VERSION ""

NS_ :

BS_:

BU_: IDC Delete_FDCA Delete_APA Delete_CMRR_FL Delete_CMRR_FR CMRR_RL CMRR_RR MRR CGW

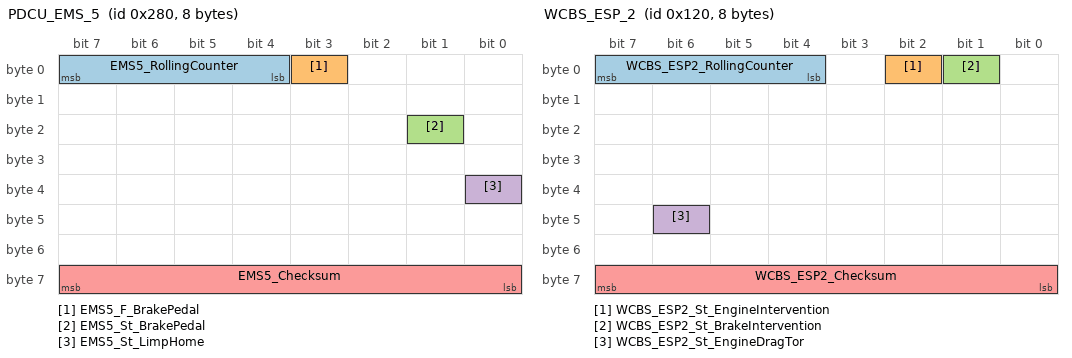
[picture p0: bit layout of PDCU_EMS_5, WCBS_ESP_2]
BO_ 640 PDCU_EMS_5: 8 CGW
 SG_ EMS5_RollingCounter : 7|4@0+ (1,0) [0|15] "" IDC,Delete_APA,Delete_CMRR_FL,Delete_CMRR_FR,CMRR_RL,CMRR_RR,MRR
 SG_ EMS5_F_BrakePedal : 3|1@0+ (1,0) [0|1] "" IDC,Delete_FDCA,Delete_APA,Delete_CMRR_FL,Delete_CMRR_FR,CMRR_RL,CMRR_RR,MRR
 SG_ EMS5_St_BrakePedal : 17|1@0+ (1,0) [0|1] "" IDC,Delete_FDCA,Delete_APA,Delete_CMRR_FL,Delete_CMRR_FR,CMRR_RL,CMRR_RR,MRR
 SG_ EMS5_St_LimpHome : 32|1@0+ (1,0) [0|1] "" IDC,Delete_FDCA
 SG_ EMS5_Checksum : 63|8@0+ (1,0) [0|255] "" IDC,Delete_APA,Delete_CMRR_FL,Delete_CMRR_FR,CMRR_RL,CMRR_RR,MRR

BO_ 792 WCBS_ESP_1: 8 CGW
 SG_ WCBS_ESP1_St_AutoHoldAvailable : 7|1@0+ (1,0) [0|1] "" IDC,Delete_FDCA,Delete_APA
 SG_ WCBS_ESP1_St_AutoHold : 6|1@0+ (1,0) [0|1] "" IDC,Delete_FDCA,Delete_APA
 SG_ WCBS_ESP1_St_AutoHoldTelltale : 5|1@0+ (1,0) [0|1] "" IDC,Delete_FDCA
 SG_ WCBS_ESP1_Cmd_EPBPark : 4|2@0+ (1,0) [0|3] "" IDC,Delete_APA
 SG_ WCBS_ESP1_St_TCSActive : 2|1@0+ (1,0) [0|1] "" IDC,Delete_FDCA,Delete_APA,Delete_CMRR_FL,Delete_CMRR_FR,CMRR_RL,CMRR_RR,MRR
 SG_ WCBS_ESP1_St_BrakeLightControl : 1|1@0+ (1,0) [0|1] "" IDC,Delete_APA
 SG_ WCBS_ESP1_St_ABSActive : 0|1@0+ (1,0) [0|1] "" IDC,Delete_FDCA,Delete_APA,Delete_CMRR_FL,Delete_CMRR_FR,CMRR_RL,CMRR_RR,MRR
 SG_ WCBS_ESP1_St_EBDActive : 15|1@0+ (1,0) [0|1] "" IDC,Delete_APA
 SG_ WCBS_ESP1_St_ESPFailureTelltale : 14|1@0+ (1,0) [0|1] "" IDC,Delete_APA,Delete_CMRR_FL,Delete_CMRR_FR,CMRR_RL,CMRR_RR,MRR
 SG_ WCBS_ESP1_St_ESPTCSOffTelltale : 13|2@0+ (1,0) [0|3] "" IDC,Delete_FDCA,Delete_APA,Delete_CMRR_FL,Delete_CMRR_FR,CMRR_RL,CMRR_RR,MRR
 SG_ WCBS_ESP1_St_DecelerationActive : 11|1@0+ (1,0) [0|1] "" IDC,Delete_FDCA
 SG_ WCBS_ESP1_St_ABSTelltale : 23|1@0+ (1,0) [0|1] "" IDC,Delete_FDCA
 SG_ WCBS_ESP1_St_EBDTelltale : 22|1@0+ (1,0) [0|1] "" IDC,Delete_FDCA
 SG_ WCBS_ESP1_St_ESPActive : 21|1@0+ (1,0) [0|1] "" IDC,Delete_FDCA,Delete_APA,Delete_CMRR_FL,Delete_CMRR_FR,CMRR_RL,CMRR_RR,MRR
 SG_ WCBS_ESP1_St_ESPTCSActiveTelltale : 20|1@0+ (1,0) [0|1] "" IDC,Delete_APA
 SG_ WCBS_ESP1_St_HDCTelltale : 17|2@0+ (1,0) [0|3] "" IDC,Delete_FDCA,Delete_APA,Delete_CMRR_FL,Delete_CMRR_FR,CMRR_RL,CMRR_RR,MRR
 SG_ WCBS_ESP1_N_OdometerRoll : 31|16@0+ (1,0) [0|65535] "pulses" IDC,Delete_APA
 SG_ WCBS_ESP1_St_WCBSFault : 47|2@0+ (1,0) [0|3] "" IDC,Delete_APA,Delete_CMRR_FL,Delete_CMRR_FR,CMRR_RL,CMRR_RR,MRR
 SG_ WCBS_ESP1_St_BrakeFluidW : 45|1@0+ (1,0) [0|1] "" IDC,Delete_APA
 SG_ WCBS_ESP1_RollingCounter : 55|4@0+ (1,0) [0|15] "" IDC,Delete_FDCA,Delete_APA,Delete_CMRR_FL,Delete_CMRR_FR,CMRR_RL,CMRR_RR,MRR
 SG_ WCBS_ESP1_Checksum : 63|8@0+ (1,0) [0|255] "" IDC,Delete_FDCA,Delete_APA,Delete_CMRR_FL,Delete_CMRR_FR,CMRR_RL,CMRR_RR,MRR

BO_ 288 WCBS_ESP_2: 8 CGW
 SG_ WCBS_ESP2_RollingCounter : 7|4@0+ (1,0) [0|15] "" IDC,Delete_FDCA
 SG_ WCBS_ESP2_St_EngineIntervention : 2|1@0+ (1,0) [0|1] "" IDC,Delete_FDCA
 SG_ WCBS_ESP2_St_BrakeIntervention : 1|1@0+ (1,0) [0|1] "" IDC,Delete_FDCA
 SG_ WCBS_ESP2_St_EngineDragTor : 46|1@0+ (1,0) [0|1] "" IDC,Delete_FDCA
 SG_ WCBS_ESP2_Checksum : 63|8@0+ (1,0) [0|255] "" IDC,Delete_FDCA

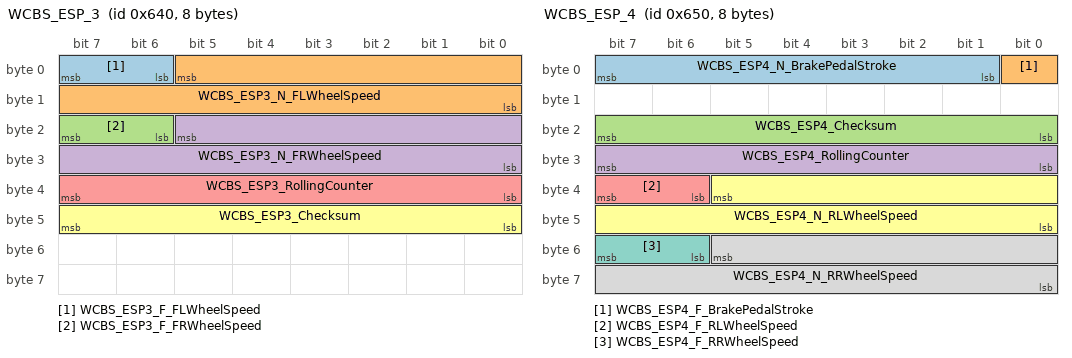
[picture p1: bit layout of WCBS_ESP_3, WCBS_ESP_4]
BO_ 1600 WCBS_ESP_3: 8 CGW
 SG_ WCBS_ESP3_F_FLWheelSpeed : 7|2@0+ (1,0) [0|3] "" IDC,Delete_FDCA,Delete_APA,Delete_CMRR_FL,Delete_CMRR_FR,CMRR_RL,CMRR_RR,MRR,Vector__XXX
 SG_ WCBS_ESP3_N_FLWheelSpeed : 5|14@0+ (0.0625,0) [0|300] "km/h" IDC,Delete_FDCA,Delete_APA,Delete_CMRR_FL,Delete_CMRR_FR,CMRR_RL,CMRR_RR,MRR,Vector__XXX
 SG_ WCBS_ESP3_F_FRWheelSpeed : 23|2@0+ (1,0) [0|3] "" IDC,Delete_FDCA,Delete_APA,Delete_CMRR_FL,Delete_CMRR_FR,CMRR_RL,CMRR_RR,MRR,Vector__XXX
 SG_ WCBS_ESP3_N_FRWheelSpeed : 21|14@0+ (0.0625,0) [0|300] "km/h" IDC,Delete_FDCA,Delete_APA,Delete_CMRR_FL,Delete_CMRR_FR,CMRR_RL,CMRR_RR,MRR,Vector__XXX
 SG_ WCBS_ESP3_RollingCounter : 39|8@0+ (1,0) [0|255] "" IDC,Delete_FDCA,Delete_APA,Delete_CMRR_FL,Delete_CMRR_FR,CMRR_RL,CMRR_RR,MRR,Vector__XXX
 SG_ WCBS_ESP3_Checksum : 47|8@0+ (1,0) [0|255] "" IDC,Delete_FDCA,Delete_APA,Delete_CMRR_FL,Delete_CMRR_FR,CMRR_RL,CMRR_RR,MRR,Vector__XXX

BO_ 1616 WCBS_ESP_4: 8 CGW
 SG_ WCBS_ESP4_N_BrakePedalStroke : 7|7@0+ (1,-5) [-5|108] "mm" IDC,Delete_FDCA,Delete_CMRR_FL,Delete_CMRR_FR,CMRR_RL,CMRR_RR,MRR
 SG_ WCBS_ESP4_F_BrakePedalStroke : 0|1@0+ (1,0) [0|1] "" IDC,Delete_FDCA,Delete_CMRR_FL,Delete_CMRR_FR,CMRR_RL,CMRR_RR,MRR
 SG_ WCBS_ESP4_Checksum : 23|8@0+ (1,0) [0|255] "" IDC,Delete_FDCA,Delete_APA,Delete_CMRR_FL,Delete_CMRR_FR,CMRR_RL,CMRR_RR,MRR,Vector__XXX
 SG_ WCBS_ESP4_RollingCounter : 31|8@0+ (1,0) [0|255] "" IDC,Delete_FDCA,Delete_APA,Delete_CMRR_FL,Delete_CMRR_FR,CMRR_RL,CMRR_RR,MRR,Vector__XXX
 SG_ WCBS_ESP4_F_RLWheelSpeed : 39|2@0+ (1,0) [0|3] "" IDC,Delete_FDCA,Delete_APA,Delete_CMRR_FL,Delete_CMRR_FR,CMRR_RL,CMRR_RR,MRR,Vector__XXX
 SG_ WCBS_ESP4_N_RLWheelSpeed : 37|14@0+ (0.0625,0) [0|300] "km/h" IDC,Delete_FDCA,Delete_APA,Delete_CMRR_FL,Delete_CMRR_FR,CMRR_RL,CMRR_RR,MRR,Vector__XXX
 SG_ WCBS_ESP4_F_RRWheelSpeed : 55|2@0+ (1,0) [0|3] "" IDC,Delete_FDCA,Delete_APA,Delete_CMRR_FL,Delete_CMRR_FR,CMRR_RL,CMRR_RR,MRR,Vector__XXX
 SG_ WCBS_ESP4_N_RRWheelSpeed : 53|14@0+ (0.0625,0) [0|300] "km/h" IDC,Delete_FDCA,Delete_APA,Delete_CMRR_FL,Delete_CMRR_FR,CMRR_RL,CMRR_RR,MRR,Vector__XXX

BO_ 785 WCBS_ESP_5: 8 CGW
 SG_ WCBS_ESP5_St_VehicleStandstill : 7|2@0+ (1,0) [0|3] "" IDC,Delete_FDCA,Delete_APA,Delete_CMRR_FL,Delete_CMRR_FR,CMRR_RL,CMRR_RR,MRR
 SG_ WCBS_ESP5_St_APAVLC : 5|4@0+ (1,0) [0|15] "" IDC,Delete_APA
 SG_ WCBS_ESP5_St_APACDDActive : 1|1@0+ (1,0) [0|1] "" IDC
 SG_ WCBS_ESP5_St_GearInhit : 0|1@0+ (1,0) [0|1] "" IDC,Delete_FDCA,Delete_APA
 SG_ WCBS_ESP5_RollingCounter : 12|4@0+ (1,0) [0|15] "" IDC,Delete_FDCA,Delete_APA,Delete_CMRR_FL,Delete_CMRR_FR,CMRR_RL,CMRR_RR,MRR
 SG_ WCBS_ESP5_F_VehicleSpeed : 8|1@0+ (1,0) [0|1] "" IDC,Delete_FDCA,Delete_APA,Delete_CMRR_FL,Delete_CMRR_FR,CMRR_RL,CMRR_RR,MRR
 SG_ WCBS_ESP5_St_APACDDAv : 23|1@0+ (1,0) [0|1] "" IDC,Delete_APA
 SG_ WCBS_ESP5_St_NoBrakeForce : 22|1@0+ (1,0) [0|1] "" IDC,Delete_FDCA
 SG_ WCBS_ESP5_St_ACCCDDActive : 21|1@0+ (1,0) [0|1] "" IDC,Delete_FDCA
 SG_ WCBS_ESP5_St_ACCCDDAv : 20|1@0+ (1,0) [0|1] "" IDC,Delete_FDCA
 SG_ WCBS_ESP5_St_ABAactive : 19|1@0+ (1,0) [0|1] "" IDC,Delete_FDCA
 SG_ WCBS_ESP5_St_ABAavailable : 18|1@0+ (1,0) [0|1] "" IDC,Delete_FDCA
 SG_ WCBS_ESP5_St_PrefillActive : 17|1@0+ (1,0) [0|1] "" IDC,Delete_FDCA,Delete_CMRR_FL,Delete_CMRR_FR,CMRR_RL,CMRR_RR,MRR
 SG_ WCBS_ESP5_St_PrefillAvailable : 16|1@0+ (1,0) [0|1] "" IDC,Delete_FDCA,Delete_CMRR_FL,Delete_CMRR_FR,CMRR_RL,CMRR_RR,MRR
 SG_ WCBS_ESP5_St_AEBdecActive : 31|1@0+ (1,0) [0|1] "" IDC,Delete_FDCA,Delete_CMRR_FL,Delete_CMRR_FR,CMRR_RL,CMRR_RR,MRR
 SG_ WCBS_ESP5_St_AEBdecAv : 30|1@0+ (1,0) [0|1] "" IDC,Delete_FDCA,Delete_CMRR_FL,Delete_CMRR_FR,CMRR_RL,CMRR_RR,MRR
 SG_ WCBS_ESP5_St_DecSupportAc : 29|1@0+ (1,0) [0|1] "" IDC,Delete_FDCA
 SG_ WCBS_ESP5_St_DecSupportAv : 28|1@0+ (1,0) [0|1] "" IDC,Delete_FDCA
 SG_ WCBS_ESP5_AWBactive : 27|1@0+ (1,0) [0|1] "" IDC,Delete_FDCA,Delete_CMRR_FL,Delete_CMRR_FR,CMRR_RL,CMRR_RR,MRR
 SG_ WCBS_ESP5_AWBavailable : 26|1@0+ (1,0) [0|1] "" IDC,Delete_FDCA,Delete_CMRR_FL,Delete_CMRR_FR,CMRR_RL,CMRR_RR,MRR
 SG_ WCBS_ESP5_QDCFail : 25|1@0+ (1,0) [0|1] "" IDC,Delete_FDCA
 SG_ WCBS_ESP5_BrakeOverheat : 24|1@0+ (1,0) [0|1] "" IDC,Delete_FDCA
 SG_ WCBS_ESP5_N_VehicleSpeed : 39|13@0+ (0.05625,0) [0|259.9875] "km/h" IDC,Delete_FDCA,Delete_APA,Delete_CMRR_FL,Delete_CMRR_FR,CMRR_RL,CMRR_RR,MRR
 SG_ WCBS_ESP5_St_APALCFailure : 42|3@0+ (1,0) [0|7] "bit" IDC,Delete_APA
 SG_ WCBS_ESP5_St_APAVLCAv : 55|1@0+ (1,0) [0|1] "" IDC,Delete_APA
 SG_ WCBS_ESP5_St_TCSOffTelltale : 48|1@0+ (1,0) [0|1] "" IDC,Delete_FDCA
 SG_ WCBS_ESP5_Checksum : 63|8@0+ (1,0) [0|255] "" IDC,Delete_FDCA,Delete_APA,Delete_CMRR_FL,Delete_CMRR_FR,CMRR_RL,CMRR_RR,MRR

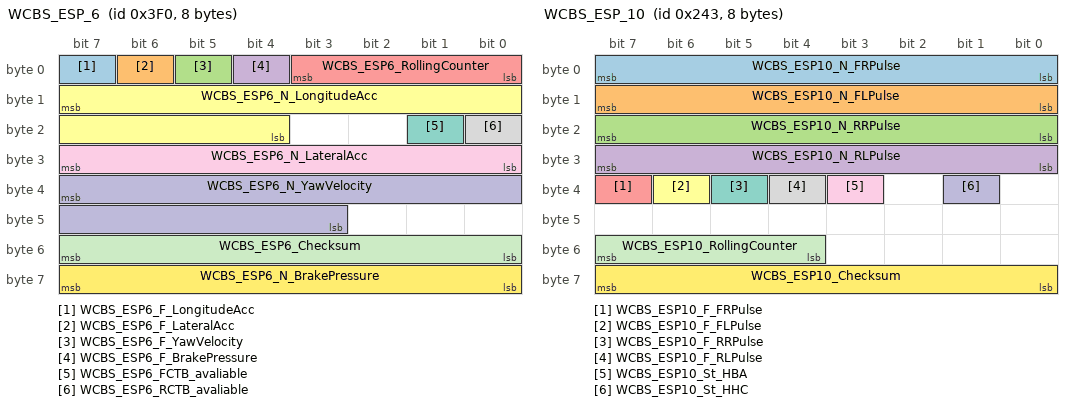
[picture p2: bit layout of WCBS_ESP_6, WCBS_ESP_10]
BO_ 1008 WCBS_ESP_6: 8 CGW
 SG_ WCBS_ESP6_F_LongitudeAcc : 7|1@0+ (1,0) [0|1] "" IDC,Delete_FDCA,Delete_APA,Delete_CMRR_FL,Delete_CMRR_FR,CMRR_RL,CMRR_RR,MRR
 SG_ WCBS_ESP6_F_LateralAcc : 6|1@0+ (1,0) [0|1] "" IDC,Delete_FDCA,Delete_APA,Delete_CMRR_FL,Delete_CMRR_FR,CMRR_RL,CMRR_RR,MRR
 SG_ WCBS_ESP6_F_YawVelocity : 5|1@0+ (1,0) [0|1] "" IDC,Delete_FDCA,Delete_APA,Delete_CMRR_FL,Delete_CMRR_FR,CMRR_RL,CMRR_RR,MRR
 SG_ WCBS_ESP6_F_BrakePressure : 4|1@0+ (1,0) [0|1] "" IDC,Delete_FDCA
 SG_ WCBS_ESP6_RollingCounter : 3|4@0+ (1,0) [0|15] "" IDC,Delete_FDCA,Delete_APA,Delete_CMRR_FL,Delete_CMRR_FR,CMRR_RL,CMRR_RR,MRR
 SG_ WCBS_ESP6_N_LongitudeAcc : 15|12@0+ (0.02,-25) [-25|25] "m/s2" IDC,Delete_FDCA,Delete_APA,Delete_CMRR_FL,Delete_CMRR_FR,CMRR_RL,CMRR_RR,MRR
 SG_ WCBS_ESP6_FCTB_avaliable : 17|1@0+ (1,0) [0|1] "" IDC,Delete_FDCA,Delete_CMRR_FL,Delete_CMRR_FR,CMRR_RL,CMRR_RR,MRR
 SG_ WCBS_ESP6_RCTB_avaliable : 16|1@0+ (1,0) [0|1] "" IDC,Delete_FDCA,Delete_CMRR_FL,Delete_CMRR_FR,CMRR_RL,CMRR_RR,MRR
 SG_ WCBS_ESP6_N_LateralAcc : 31|8@0+ (0.2,-25) [-25|25] "m/s2" IDC,Delete_FDCA,Delete_APA,Delete_CMRR_FL,Delete_CMRR_FR,CMRR_RL,CMRR_RR,MRR
 SG_ WCBS_ESP6_N_YawVelocity : 39|13@0+ (0.001,-2.5) [-2.5|2.5] "rad/s" IDC,Delete_FDCA,Delete_APA,Delete_CMRR_FL,Delete_CMRR_FR,CMRR_RL,CMRR_RR,MRR
 SG_ WCBS_ESP6_Checksum : 55|8@0+ (1,0) [0|255] "" IDC,Delete_FDCA,Delete_APA,Delete_CMRR_FL,Delete_CMRR_FR,CMRR_RL,CMRR_RR,MRR
 SG_ WCBS_ESP6_N_BrakePressure : 63|8@0+ (1,0) [0|255] "bar" IDC,Delete_FDCA,Delete_CMRR_FL,Delete_CMRR_FR,CMRR_RL,CMRR_RR,MRR

BO_ 579 WCBS_ESP_10: 8 CGW
 SG_ WCBS_ESP10_N_FRPulse : 7|8@0+ (1,0) [0|255] "" IDC,Delete_FDCA,Delete_APA,Delete_CMRR_FL,Delete_CMRR_FR,CMRR_RL,CMRR_RR,MRR
 SG_ WCBS_ESP10_N_FLPulse : 15|8@0+ (1,0) [0|255] "" IDC,Delete_FDCA,Delete_APA,Delete_CMRR_FL,Delete_CMRR_FR,CMRR_RL,CMRR_RR,MRR
 SG_ WCBS_ESP10_N_RRPulse : 23|8@0+ (1,0) [0|255] "" IDC,Delete_FDCA,Delete_APA,Delete_CMRR_FL,Delete_CMRR_FR,CMRR_RL,CMRR_RR,MRR
 SG_ WCBS_ESP10_N_RLPulse : 31|8@0+ (1,0) [0|255] "" IDC,Delete_FDCA,Delete_APA,Delete_CMRR_FL,Delete_CMRR_FR,CMRR_RL,CMRR_RR,MRR
 SG_ WCBS_ESP10_F_FRPulse : 39|1@0+ (1,0) [0|1] "" IDC,Delete_FDCA,Delete_APA,Delete_CMRR_FL,Delete_CMRR_FR,CMRR_RL,CMRR_RR,MRR
 SG_ WCBS_ESP10_F_FLPulse : 38|1@0+ (1,0) [0|1] "" IDC,Delete_FDCA,Delete_APA,Delete_CMRR_FL,Delete_CMRR_FR,CMRR_RL,CMRR_RR,MRR
 SG_ WCBS_ESP10_F_RRPulse : 37|1@0+ (1,0) [0|1] "" IDC,Delete_FDCA,Delete_APA,Delete_CMRR_FL,Delete_CMRR_FR,CMRR_RL,CMRR_RR,MRR
 SG_ WCBS_ESP10_F_RLPulse : 36|1@0+ (1,0) [0|1] "" IDC,Delete_FDCA,Delete_APA,Delete_CMRR_FL,Delete_CMRR_FR,CMRR_RL,CMRR_RR,MRR
 SG_ WCBS_ESP10_St_HBA : 35|1@0+ (1,0) [0|1] "" IDC
 SG_ WCBS_ESP10_St_HHC : 33|1@0+ (1,0) [0|1] "" IDC
 SG_ WCBS_ESP10_RollingCounter : 55|4@0+ (1,0) [0|15] "" IDC,Delete_FDCA,Delete_APA,Delete_CMRR_FL,Delete_CMRR_FR,CMRR_RL,CMRR_RR,MRR
 SG_ WCBS_ESP10_Checksum : 63|8@0+ (1,0) [0|255] "" IDC,Delete_FDCA,Delete_APA,Delete_CMRR_FL,Delete_CMRR_FR,CMRR_RL,CMRR_RR,MRR

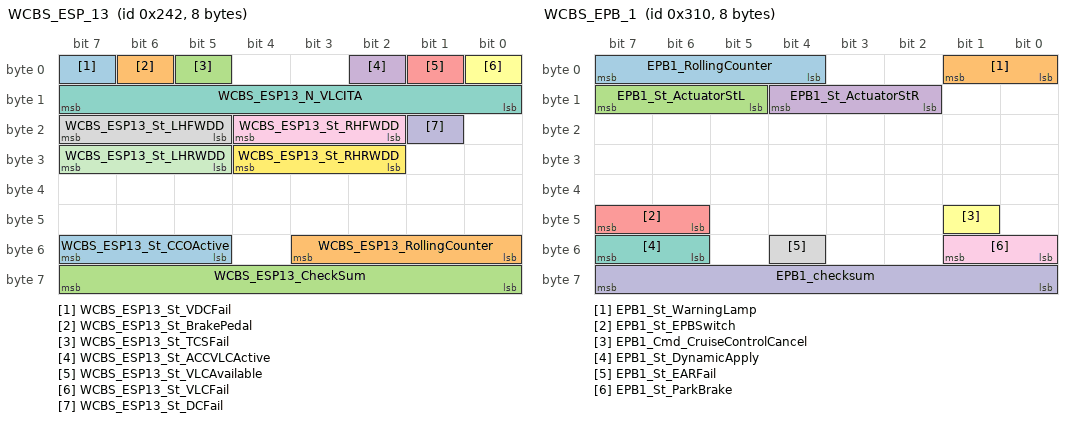
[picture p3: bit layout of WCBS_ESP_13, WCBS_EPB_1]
BO_ 578 WCBS_ESP_13: 8 CGW
 SG_ WCBS_ESP13_St_VDCFail : 7|1@0+ (1,0) [0|1] "" IDC,Delete_FDCA,Delete_CMRR_FL,Delete_CMRR_FR,CMRR_RL,CMRR_RR,MRR
 SG_ WCBS_ESP13_St_BrakePedal : 6|1@0+ (1,0) [0|1] "" IDC,Delete_FDCA,Delete_APA,Delete_CMRR_FL,Delete_CMRR_FR,CMRR_RL,CMRR_RR,MRR
 SG_ WCBS_ESP13_St_TCSFail : 5|1@0+ (1,0) [0|1] "" IDC,Delete_FDCA,Delete_CMRR_FL,Delete_CMRR_FR,CMRR_RL,CMRR_RR,MRR
 SG_ WCBS_ESP13_St_ACCVLCActive : 2|1@0+ (1,0) [0|1] "" IDC,Delete_FDCA
 SG_ WCBS_ESP13_St_VLCAvailable : 1|1@0+ (1,0) [0|1] "" IDC,Delete_FDCA
 SG_ WCBS_ESP13_St_VLCFail : 0|1@0+ (1,0) [0|1] "" IDC,Delete_FDCA
 SG_ WCBS_ESP13_N_VLCITA : 15|8@0+ (0.05,-7) [-7|5.75] "m/s^2" IDC,Delete_FDCA
 SG_ WCBS_ESP13_St_LHFWDD : 23|3@0+ (1,0) [0|7] "" IDC,Delete_FDCA,Delete_APA,Delete_CMRR_FL,Delete_CMRR_FR,CMRR_RL,CMRR_RR,MRR
 SG_ WCBS_ESP13_St_RHFWDD : 20|3@0+ (1,0) [0|7] "" IDC,Delete_FDCA,Delete_APA,Delete_CMRR_FL,Delete_CMRR_FR,CMRR_RL,CMRR_RR,MRR
 SG_ WCBS_ESP13_St_DCFail : 17|1@0+ (1,0) [0|1] "" IDC,Delete_FDCA
 SG_ WCBS_ESP13_St_LHRWDD : 31|3@0+ (1,0) [0|7] "" IDC,Delete_FDCA,Delete_APA,Delete_CMRR_FL,Delete_CMRR_FR,CMRR_RL,CMRR_RR,MRR
 SG_ WCBS_ESP13_St_RHRWDD : 28|3@0+ (1,0) [0|7] "" IDC,Delete_FDCA,Delete_APA,Delete_CMRR_FL,Delete_CMRR_FR,CMRR_RL,CMRR_RR,MRR
 SG_ WCBS_ESP13_St_CCOActive : 55|3@0+ (1,0) [0|7] "" IDC,Delete_FDCA,Delete_APA
 SG_ WCBS_ESP13_RollingCounter : 51|4@0+ (1,0) [0|15] "" IDC,Delete_FDCA,Delete_APA,Delete_CMRR_FL,Delete_CMRR_FR,CMRR_RL,CMRR_RR,MRR
 SG_ WCBS_ESP13_CheckSum : 63|8@0+ (1,0) [0|255] "" IDC,Delete_FDCA,Delete_APA,Delete_CMRR_FL,Delete_CMRR_FR,CMRR_RL,CMRR_RR,MRR

BO_ 784 WCBS_EPB_1: 8 CGW
 SG_ EPB1_RollingCounter : 7|4@0+ (1,0) [0|15] "" IDC,Delete_APA
 SG_ EPB1_St_WarningLamp : 1|2@0+ (1,0) [0|3] "" IDC,Delete_FDCA
 SG_ EPB1_St_ActuatorStL : 15|3@0+ (1,0) [0|7] "" IDC,Delete_FDCA
 SG_ EPB1_St_ActuatorStR : 12|3@0+ (1,0) [0|7] "" IDC,Delete_FDCA
 SG_ EPB1_St_EPBSwitch : 47|2@0+ (1,0) [0|3] "" IDC,Delete_APA
 SG_ EPB1_Cmd_CruiseControlCancel : 41|1@0+ (1,0) [0|1] "" IDC,Delete_FDCA
 SG_ EPB1_St_DynamicApply : 55|2@0+ (1,0) [0|3] "" IDC
 SG_ EPB1_St_EARFail : 52|1@0+ (1,0) [0|1] "" IDC,Delete_APA
 SG_ EPB1_St_ParkBrake : 49|2@0+ (1,0) [0|3] "" IDC,Delete_FDCA,Delete_APA
 SG_ EPB1_checksum : 63|8@0+ (1,0) [0|255] "" IDC,Delete_APA

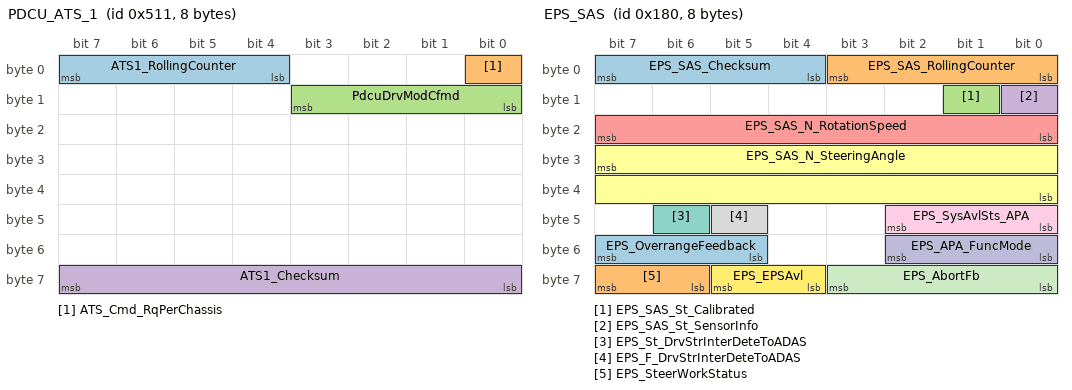
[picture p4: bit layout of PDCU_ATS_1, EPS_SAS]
BO_ 1297 PDCU_ATS_1: 8 CGW
 SG_ ATS1_RollingCounter : 7|4@0+ (1,0) [0|15] "" IDC,Delete_FDCA,Delete_APA
 SG_ ATS_Cmd_RqPerChassis : 0|1@0+ (1,0) [0|1] "" IDC,Delete_APA
 SG_ PdcuDrvModCfmd : 11|4@0+ (1,0) [0|15] "" IDC,Delete_FDCA,Delete_APA
 SG_ ATS1_Checksum : 63|8@0+ (1,0) [0|255] "" IDC,Delete_FDCA,Delete_APA

BO_ 384 EPS_SAS: 8 CGW
 SG_ EPS_SAS_Checksum : 7|4@0+ (1,0) [0|15] "" IDC,Delete_FDCA,Delete_APA,Delete_CMRR_FL,Delete_CMRR_FR,CMRR_RL,CMRR_RR,MRR
 SG_ EPS_SAS_RollingCounter : 3|4@0+ (1,0) [0|15] "" IDC,Delete_FDCA,Delete_APA,Delete_CMRR_FL,Delete_CMRR_FR,CMRR_RL,CMRR_RR,MRR
 SG_ EPS_SAS_St_Calibrated : 9|1@0+ (1,0) [0|1] "" IDC,Delete_FDCA,Delete_APA,Delete_CMRR_FL,Delete_CMRR_FR,CMRR_RL,CMRR_RR,MRR
 SG_ EPS_SAS_St_SensorInfo : 8|1@0+ (1,0) [0|1] "" IDC,Delete_FDCA,Delete_APA,Delete_CMRR_FL,Delete_CMRR_FR,CMRR_RL,CMRR_RR,MRR
 SG_ EPS_SAS_N_RotationSpeed : 23|8@0+ (4,0) [0|1016] "degree/ sec" IDC,Delete_FDCA,Delete_APA,Delete_CMRR_FL,Delete_CMRR_FR,CMRR_RL,CMRR_RR,MRR
 SG_ EPS_SAS_N_SteeringAngle : 31|16@0+ (0.1,-780) [-780|780] "degree" IDC,Delete_FDCA,Delete_APA,Delete_CMRR_FL,Delete_CMRR_FR,CMRR_RL,CMRR_RR,MRR
 SG_ EPS_St_DrvStrInterDeteToADAS : 46|1@0+ (1,0) [0|1] "" IDC,Delete_FDCA
 SG_ EPS_F_DrvStrInterDeteToADAS : 45|1@0+ (1,0) [0|1] "" IDC,Delete_FDCA
 SG_ EPS_SysAvlSts_APA : 42|3@0+ (1,0) [0|7] "" IDC
 SG_ EPS_APA_FuncMode : 50|3@0+ (1,0) [0|7] "" IDC
 SG_ EPS_AbortFb : 59|4@0+ (1,0) [0|15] "" IDC
 SG_ EPS_EPSAvl : 61|2@0+ (1,0) [0|3] "" IDC
 SG_ EPS_OverrangeFeedback : 55|3@0+ (1,0) [0|7] "" IDC
 SG_ EPS_SteerWorkStatus : 63|2@0+ (1,0) [0|3] "" IDC

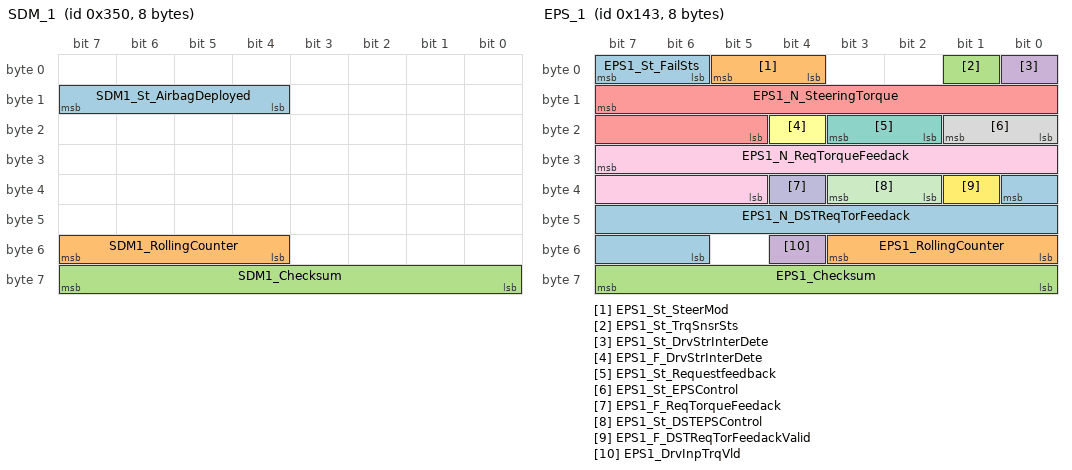
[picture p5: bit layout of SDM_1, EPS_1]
BO_ 848 SDM_1: 8 CGW
 SG_ SDM1_St_AirbagDeployed : 15|4@0+ (1,0) [0|15] "" IDC,Delete_FDCA
 SG_ SDM1_RollingCounter : 55|4@0+ (1,0) [0|15] "" IDC,Delete_FDCA
 SG_ SDM1_Checksum : 63|8@0+ (1,0) [0|255] "" IDC,Delete_FDCA

BO_ 323 EPS_1: 8 CGW
 SG_ EPS1_St_FailSts : 7|2@0+ (1,0) [0|3] "" IDC
 SG_ EPS1_St_SteerMod : 5|2@0+ (1,0) [0|3] "" IDC,Delete_FDCA
 SG_ EPS1_St_TrqSnsrSts : 1|1@0+ (1,0) [0|1] "" IDC,Delete_FDCA
 SG_ EPS1_St_DrvStrInterDete : 0|1@0+ (1,0) [0|1] "bit" IDC,Delete_APA
 SG_ EPS1_N_SteeringTorque : 15|11@0+ (0.01,-7.11) [-7.11|7.11] "Nm" IDC,Delete_FDCA,Delete_APA
 SG_ EPS1_F_DrvStrInterDete : 20|1@0+ (1,0) [0|1] "bit" IDC,Delete_APA
 SG_ EPS1_St_Requestfeedback : 19|2@0+ (1,0) [0|3] "bit" IDC,Delete_APA
 SG_ EPS1_St_EPSControl : 17|2@0+ (1,0) [0|3] "" IDC,Delete_FDCA
 SG_ EPS1_N_ReqTorqueFeedack : 31|11@0+ (0.01,-10.24) [-10.24|10.23] "" IDC,Delete_FDCA
 SG_ EPS1_F_ReqTorqueFeedack : 36|1@0+ (1,0) [0|1] "" IDC,Delete_FDCA
 SG_ EPS1_St_DSTEPSControl : 35|2@0+ (1,0) [0|3] "" IDC,Delete_FDCA
 SG_ EPS1_F_DSTReqTorFeedackValid : 33|1@0+ (1,0) [0|1] "" IDC,Delete_FDCA
 SG_ EPS1_N_DSTReqTorFeedack : 32|11@0+ (0.01,-10.24) [-10.24|10.23] "" IDC,Delete_FDCA
 SG_ EPS1_RollingCounter : 51|4@0+ (1,0) [0|15] "" IDC,Delete_FDCA,Delete_APA
 SG_ EPS1_Checksum : 63|8@0+ (1,0) [0|255] "" IDC,Delete_FDCA,Delete_APA
 SG_ EPS1_DrvInpTrqVld : 52|1@0+ (1,0) [0|1] "" IDC,Delete_FDCA,Delete_APA

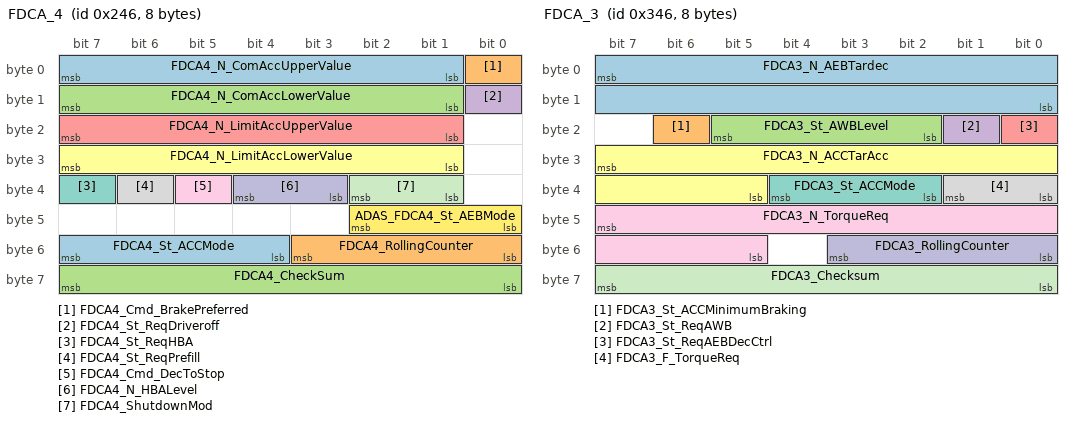
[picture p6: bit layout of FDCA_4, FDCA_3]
BO_ 582 FDCA_4: 8 IDC
 SG_ FDCA4_N_ComAccUpperValue : 7|7@0+ (0.025,0) [0|3.125] "m/s^2" CGW
 SG_ FDCA4_Cmd_BrakePreferred : 0|1@0+ (1,0) [0|1] "" CGW
 SG_ FDCA4_N_ComAccLowerValue : 15|7@0+ (0.025,0) [0|3.125] "m/s^2" CGW
 SG_ FDCA4_St_ReqDriveroff : 8|1@0+ (1,0) [0|1] "" CGW
 SG_ FDCA4_N_LimitAccUpperValue : 23|7@0+ (0.1,0) [0|12.7] "m/s^3" CGW
 SG_ FDCA4_N_LimitAccLowerValue : 31|7@0+ (0.1,-12.7) [-12.7|0] "m/s^3" CGW
 SG_ FDCA4_St_ReqHBA : 39|1@0+ (1,0) [0|1] "" CGW
 SG_ FDCA4_St_ReqPrefill : 38|1@0+ (1,0) [0|1] "" CGW
 SG_ FDCA4_Cmd_DecToStop : 37|1@0+ (1,0) [0|1] "" CGW
 SG_ FDCA4_N_HBALevel : 36|2@0+ (1,0) [0|3] "" CGW
 SG_ FDCA4_ShutdownMod : 34|2@0+ (1,0) [0|3] "" CGW
 SG_ ADAS_FDCA4_St_AEBMode : 42|3@0+ (1,0) [0|7] "" Delete_APA,CGW
 SG_ FDCA4_St_ACCMode : 55|4@0+ (1,0) [0|15] "" CGW
 SG_ FDCA4_RollingCounter : 51|4@0+ (1,0) [0|15] "" Delete_APA,CGW
 SG_ FDCA4_CheckSum : 63|8@0+ (1,0) [0|255] "" Delete_APA,CGW

BO_ 838 FDCA_3: 8 IDC
 SG_ FDCA3_N_AEBTardec : 7|16@0+ (0.0004882,-16) [-16|15.994187] "m/s^2" CGW
 SG_ FDCA3_St_ACCMinimumBraking : 22|1@0+ (1,0) [0|1] "" CGW
 SG_ FDCA3_St_AWBLevel : 21|4@0+ (1,0) [0|15] "" CGW
 SG_ FDCA3_St_ReqAWB : 17|1@0+ (1,0) [0|1] "" CGW
 SG_ FDCA3_St_ReqAEBDecCtrl : 16|1@0+ (1,0) [0|1] "" CGW
 SG_ FDCA3_N_ACCTarAcc : 31|11@0+ (0.005,-5) [-5|5.235] "m/s^2" CGW
 SG_ FDCA3_St_ACCMode : 36|3@0+ (1,0) [0|7] "" CGW
 SG_ FDCA3_F_TorqueReq : 33|2@0+ (1,0) [0|3] "" CGW
 SG_ FDCA3_N_TorqueReq : 47|11@0+ (0.01,-10.24) [-10.24|10.23] "Nm" CGW
 SG_ FDCA3_RollingCounter : 51|4@0+ (1,0) [0|15] "" CGW
 SG_ FDCA3_Checksum : 63|8@0+ (1,0) [0|255] "" CGW

BO_ 816 CSS_1: 8 CGW
 SG_ CSS1_F_AVMSw : 25|1@0+ (1,0) [0|1] "" IDC,Delete_APA
 SG_ CSS1_Sw_AVM : 24|1@0+ (1,0) [0|1] "" IDC,Delete_APA

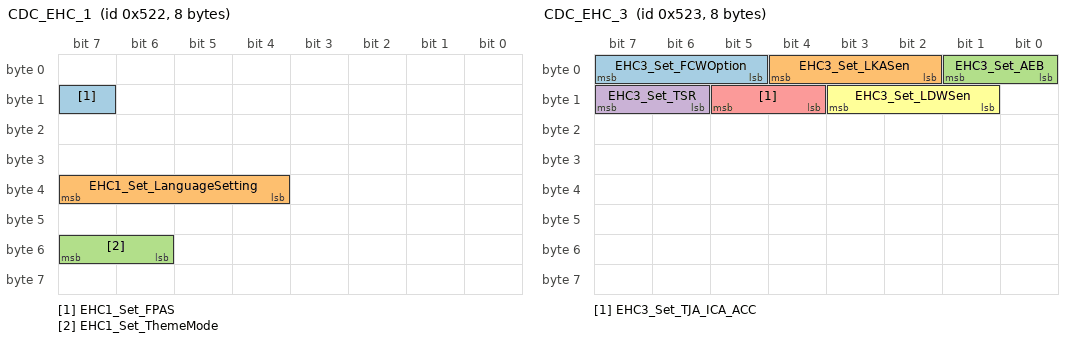
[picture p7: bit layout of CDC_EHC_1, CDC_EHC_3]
BO_ 1314 CDC_EHC_1: 8 CGW
 SG_ EHC1_Set_FPAS : 15|1@0+ (1,0) [0|1] "" IDC,Delete_APA
 SG_ EHC1_Set_LanguageSetting : 39|4@0+ (1,0) [0|15] "" IDC,Delete_APA
 SG_ EHC1_Set_ThemeMode : 55|2@0+ (1,0) [0|3] "" IDC,Delete_APA

BO_ 1315 CDC_EHC_3: 8 CGW
 SG_ EHC3_Set_FCWOption : 7|3@0+ (1,0) [0|7] "" IDC,Delete_FDCA
 SG_ EHC3_Set_LKASen : 4|3@0+ (1,0) [0|7] "" IDC,Delete_FDCA
 SG_ EHC3_Set_AEB : 1|2@0+ (1,0) [0|3] "" IDC,Delete_FDCA
 SG_ EHC3_Set_TSR : 15|2@0+ (1,0) [0|3] "" IDC,Delete_FDCA
 SG_ EHC3_Set_TJA_ICA_ACC : 13|2@0+ (1,0) [0|3] "" IDC,Delete_FDCA
 SG_ EHC3_Set_LDWSen : 11|3@0+ (1,0) [0|7] "" IDC,Delete_FDCA

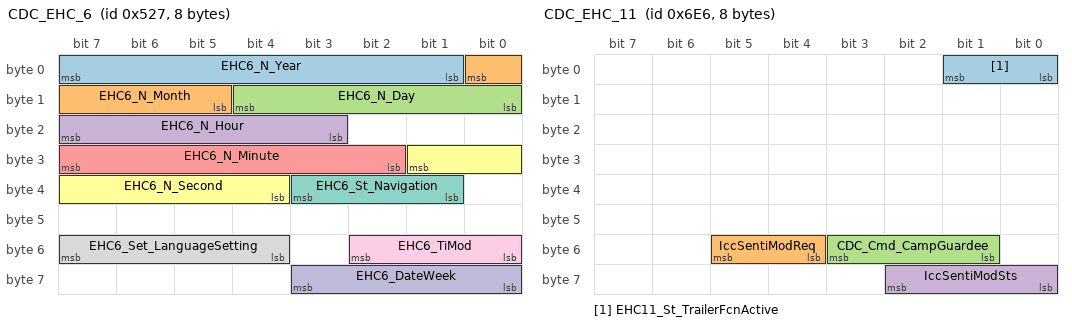
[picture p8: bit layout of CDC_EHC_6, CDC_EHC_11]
BO_ 1319 CDC_EHC_6: 8 CGW
 SG_ EHC6_N_Year : 7|7@0+ (1,2000) [2000|2127] "" IDC,Delete_FDCA,Delete_APA,Delete_CMRR_FL,Delete_CMRR_FR,CMRR_RL,CMRR_RR,MRR
 SG_ EHC6_N_Month : 0|4@0+ (1,0) [0|12] "" IDC,Delete_FDCA,Delete_APA,Delete_CMRR_FL,Delete_CMRR_FR,CMRR_RL,CMRR_RR,MRR
 SG_ EHC6_N_Day : 12|5@0+ (1,0) [0|31] "" IDC,Delete_FDCA,Delete_APA,Delete_CMRR_FL,Delete_CMRR_FR,CMRR_RL,CMRR_RR,MRR
 SG_ EHC6_N_Hour : 23|5@0+ (1,0) [0|24] "h" IDC,Delete_FDCA,Delete_APA,Delete_CMRR_FL,Delete_CMRR_FR,CMRR_RL,CMRR_RR,MRR
 SG_ EHC6_N_Minute : 31|6@0+ (1,0) [0|60] "M" IDC,Delete_FDCA,Delete_APA,Delete_CMRR_FL,Delete_CMRR_FR,CMRR_RL,CMRR_RR,MRR
 SG_ EHC6_N_Second : 25|6@0+ (1,0) [0|60] "S" IDC,Delete_FDCA,Delete_APA,Delete_CMRR_FL,Delete_CMRR_FR,CMRR_RL,CMRR_RR,MRR
 SG_ EHC6_St_Navigation : 35|3@0+ (1,0) [0|7] "" IDC,Delete_FDCA,Delete_APA
 SG_ EHC6_Set_LanguageSetting : 55|4@0+ (1,0) [0|15] "" IDC,Delete_APA
 SG_ EHC6_TiMod : 50|3@0+ (1,0) [0|7] "" IDC,Delete_FDCA
 SG_ EHC6_DateWeek : 59|4@0+ (1,0) [0|15] "" IDC,Delete_FDCA

BO_ 1766 CDC_EHC_11: 8 CGW
 SG_ EHC11_St_TrailerFcnActive : 1|2@0+ (1,0) [0|3] "" IDC,Delete_FDCA,Delete_APA,Delete_CMRR_FL,Delete_CMRR_FR,CMRR_RL,CMRR_RR,MRR
 SG_ IccSentiModReq : 53|2@0+ (1,0) [0|3] "" IDC,Delete_APA
 SG_ CDC_Cmd_CampGuardee : 51|3@0+ (1,0) [0|7] "" IDC,Delete_APA
 SG_ IccSentiModSts : 58|3@0+ (1,0) [0|7] "" IDC,Delete_APA

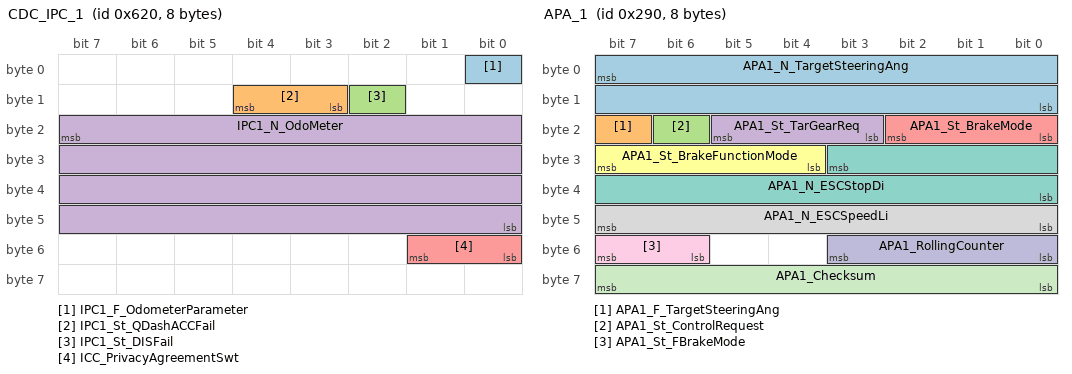
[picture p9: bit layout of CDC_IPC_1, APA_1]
BO_ 1568 CDC_IPC_1: 8 CGW
 SG_ IPC1_F_OdometerParameter : 0|1@0+ (1,0) [0|1] "" IDC,Delete_FDCA,Delete_APA
 SG_ IPC1_St_QDashACCFail : 12|2@0+ (1,0) [0|3] "" IDC,Delete_FDCA
 SG_ IPC1_St_DISFail : 10|1@0+ (1,0) [0|1] "" IDC,Delete_FDCA
 SG_ IPC1_N_OdoMeter : 23|32@0+ (0.01,0) [0|2000000] "km" IDC,Delete_FDCA,Delete_APA,Delete_CMRR_FL,Delete_CMRR_FR,CMRR_RL,CMRR_RR,MRR
 SG_ ICC_PrivacyAgreementSwt : 49|2@0+ (1,0) [0|1] "" IDC

BO_ 656 APA_1: 8 IDC
 SG_ APA1_N_TargetSteeringAng : 7|16@0+ (0.1,-780) [-780|780] "degree" CGW
 SG_ APA1_F_TargetSteeringAng : 23|1@0+ (1,0) [0|1] "bit" CGW
 SG_ APA1_St_ControlRequest : 22|1@0+ (1,0) [0|1] "bit" CGW
 SG_ APA1_St_TarGearReq : 21|3@0+ (1,0) [0|7] "bit" CGW
 SG_ APA1_St_BrakeMode : 18|3@0+ (1,0) [0|7] "bit" CGW
 SG_ APA1_St_BrakeFunctionMode : 31|4@0+ (1,0) [0|15] "bit" CGW
 SG_ APA1_N_ESCStopDi : 27|12@0+ (1,0) [0|4095] "cm/bit" CGW
 SG_ APA1_N_ESCSpeedLi : 47|8@0+ (0.1,0) [0|25.5] "km/h/bit" CGW
 SG_ APA1_St_FBrakeMode : 55|2@0+ (1,0) [0|3] "bit" CGW
 SG_ APA1_RollingCounter : 51|4@0+ (1,0) [0|15] "bit" CGW
 SG_ APA1_Checksum : 63|8@0+ (1,0) [0|255] "bit" CGW

BO_ 657 APA_2: 8 IDC
 SG_ APA2_St_AutoParkingIn : 7|1@0+ (1,0) [0|1] "bit" CGW
 SG_ APA2_St_AutoParkingOut : 6|1@0+ (1,0) [0|1] "bit" CGW
 SG_ APA2_St_UserSlot : 5|1@0+ (1,0) [0|1] "bit" CGW
 SG_ APA2_St_Set : 4|1@0+ (1,0) [0|1] "bit" CGW
 SG_ APA2_St_ParkOutDirSet : 3|4@0+ (1,0) [0|15] "bit" CGW
 SG_ APA2_RPA_RpaSts : 15|4@0+ (1,0) [0|15] "" CGW
 SG_ APA2_St_Preference : 23|2@0+ (1,0) [0|3] "bit" CGW
 SG_ APA2_St_ParkingInMode : 21|2@0+ (1,0) [0|3] "bit" CGW
 SG_ APA2_St_ParkingInPreCon : 19|1@0+ (1,0) [0|1] "bit" CGW
 SG_ APA2_St_APAStatus : 18|3@0+ (1,0) [0|7] "bit" Delete_FDCA,CGW
 SG_ APA2_St_ParkingOutDirection : 28|2@0+ (1,0) [0|3] "bit" CGW
 SG_ APA2_St_SelectedParkOutDire : 26|2@0+ (1,0) [0|3] "bit" CGW
 SG_ APA2_St_DirHalfLeAvl : 39|1@0+ (1,0) [0|1] "bit" CGW
 SG_ APA2_St_DirHalfRiAvl : 38|1@0+ (1,0) [0|1] "bit" CGW
 SG_ APA2_St_DirHozlFwAvl : 37|1@0+ (1,0) [0|1] "bit" CGW
 SG_ APA2_St_DirHozlBwAvl : 36|1@0+ (1,0) [0|1] "bit" CGW
 SG_ APA2_St_DirVertHdLeAvl : 35|1@0+ (1,0) [0|1] "bit" CGW
 SG_ APA2_St_DirVertHdRiAvl : 34|1@0+ (1,0) [0|1] "bit" CGW
 SG_ APA2_St_DirVertTrLeAvl : 33|1@0+ (1,0) [0|1] "bit" CGW
 SG_ APA2_St_DirVertTrRiAvl : 32|1@0+ (1,0) [0|1] "bit" CGW
 SG_ APA2_St_Request : 47|5@0+ (1,0) [0|31] "bit" CGW
 SG_ APA2_RollingCounter : 51|4@0+ (1,0) [0|15] "bit" CGW
 SG_ APA2_Checksum : 63|8@0+ (1,0) [0|255] "bit" CGW

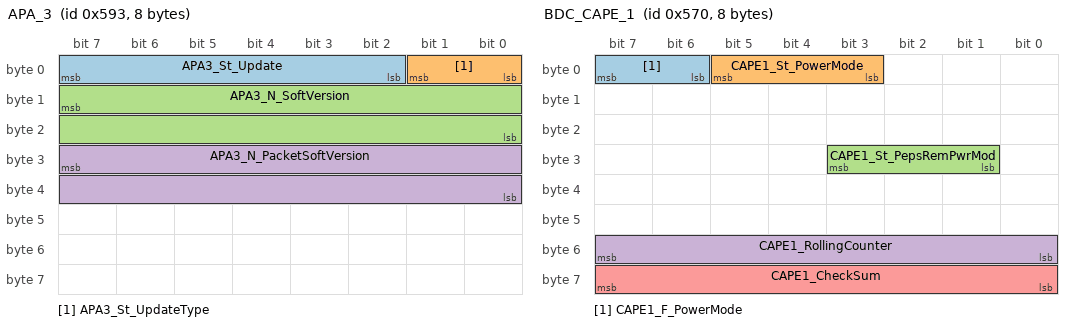
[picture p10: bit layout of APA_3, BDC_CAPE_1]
BO_ 1427 APA_3: 8 IDC
 SG_ APA3_St_Update : 7|6@0+ (1,0) [0|63] "bit" CGW
 SG_ APA3_St_UpdateType : 1|2@0+ (1,0) [0|3] "" CGW
 SG_ APA3_N_SoftVersion : 15|16@0+ (1,0) [0|65535] "bit" CGW
 SG_ APA3_N_PacketSoftVersion : 31|16@0+ (1,0) [0|65535] "bit" CGW

BO_ 917 APA_AVM_2: 8 IDC
 SG_ AVM2_St_WormModeView : 7|1@0+ (1,0) [0|1] "" CGW
 SG_ AVM2_St_RockModeView : 6|1@0+ (1,0) [0|1] "" CGW
 SG_ AVM2_St_CurrViewType : 5|4@0+ (1,0) [0|15] "" CGW
 SG_ AVM2_St_Mode : 1|1@0+ (1,0) [0|1] "" CGW
 SG_ AVM2_St_PerspectiveChassis : 0|1@0+ (1,0) [0|1] "" CGW
 SG_ AVM2_St_QuitAvmEnable : 15|1@0+ (1,0) [0|1] "" CGW
 SG_ AVM2_St_ModeSwitchEnable : 14|1@0+ (1,0) [0|1] "" CGW
 SG_ AVM2_St_PerspectiveEnable : 13|1@0+ (1,0) [0|1] "" CGW
 SG_ AVM2_St_MoreViewEnable : 12|1@0+ (1,0) [0|1] "" CGW
 SG_ AVM2_St_SettingEnable : 11|1@0+ (1,0) [0|1] "" CGW
 SG_ AVM2_St_WormEnable : 10|1@0+ (1,0) [0|1] "" CGW
 SG_ AVM2_St_RockEnable : 9|1@0+ (1,0) [0|1] "" CGW
 SG_ AVM2_St_Reseved : 8|1@0+ (1,0) [0|1] "" CGW
 SG_ AVM2_Set_TireTrajectory : 23|1@0+ (1,0) [0|1] "" CGW
 SG_ AVM2_Set_CarTrajectory : 22|1@0+ (1,0) [0|1] "" CGW
 SG_ AVM2_Set_2DRadar : 21|1@0+ (1,0) [0|1] "" CGW
 SG_ AVM2_Set_3DRadar : 20|1@0+ (1,0) [0|1] "" CGW
 SG_ AVM2_Set_TurnTriggerView : 19|1@0+ (1,0) [0|1] "" CGW
 SG_ AVM2_Set_RadarTriggerView : 18|1@0+ (1,0) [0|1] "" CGW
 SG_ AVM2_Error_Controller : 17|1@0+ (1,0) [0|1] "" CGW
 SG_ AVM2_Error_ViewOutput : 16|1@0+ (1,0) [0|1] "" CGW
 SG_ AvmVehLctSts : 42|3@0+ (1,0) [0|7] "" CGW
 SG_ AVM2_Set_CarColor : 34|3@0+ (1,0) [0|7] "" CGW
 SG_ AVM2_St_MoreViews : 47|3@0+ (1,0) [0|7] "" CGW
 SG_ AVM2_St_CSSLight : 44|1@0+ (1,0) [0|1] "" CGW
 SG_ AVM2_St_RestoreSetting : 43|1@0+ (1,0) [0|1] "" CGW
 SG_ AVM2_St_PromptMessage : 55|9@0+ (1,0) [0|511] "" CGW
 SG_ AVM2_St_PromptTimeOut : 62|7@0+ (1,0) [0|127] "" CGW
 SG_ FrntcamFaild : 24|1@0+ (1,0) [0|1] "" CGW
 SG_ RecamFaild : 25|1@0+ (1,0) [0|1] "" CGW
 SG_ LecamFaild : 26|1@0+ (1,0) [0|1] "" CGW
 SG_ RicamFaild : 27|1@0+ (1,0) [0|1] "" CGW
 SG_ AvmCtrlrFaild : 30|3@0+ (1,0) [0|7] "" CGW
 SG_ AvmSts : 39|3@0+ (1,0) [0|7] "" CGW

BO_ 1392 BDC_CAPE_1: 8 CGW
 SG_ CAPE1_F_PowerMode : 7|2@0+ (1,0) [0|2] "" IDC,Delete_FDCA,Delete_APA,Delete_CMRR_FL,Delete_CMRR_FR,CMRR_RL,CMRR_RR,MRR
 SG_ CAPE1_St_PowerMode : 5|3@0+ (1,0) [0|7] "" IDC,Delete_FDCA,Delete_APA,Delete_CMRR_FL,Delete_CMRR_FR,CMRR_RL,CMRR_RR,MRR
 SG_ CAPE1_St_PepsRemPwrMod : 27|3@0+ (1,0) [0|7] "" IDC,Delete_APA
 SG_ CAPE1_RollingCounter : 55|8@0+ (1,0) [0|255] "" IDC,Delete_APA,Delete_CMRR_FL,Delete_CMRR_FR,CMRR_RL,CMRR_RR,MRR
 SG_ CAPE1_CheckSum : 63|8@0+ (1,0) [0|255] "" IDC,Delete_APA,Delete_CMRR_FL,Delete_CMRR_FR,CMRR_RL,CMRR_RR,MRR

BO_ 1184 BDC_BCM_1: 8 CGW
 SG_ BCM1_Cmd_PositionLamp : 15|1@0+ (1,0) [0|1] "" IDC,Delete_APA
 SG_ BCM1_Sw_TurnLeftLamp : 11|1@0+ (1,0) [0|1] "" IDC,Delete_FDCA,Delete_CMRR_FL,Delete_CMRR_FR,CMRR_RL,CMRR_RR,MRR
 SG_ BCM1_Sw_TurnRightLamp : 10|1@0+ (1,0) [0|1] "" IDC,Delete_FDCA,Delete_CMRR_FL,Delete_CMRR_FR,CMRR_RL,CMRR_RR,MRR
 SG_ BCM1_St_HazzardFlash : 9|1@0+ (1,0) [0|1] "" IDC,Delete_FDCA
 SG_ BCM1_St_HighBeam : 8|1@0+ (1,0) [0|1] "" IDC,Delete_FDCA,Delete_APA
 SG_ BCM1_Cmd_LeftTurnLamp : 23|1@0+ (1,0) [0|1] "" IDC,Delete_FDCA,Delete_APA
 SG_ BCM1_St_LeftTurnLamp : 22|1@0+ (1,0) [0|1] "" IDC,Delete_FDCA,Delete_APA,Delete_CMRR_FL,Delete_CMRR_FR,CMRR_RL,CMRR_RR,MRR
 SG_ BCM1_Cmd_RightTurnLamp : 21|1@0+ (1,0) [0|1] "" IDC,Delete_FDCA,Delete_APA
 SG_ BCM1_St_RightTurnLamp : 20|1@0+ (1,0) [0|1] "" IDC,Delete_FDCA,Delete_APA,Delete_CMRR_FL,Delete_CMRR_FR,CMRR_RL,CMRR_RR,MRR
 SG_ BCM1_St_PositionLamp : 19|1@0+ (1,0) [0|1] "" IDC,Delete_APA
 SG_ BCM1_St_AntiThelfIndication : 18|3@0+ (1,0) [0|7] "" IDC,Delete_FDCA,Delete_CMRR_FL,Delete_CMRR_FR,CMRR_RL,CMRR_RR,MRR
 SG_ BCM1_St_LFDoorLock : 31|1@0+ (1,0) [0|1] "" IDC,Delete_APA,Delete_CMRR_FL,Delete_CMRR_FR,CMRR_RL,CMRR_RR,MRR
 SG_ BCM1_St_PasDoorLock : 30|1@0+ (1,0) [0|1] "" IDC,Delete_APA,Delete_CMRR_FL,Delete_CMRR_FR,CMRR_RL,CMRR_RR,MRR
 SG_ BCM1_St_DriverDoor : 29|1@0+ (1,0) [0|1] "" IDC,Delete_FDCA,Delete_APA,Delete_CMRR_FL,Delete_CMRR_FR,CMRR_RL,CMRR_RR,MRR
 SG_ BCM1_St_PassengerDoor : 28|1@0+ (1,0) [0|1] "" IDC,Delete_FDCA,Delete_APA,Delete_CMRR_FL,Delete_CMRR_FR,CMRR_RL,CMRR_RR,MRR
 SG_ BCM1_St_LRDoor : 27|1@0+ (1,0) [0|1] "" IDC,Delete_FDCA,Delete_APA,Delete_CMRR_FL,Delete_CMRR_FR,CMRR_RL,CMRR_RR,MRR
 SG_ BCM1_St_RRDoor : 26|1@0+ (1,0) [0|1] "" IDC,Delete_FDCA,Delete_APA,Delete_CMRR_FL,Delete_CMRR_FR,CMRR_RL,CMRR_RR,MRR
 SG_ BCM1_St_TrunkDoor : 25|1@0+ (1,0) [0|1] "" IDC,Delete_FDCA,Delete_APA,Delete_CMRR_FL,Delete_CMRR_FR,CMRR_RL,CMRR_RR,MRR
 SG_ BCM1_St_Hood : 24|1@0+ (1,0) [0|1] "" IDC,Delete_FDCA,Delete_APA,Delete_CMRR_FL,Delete_CMRR_FR,CMRR_RL,CMRR_RR,MRR
 SG_ BCM1_Sw_Brake : 35|1@0+ (1,0) [0|1] "" IDC,Delete_APA
 SG_ BCM1_Sw_ReverseGear : 34|1@0+ (1,0) [0|1] "" IDC,Delete_APA
 SG_ BCM1_St_LowBeam : 46|1@0+ (1,0) [0|1] "" IDC,Delete_FDCA,Delete_APA
 SG_ BCM1_Cmd_BrakeLamp : 43|1@0+ (1,0) [0|1] "" IDC,Delete_APA
 SG_ BCM1_Cmd_HazardInd : 42|1@0+ (1,0) [0|1] "" IDC,Delete_FDCA,Delete_APA
 SG_ BCM1_Cmd_HighBeam : 41|1@0+ (1,0) [0|1] "" IDC,Delete_FDCA,Delete_APA
 SG_ BCM1_Cmd_LowBeam : 40|1@0+ (1,0) [0|1] "" IDC,Delete_FDCA,Delete_APA
 SG_ BCM1_St_BrakeFluidLowWarning : 52|1@0+ (1,0) [0|1] "" IDC,Delete_APA
 SG_ BCM1_St_DRL : 51|2@0+ (1,0) [0|3] "" IDC,Delete_APA
 SG_ BCM1_Cmd_FrontFoglamp : 63|1@0+ (1,0) [0|1] "" IDC,Delete_FDCA,Delete_APA
 SG_ BCM1_St_FrontFoglamp : 62|1@0+ (1,0) [0|1] "" IDC,Delete_FDCA,Delete_APA
 SG_ BCM1_Cmd_RearFoglamp : 61|1@0+ (1,0) [0|1] "" IDC,Delete_FDCA,Delete_APA
 SG_ BCM1_St_RearFoglamp : 60|1@0+ (1,0) [0|1] "" IDC,Delete_FDCA,Delete_APA

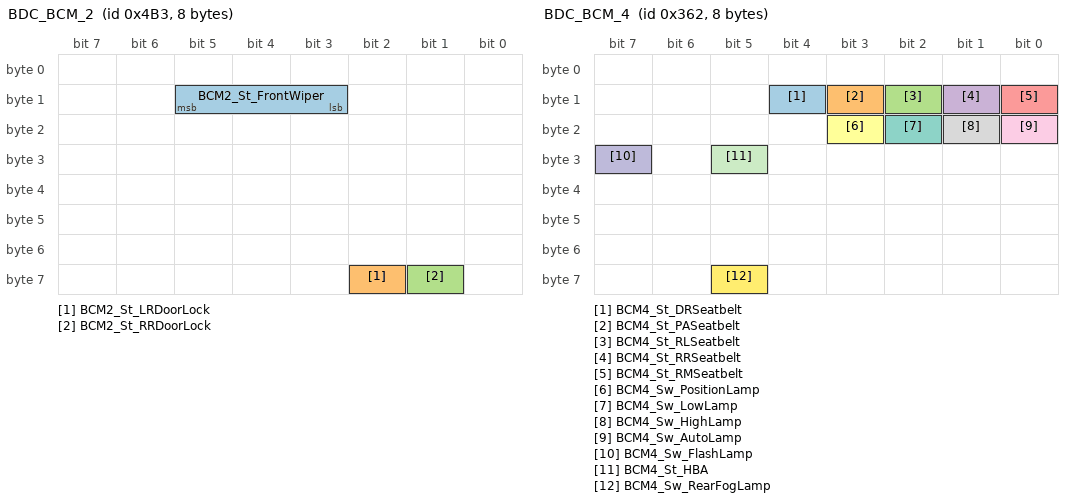
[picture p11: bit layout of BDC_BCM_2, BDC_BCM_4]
BO_ 1203 BDC_BCM_2: 8 CGW
 SG_ BCM2_St_FrontWiper : 13|3@0+ (1,0) [0|7] "" IDC,Delete_FDCA
 SG_ BCM2_St_LRDoorLock : 58|1@0+ (1,0) [0|1] "" IDC,Delete_APA,Delete_CMRR_FL,Delete_CMRR_FR,CMRR_RL,CMRR_RR,MRR
 SG_ BCM2_St_RRDoorLock : 57|1@0+ (1,0) [0|1] "" IDC,Delete_APA,Delete_CMRR_FL,Delete_CMRR_FR,CMRR_RL,CMRR_RR,MRR

BO_ 866 BDC_BCM_4: 8 CGW
 SG_ BCM4_St_DRSeatbelt : 12|1@0+ (1,0) [0|1] "" IDC,Delete_FDCA,Delete_APA
 SG_ BCM4_St_PASeatbelt : 11|1@0+ (1,0) [0|1] "" IDC,Delete_APA
 SG_ BCM4_St_RLSeatbelt : 10|1@0+ (1,0) [0|1] "" IDC,Delete_APA
 SG_ BCM4_St_RRSeatbelt : 9|1@0+ (1,0) [0|1] "" IDC,Delete_APA
 SG_ BCM4_St_RMSeatbelt : 8|1@0+ (1,0) [0|1] "" IDC,Delete_APA
 SG_ BCM4_Sw_PositionLamp : 19|1@0+ (1,0) [0|1] "" IDC,Delete_FDCA
 SG_ BCM4_Sw_LowLamp : 18|1@0+ (1,0) [0|1] "" IDC,Delete_FDCA
 SG_ BCM4_Sw_HighLamp : 17|1@0+ (1,0) [0|1] "" IDC,Delete_FDCA
 SG_ BCM4_Sw_AutoLamp : 16|1@0+ (1,0) [0|1] "" IDC,Delete_FDCA
 SG_ BCM4_Sw_FlashLamp : 31|1@0+ (1,0) [0|1] "" IDC,Delete_FDCA
 SG_ BCM4_St_HBA : 29|1@0+ (1,0) [0|1] "" IDC,Delete_FDCA
 SG_ BCM4_Sw_RearFogLamp : 61|1@0+ (1,0) [0|1] "" IDC,Delete_FDCA

BO_ 1383 BDC_BCM_9: 8 CGW
 SG_ BCM9_St_LightSoundInhibition : 43|2@0+ (1,0) [0|3] "" IDC,Delete_APA,Delete_CMRR_FL,Delete_CMRR_FR,CMRR_RL,CMRR_RR,MRR

BO_ 1380 DCU_LF_1: 8 CGW
 SG_ DLF1_St_LmirrorFold : 25|2@0+ (1,0) [0|3] "" IDC,Delete_APA

BO_ 1382 DCU_RF_1: 8 CGW
 SG_ DRF1_St_RmirrorFold : 13|2@0+ (1,0) [0|3] "" IDC,Delete_APA

BO_ 1328 AC_1: 8 CGW
 SG_ AC1_F_OutsideTemp : 1|2@0+ (1,0) [0|3] "" IDC,Delete_FDCA,Delete_APA
 SG_ AC1_N_OutsideTemp : 23|8@0+ (1,-40) [-40|100] "deg. C" IDC,Delete_FDCA,Delete_APA

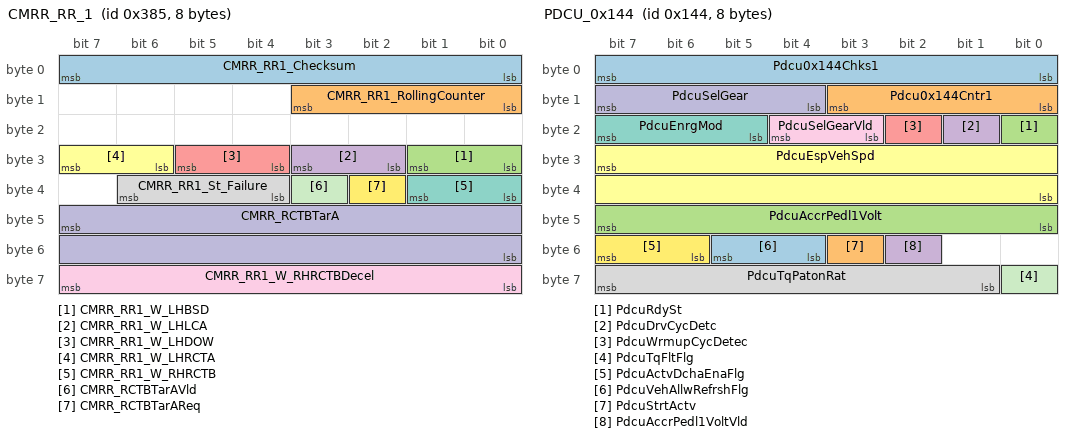
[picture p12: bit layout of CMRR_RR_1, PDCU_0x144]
BO_ 901 CMRR_RR_1: 8 IDC
 SG_ CMRR_RR1_Checksum : 7|8@0+ (1,0) [0|255] "" CGW
 SG_ CMRR_RR1_RollingCounter : 11|4@0+ (1,0) [0|15] "" CGW
 SG_ CMRR_RR1_W_LHBSD : 25|2@0+ (1,0) [0|3] "" Delete_FDCA,CGW
 SG_ CMRR_RR1_W_LHLCA : 27|2@0+ (1,0) [0|3] "" Delete_FDCA,CGW
 SG_ CMRR_RR1_W_LHDOW : 29|2@0+ (1,0) [0|3] "" CGW
 SG_ CMRR_RR1_W_LHRCTA : 31|2@0+ (1,0) [0|3] "" CGW
 SG_ CMRR_RR1_W_RHRCTB : 33|2@0+ (1,0) [0|3] "" CGW
 SG_ CMRR_RR1_St_Failure : 38|3@0+ (1,0) [0|7] "" Delete_FDCA,CGW
 SG_ CMRR_RR1_W_RHRCTBDecel : 63|8@0+ (0.05,-10) [-10|2.75] "" CGW
 SG_ CMRR_RCTBTarA : 47|16@0+ (0.0004882,-16) [-16|15.994187] "m/s2" CGW
 SG_ CMRR_RCTBTarAVld : 35|1@0+ (1,0) [0|1] "" CGW
 SG_ CMRR_RCTBTarAReq : 34|1@0+ (1,0) [0|1] "" CGW

BO_ 902 CMRR_RR_2: 8 IDC
 SG_ CMRR_RR2_Checksum : 7|8@0+ (1,0) [0|255] "" CGW
 SG_ CMRR_RR2_RollingCounter : 11|4@0+ (1,0) [0|15] "" CGW
 SG_ CMRR_RR2_St_RCTA : 14|3@0+ (1,0) [0|7] "" CGW
 SG_ CMRR_RR2_St_RCTB : 18|3@0+ (1,0) [0|7] "" CGW
 SG_ CMRR_RR2_St_RCW : 22|3@0+ (1,0) [0|7] "" CGW
 SG_ CMRR_RR2_SwFb_RCW : 23|1@0+ (1,0) [0|1] "" CGW
 SG_ CMRR_RR2_W_RHBSD : 25|2@0+ (1,0) [0|3] "" Delete_FDCA,CGW
 SG_ CMRR_RR2_W_RHLCA : 27|2@0+ (1,0) [0|3] "" Delete_FDCA,CGW
 SG_ CMRR_RR2_W_RHDOW : 29|2@0+ (1,0) [0|3] "" CGW
 SG_ CMRR_RR2_W_RHRCTA : 31|2@0+ (1,0) [0|3] "" CGW
 SG_ CMRR_RR2_W_RCW : 35|2@0+ (1,0) [0|3] "" CGW
 SG_ CMRR_RR2_St_DOW : 42|3@0+ (1,0) [0|7] "" CGW
 SG_ CMRR_RR2_St_BSD_LCA : 50|3@0+ (1,0) [0|7] "" Delete_FDCA,CGW
 SG_ CMRR_RR2_St_Blindness : 52|2@0+ (1,0) [0|3] "" Delete_FDCA,CGW
 SG_ CMRR_RR2_St_Calibration : 55|3@0+ (1,0) [0|7] "" Delete_FDCA,CGW
 SG_ CMRR_RR2_SwFb_RCTA : 57|2@0+ (1,0) [0|3] "" CGW
 SG_ CMRR_RR2_SwFb_RCTB : 59|2@0+ (1,0) [0|1] "" CGW
 SG_ CMRR_RR2_SwFb_BSD_LCA : 61|2@0+ (1,0) [0|1] "" CGW
 SG_ CMRR_RR2_SwFb_DOW : 63|2@0+ (1,0) [0|1] "" CGW

BO_ 324 PDCU_0x144: 8 CGW
 SG_ Pdcu0x144Chks1 : 7|8@0+ (1,0) [0|255] "" IDC,Delete_FDCA
 SG_ Pdcu0x144Cntr1 : 11|4@0+ (1,0) [0|14] "" IDC,Delete_FDCA
 SG_ PdcuRdySt : 16|1@0+ (1,0) [0|1] "" IDC,Delete_FDCA,Delete_APA,Delete_CMRR_FL,Delete_CMRR_FR,CMRR_RL,CMRR_RR,MRR,Vector__XXX
 SG_ PdcuDrvCycDetc : 17|1@0+ (1,0) [0|1] "" IDC,Delete_FDCA
 SG_ PdcuWrmupCycDetec : 18|1@0+ (1,0) [0|1] "" IDC,Delete_FDCA
 SG_ PdcuEspVehSpd : 31|16@0+ (0.1,0) [0|300] "km/h" IDC,Delete_FDCA
 SG_ PdcuEnrgMod : 23|3@0+ (1,0) [0|7] "" IDC,Delete_FDCA
 SG_ PdcuTqPatonRat : 63|7@0+ (1,0) [0|100] "" IDC,Delete_FDCA
 SG_ PdcuSelGearVld : 20|2@0+ (1,0) [0|3] "" IDC,Delete_FDCA,Delete_APA,Delete_CMRR_FL,Delete_CMRR_FR,CMRR_RL,CMRR_RR,MRR
 SG_ PdcuSelGear : 15|4@0+ (1,0) [0|15] "" IDC,Delete_FDCA,Delete_APA,Delete_CMRR_FL,Delete_CMRR_FR,CMRR_RL,CMRR_RR,MRR
 SG_ PdcuTqFltFlg : 56|1@0+ (1,0) [0|1] "" IDC,Delete_FDCA
 SG_ PdcuActvDchaEnaFlg : 55|2@0+ (1,0) [0|3] "" IDC,Delete_FDCA
 SG_ PdcuVehAllwRefrshFlg : 53|2@0+ (1,0) [0|3] "" IDC,Delete_FDCA
 SG_ PdcuStrtActv : 51|1@0+ (1,0) [0|1] "" IDC,Delete_FDCA,Delete_APA,Delete_CMRR_FL,Delete_CMRR_FR,CMRR_RL,CMRR_RR,MRR,Vector__XXX
 SG_ PdcuAccrPedl1Volt : 47|8@0+ (19.6078,0) [0|5000] "mV" IDC,Delete_FDCA
 SG_ PdcuAccrPedl1VoltVld : 50|1@0+ (1,0) [0|1] "" IDC,Delete_FDCA

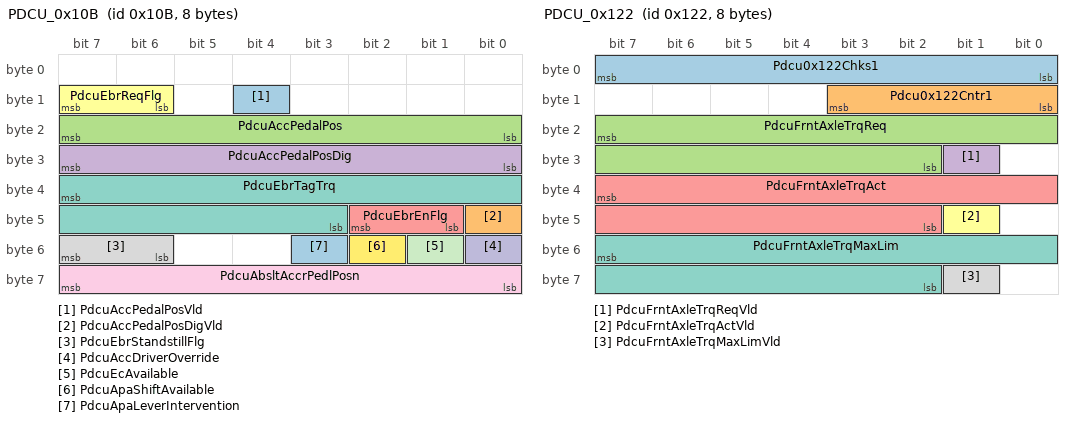
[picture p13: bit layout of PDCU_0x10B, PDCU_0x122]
BO_ 267 PDCU_0x10B: 8 CGW
 SG_ PdcuAccPedalPosVld : 12|1@0+ (1,0) [0|1] "" IDC,Delete_FDCA,Delete_APA,Delete_CMRR_FL,Delete_CMRR_FR,CMRR_RL,CMRR_RR,MRR
 SG_ PdcuAccPedalPosDigVld : 40|1@0+ (1,0) [0|1] "" IDC,Delete_FDCA,Delete_APA,Delete_CMRR_FL,Delete_CMRR_FR,CMRR_RL,CMRR_RR,MRR
 SG_ PdcuAccPedalPos : 23|8@0+ (0.3937,0) [0|100.395] "%" IDC,Delete_FDCA,Delete_APA,Delete_CMRR_FL,Delete_CMRR_FR,CMRR_RL,CMRR_RR,MRR
 SG_ PdcuAccPedalPosDig : 31|8@0+ (0.3937,0) [0|100.395] "%" IDC,Delete_FDCA,Delete_APA,Delete_CMRR_FL,Delete_CMRR_FR,CMRR_RL,CMRR_RR,MRR
 SG_ PdcuEbrEnFlg : 42|2@0+ (1,0) [0|2] "" IDC,Delete_FDCA
 SG_ PdcuEbrReqFlg : 15|2@0+ (1,0) [0|2] "" IDC,Delete_FDCA
 SG_ PdcuEbrTagTrq : 39|13@0+ (1,0) [0|6000] "Nm" IDC,Delete_FDCA
 SG_ PdcuEbrStandstillFlg : 55|2@0+ (1,0) [0|2] "" IDC,Delete_FDCA
 SG_ PdcuAbsltAccrPedlPosn : 63|8@0+ (0.39215686,0) [0|99.9999993] "%" IDC,Delete_FDCA
 SG_ PdcuAccDriverOverride : 48|1@0+ (1,0) [0|1] "" IDC,Delete_FDCA
 SG_ PdcuEcAvailable : 49|1@0+ (1,0) [0|1] "" IDC,Delete_FDCA
 SG_ PdcuApaShiftAvailable : 50|1@0+ (1,0) [0|1] "" IDC,Delete_FDCA
 SG_ PdcuApaLeverIntervention : 51|1@0+ (1,0) [0|1] "" IDC,Delete_FDCA

BO_ 290 PDCU_0x122: 8 CGW
 SG_ Pdcu0x122Chks1 : 7|8@0+ (1,0) [0|255] "" IDC,Delete_FDCA
 SG_ Pdcu0x122Cntr1 : 11|4@0+ (1,0) [0|14] "" IDC,Delete_FDCA
 SG_ PdcuFrntAxleTrqReq : 23|14@0+ (1,-6000) [-6000|10000] "Nm" IDC,Delete_FDCA
 SG_ PdcuFrntAxleTrqReqVld : 25|1@0+ (1,0) [0|1] "" IDC,Delete_FDCA
 SG_ PdcuFrntAxleTrqAct : 39|14@0+ (1,-6000) [-6000|10000] "Nm" IDC,Delete_FDCA
 SG_ PdcuFrntAxleTrqActVld : 41|1@0+ (1,0) [0|1] "" IDC,Delete_FDCA
 SG_ PdcuFrntAxleTrqMaxLim : 55|14@0+ (1,-6000) [-6000|10000] "Nm" IDC,Delete_FDCA
 SG_ PdcuFrntAxleTrqMaxLimVld : 57|1@0+ (1,0) [0|1] "" IDC,Delete_FDCA

BO_TX_BU_ 582 : IDC,Delete_FDCA;

BO_TX_BU_ 838 : IDC,Delete_FDCA;

BO_TX_BU_ 656 : IDC,Delete_APA;

BO_TX_BU_ 657 : IDC,Delete_APA;

BO_TX_BU_ 1427 : IDC,Delete_APA;

BO_TX_BU_ 917 : IDC,Delete_APA;

CM_ "Version:V1.0,Date:2026.6.22,Author:王让,Review:,Approval:,Description:(IDC)在BJEV_B60VS_ACANFD_Matrix_CANFD_V2.5_20240202的基础上，建立B81VS项目ADASBUS的初版通信协议;
Version:V1.0,Date:2026.6.30,Author:王让,Review:,Approval:,Description:(IDC)*IDC增加接收新方向盘开关SWS的报文0x288，不再接收旧的方向盘开关SWFB报文0x578（idc）;
Version:V1.1,Date:2026.7.13,Author:王让,Review:,Approval:,Description:(IDC)根据张洁浩工的输入，针对B81VS的J6B功能：
*IDC新增发送报文0x135，0x136，0x39B，0x39C（idc，eps，pbm，bdcu，pdcu）；
*IDC增加接收PDCU的报文0x137（idc，pdcu）；
*0x311:IDC增加接收WCBS_ESP5_St_APACDDActive（idc）；
*IDC增加接收EPS的报文0x180（eps，idc）
*IDC增加接收PBM的报文0x132（pbm，idc）
根据王昕充工20260707的OA输入，针对B81VS的J6B功能：
*0x393: IDC增加发送信号ADC_ADASYSSTS（idc，icc）,更新ADAS2_ICATJATakeoverReq的信号值描述（idc，icc）；
*BDCU增加接收IDC的0x39C报文（idc，bdcu）
*IDC增加接收EPS的0x142，0x143报文（idc）
*IDC增加接收信号IPC8_F_VehicleSpeedIndi,不再接收报文0x220:CDC_IPC_6（idc）
*0x132：更新WCBS_ADLCFailureSts的信号值描述（pbm，idc）
*0x341：IDC增加接收WCBS_N_EBRTrqACT，网关需要增加路由（idc，cgw）
*0x243：IDC增加接收WCBS_ESP10_St_HBA, WCBS_ESP10_St_HHC（idc）
*IDC增加接收0x218，0x62F报文（idc）
*0x310：IDC增加接收EPB1_St_DynamicApply（idc）
*原本CMRR_RR的报文0x385,0x386转而由IDC发出（cmrr，idc）
*0x385：IDC增加发送CMRR_RCTBTarAVld，CMRR_RCTBTarA，CMRR_RCTBTarAReq（idc，pbm）
*0x136：IDC增加发送ADS_DrvTarTq_J6（idc，pdcu）
*0x133：PBM增加发送IBS_DrvrTqDes_J6(pbm,idc)
*0x39E: PBM增加发送PBM_FltIndcn_EPB,网关需要增加路由(pbm,idc,cgw)
*EPS新增发送报文0x13B,网关需要增加路由(eps,pdcu,idc,cgw)；
*0x1BB：ICC增加发送ICC_ApaExamStatus，ICC_AdasExamStatus（icc，idc）;
Version:V1.2,Date:2026.8.7,Author:,Review:,Approval:,Description:(IDC)根据蔡鑫雨工20260730的OA输入，针对B81VS的J6B功能：
*0x1BC：ICC增加发送ICC_AvapViewSource，ICC_AvapSysSts，ICCAvmCalibrationParameter，ICCApaCalibrationReq（icc，idc）
*0x38C：IDC增加发送报文0x38C，网关需要增加路由（idc，icc，cgw）
*0x137：修改PDCU_AVAPFltFb的信号值描述（pdcu，idc）
*0x135: EPS增加接收APA_SysFailSts（eps），同时更新APA_SysFailSts的信号值描述（idc，eps，pbm）
*0x135: 更新APA_StrWhlAgReq的初始值（idc，eps）
*0x132：PBM增加发送WCBS_OMPavailable（pbm，idc）
根据王昕充工20260805的OA输入，针对B81VS的J6B功能：
*IDC增加接收报文YRS_0x19A,网关需要增加路由（idc，cgw）
*0x136: IDC增加发送ADS_SteerAgCtrlEnaReq_J6（idc，eps）
*0x13B: EPS增加发送EPS_SteerDrvrOvrd_J6 (eps，idc)
*0x1BC：ICC增加发送ICCAdasApaSocOffSwt（icc，idc）
*0x393: IDC增加发送MPC_SOCOffSwtFb（idc，icc）
*0x39E: PBM不再发送信号PBM_FltIndcn_EPB，删除(pbm,idc);
Version:V1.3,Date:2026.8.22,Author:,Review:,Approval:,Description:(IDC)根据杨茜工20260818的OA输入,针对整车隐私协议功能
*0x620:ICC增加发送ICC_PrivacyAgreementSwt（icc，idc，tbox）
*0x5E4:IDC增加发送ADC_PrivacyAgreementSts (idc,icc)
*0x529:TBOX增加发送TBOX_PrivacyAgreementSts (tbox,icc);
Version:V1.4,Date:2026.9.13,Author:,Review:,Approval:,Description:(IDC)根据丁万兴工20260902的OA输入，针对B81VS项目6座车增加了三排座椅，以及BDCU集成了TIM：
*0x362：优化BCM4_St_RLSeatbelt，BCM4_St_RRSeatbelt，BCM4_St_RMSeatbelt的中文信号描述，在后缀增加（二排）字样（bdcu，sdm，icc，idc，tbox）
*0x339：BDCU增加发送信号ThirdDrvSeatWarnLamp，ThirdPassSeatWarnLamp（bdcu，icc，sdm）
*0x211：针对B81VS项目，BDCU增加发送信号TIM1_St_SoftSwMemoryNew，信号长度为2bit（bdcu，icc，idc, cmrr_rl, cmrr_rr, mrr）；为了信号平台化管理，信号长度1bit的TIM1_St_SoftSwMemory暂时保留；
*0x6E6: 针对B81VS项目, EHC11_St_TrailerFcnActive采用新的信号值描述，见后面括号内的内容；为了信号平台化管理，旧的信号值描述暂时保留，见括号外前面的内容（icc，bdcu，idc,cmrr_rl, cmrr_rr, mrr）。;
Version:V1.4,Date:2026.9.15,Author:,Review:,Approval:,Description:(IDC)根据蔡鑫雨工20260914的OA输入，
*0x38C：修改信号名称ApaCalibrationSts（泊车标定结果反馈）为ApaFactoryCalibrationSts（工厂泊车标定结果反馈）（idc，icc）
*0x38C：修改信号名称ApaCalibrationFailureReasons（泊车标定失败原因反馈）为ApaFactoryCalibFailureRsn（工厂泊车标定失败原因反馈）,并更新信号长度及coding值（idc，icc）
*0x38C：增加信号ApaAfterSalesCalibrationSts（IDC发，ICC收）
*0x38C：增加信号ApaAfterSalesCalibStsProgress（IDC发，ICC收）
*0x38C：增加信号ApaAfterSalesCalibFailureRsn（IDC发，ICC收）
*WCBS_0x132：修改WCBS_APLCFailureSts的信号值描述由0x6~0x7: Reserved，改为0x6：Message Error,0x7: Reserved（pbm，idc）;
 ";

CM_ BO_ 640 "转到ICAN是50ms
转到BCAN是50ms
转到TCAN是100ms";
CM_ BO_ 792 "转到BCAN是50ms
转到TCAN是100ms";
CM_ BO_ 1600 "转到BCAN是100ms
转到TCAN是100ms";
CM_ BO_ 1616 "转到BCAN100ms
转到TCAN是100ms";
CM_ BO_ 785 "转到TCAN是100ms";
CM_ BO_ 579 "转到TCAN是100ms";
CM_ BO_ 784 "转到BCAN是100ms
转到TCAN是100ms";
CM_ BO_ 1297 "转到BCAN是100ms";
CM_ BO_ 384 "转到BCAN是100ms
转到TCAN是100ms";
CM_ BO_ 838 "转到TCAN是100ms";
CM_ BO_ 1314 "连发三帧，间隔20ms";
CM_ BO_ 1766 "转到PCAN是100ms";
CM_ BO_ 656 "维持与B60V不变，转到TCANFD是1000ms";
CM_ BO_ 657 "暂时不删除，与B60V汽油兼容，
转到BCAN是100ms";
CM_ BO_ 917 "转到PCAN是100ms，微调";
CM_ SG_ 582 FDCA4_N_ComAccUpperValue "ComforAccUpperValue保证舒适性的加速度上限";
CM_ SG_ 582 FDCA4_Cmd_BrakePreferred "BrakePreferred制动优先";
CM_ SG_ 582 FDCA4_N_ComAccLowerValue "ComforAccLowerValue保证舒适性的加速度下限";
CM_ SG_ 582 FDCA4_St_ReqDriveroff "Driveroff起步请求";
CM_ SG_ 582 FDCA4_N_LimitAccUpperValue "LimitAccUpperValue目标加速度变化率上限";
CM_ SG_ 582 FDCA4_N_LimitAccLowerValue "LimitAccLowerValue目标加速度变化率下限";
CM_ SG_ 582 FDCA4_St_ReqHBA "HBARequestHBA请求";
CM_ SG_ 582 FDCA4_St_ReqPrefill "PrefillRequest预先填充请求";
CM_ SG_ 582 FDCA4_Cmd_DecToStop "DecToStop制动到停止";
CM_ SG_ 582 FDCA4_N_HBALevel "HBALevelHBA等级（41为IBA等级）";
CM_ SG_ 582 FDCA4_ShutdownMod "The shutdown mode request to the ESP_VLC.具体退出逻辑以功能规范为准";
CM_ SG_ 582 ADAS_FDCA4_St_AEBMode "AEB Mode";
CM_ SG_ 582 FDCA4_St_ACCMode "ACCMode_ESP ACC状态（供ESP使用）";
CM_ SG_ 582 FDCA4_RollingCounter "Message counter for each message transmittedThe transmitter shall update the value of the Message Counter signal every time a frame is transmitted (even if no other data in theframe has changed value). The counter value shall be updated in the sequence 0, 1, 2, 3......15, 0, 1, 2, 3......15, etc. Upon startup,theinitial value of the Message Counter signal shall be 0.";
CM_ SG_ 582 FDCA4_CheckSum "Checksum = (byte0+byte1+…+byte 6）and 0xFF";
CM_ SG_ 838 FDCA3_N_AEBTardec "AEBTardecAEB目标减速度";
CM_ SG_ 838 FDCA3_St_ACCMinimumBraking "ACCMinimumBraking车辆以最小制动减速到设定车速";
CM_ SG_ 838 FDCA3_St_AWBLevel "AWBLevelAWB等级";
CM_ SG_ 838 FDCA3_St_ReqAWB "AWBRquestAWB请求";
CM_ SG_ 838 FDCA3_St_ReqAEBDecCtrl "AEBDecCtrlRequestAEB激活";
CM_ SG_ 838 FDCA3_N_ACCTarAcc "ACCTarAccACC目标加速度";
CM_ SG_ 838 FDCA3_St_ACCMode "ACCMode_ESPACC状态（供ESP使用）";
CM_ SG_ 838 FDCA3_F_TorqueReq "ADAS Torque Req Status对于EPS的补偿扭矩请求状态";
CM_ SG_ 838 FDCA3_N_TorqueReq "ADAS Torque Req对于EPS的补偿扭矩请求";
CM_ SG_ 838 FDCA3_RollingCounter "Message counter for each message transmittedThe transmitter shall update the value of the Message Counter signal every time a frame is transmitted (even if no other data in theframe has changed value). The counter value shall be updated in the sequence 0, 1, 2, 3......15, 0, 1, 2, 3......15, etc. Upon startup,theinitial value of the Message Counter signal shall be 0.";
CM_ SG_ 838 FDCA3_Checksum "Checksum = (byte0+byte1+…+byte 6）and 0xFF";
CM_ SG_ 656 APA1_N_TargetSteeringAng "Target  value of steering wheel angle for automatic parking";
CM_ SG_ 656 APA1_F_TargetSteeringAng "Target steering wheel angle is valid or not";
CM_ SG_ 656 APA1_St_ControlRequest "request for controlling EPS";
CM_ SG_ 656 APA1_St_TarGearReq "Target gear position";
CM_ SG_ 656 APA1_St_BrakeMode "APA activation brake mode status";
CM_ SG_ 656 APA1_St_BrakeFunctionMode "APA indicate which function mode the ESC enters inform ESC the velocity maximum";
CM_ SG_ 656 APA1_N_ESCStopDi "inform the ESC of  the parking target distance ESC_Stop_Distance";
CM_ SG_ 656 APA1_N_ESCSpeedLi "inform ESC the velocity maximum ESC_Speed_Limitation";
CM_ SG_ 656 APA1_St_FBrakeMode "Brake mode when APA failure";
CM_ SG_ 656 APA1_RollingCounter "Message counter for the message transmitted.The transmitter shall update the value of signal RollingCounter each time the message is transmitted, even if no data updated in the message.The value of the rolling counter increases according to the sequence such as '0,1,2...15,0,1,2...15', and the initial value will be set to zero once transmission is started.";
CM_ SG_ 656 APA1_Checksum "Checksum = (byte0+byte1+…+byte 6）and 0xFF";
CM_ SG_ 657 APA2_St_AutoParkingIn "自动泊入按钮状态Auto_Parking_In_Status";
CM_ SG_ 657 APA2_St_AutoParkingOut "自动泊出按钮状态Auto_Parking_Out_Status";
CM_ SG_ 657 APA2_St_UserSlot "自选车位按钮状态User_Slot_Status";
CM_ SG_ 657 APA2_St_Set "设置按钮状态Set_Status";
CM_ SG_ 657 APA2_St_ParkOutDirSet "APA确认用户选择车位已被选中";
CM_ SG_ 657 APA2_RPA_RpaSts "RPA状态";
CM_ SG_ 657 APA2_St_Preference "车位偏好Preference";
CM_ SG_ 657 APA2_St_ParkingInMode "泊入方式Parking in Mode";
CM_ SG_ 657 APA2_St_ParkingInPreCon "泊入前置条件Parking_In_PreCondition";
CM_ SG_ 657 APA2_St_APAStatus "APA status 自动泊车状态";
CM_ SG_ 657 APA2_St_ParkingOutDirection "泊出方向Parking_Out_Direction";
CM_ SG_ 657 APA2_St_SelectedParkOutDire "选择的泊出方向Selected_Parking_Out_Direction";
CM_ SG_ 657 APA2_St_DirHalfLeAvl "向左车头泊出";
CM_ SG_ 657 APA2_St_DirHalfRiAvl "向右车头泊出";
CM_ SG_ 657 APA2_St_DirHozlFwAvl "向前直行";
CM_ SG_ 657 APA2_St_DirHozlBwAvl "向后直行";
CM_ SG_ 657 APA2_St_DirVertHdLeAvl "泊出至车位左前方";
CM_ SG_ 657 APA2_St_DirVertHdRiAvl "泊出至车位右前方";
CM_ SG_ 657 APA2_St_DirVertTrLeAvl "泊出至车位左后方";
CM_ SG_ 657 APA2_St_DirVertTrRiAvl "泊出至车位右后方";
CM_ SG_ 657 APA2_St_Request "APA控制请求APA2_St_Request";
CM_ SG_ 657 APA2_RollingCounter "Message counter for the message transmitted.The transmitter shall update the value of signal RollingCounter each time the message is transmitted, even if no data updated in the message.The value of the rolling counter increases according to the sequence such as '0,1,2...15,0,1,2...15', and the initial value will be set to zero once transmission is started.";
CM_ SG_ 657 APA2_Checksum "Checksum = (byte0+byte1+…+byte 6）and 0xFF";
CM_ SG_ 1427 APA3_St_Update "升级状态Update_Status";
CM_ SG_ 1427 APA3_St_UpdateType "升级类型Update_Type";
CM_ SG_ 1427 APA3_N_SoftVersion "当前软件总版本号（最大版本表示V3.99.99）bit14~bit15（2 bit）：0~3bit7~bit13（7 bit）：0~99bit0~bit6（7 bit）：0~99";
CM_ SG_ 1427 APA3_N_PacketSoftVersion "升级包软件总版本号（最大版本表示V3.99.99）bit14~bit15（2 bit）：0~3bit7~bit13（7 bit）：0~99bit0~bit6（7 bit）：0~99";
CM_ SG_ 917 AVM2_St_WormModeView "蠕行模式界面Worm_Mode_View_State";
CM_ SG_ 917 AVM2_St_RockModeView "岩石模式界面Rock_Mode_View_State";
CM_ SG_ 917 AVM2_St_CurrViewType "当前AVM界面类型Curr_View_Type";
CM_ SG_ 917 AVM2_St_Mode " UI button: AVM is 2D mode or 3D mode currently3D AVM_Mode_State";
CM_ SG_ 917 AVM2_St_PerspectiveChassis " UI button: Perspective Chassis is on or not currently透明底盘Perspective_Chassis";
CM_ SG_ 917 AVM2_St_QuitAvmEnable "是否可退出全景Quit_Avm_Enable";
CM_ SG_ 917 AVM2_St_ModeSwitchEnable "是否可切换2D/3DMode_Switch_Enable";
CM_ SG_ 917 AVM2_St_PerspectiveEnable "是否可开关透明底盘Perspective_Chassis_Switch_Enable";
CM_ SG_ 917 AVM2_St_MoreViewEnable "是否可切换更多视图More_View_Enable";
CM_ SG_ 917 AVM2_St_SettingEnable "是否可进入设置Setting_Enable";
CM_ SG_ 917 AVM2_St_WormEnable "是否可切换蠕行模式Worm_Mode_Switch_Enable";
CM_ SG_ 917 AVM2_St_RockEnable "是否可切换岩石模式Rock_Mode_Switch_Enable";
CM_ SG_ 917 AVM2_St_Reseved "Reserved";
CM_ SG_ 917 AVM2_Set_TireTrajectory "轮胎轨迹线Tire_Trajectory";
CM_ SG_ 917 AVM2_Set_CarTrajectory "车身轮廓线Car_Trajectory";
CM_ SG_ 917 AVM2_Set_2DRadar "2D雷达2D_Radar";
CM_ SG_ 917 AVM2_Set_3DRadar "3D雷达3D_Radar";
CM_ SG_ 917 AVM2_Set_TurnTriggerView "转向触发视角切换Turn_Switch_State";
CM_ SG_ 917 AVM2_Set_RadarTriggerView "雷达触发视角切换Radar_Switch_State";
CM_ SG_ 917 AVM2_Error_Controller "AVM or APA控制器故障APA_Controller";
CM_ SG_ 917 AVM2_Error_ViewOutput "AVM or APA视频输出故障APA_View_Output";
CM_ SG_ 917 AvmVehLctSts "车身透明设置Lucent反馈";
CM_ SG_ 917 AVM2_Set_CarColor "车身颜色Car_Color";
CM_ SG_ 917 AVM2_St_MoreViews " UI button: more views更多视图按钮的当前按钮更多视图More_View_State";
CM_ SG_ 917 AVM2_St_CSSLight "CSS的指示灯信号";
CM_ SG_ 917 AVM2_St_RestoreSetting "恢复出厂设置的feedback（触发后在下一帧发送0x1，连发三次0x1，时间间隔为本报文的周期50ms，之后置0x0；）";
CM_ SG_ 917 AVM2_St_PromptMessage "弹窗提示建议预留9个bit,收到此信息，车机进行弹窗提示，以ID形式体现，APA与车机约定每个ID的弹窗信息及弹窗时长固定时长弹窗信息Static_Prompt_Message";
CM_ SG_ 917 AVM2_St_PromptTimeOut "弹窗超时Prompt_time_out";
CM_ SG_ 917 FrntcamFaild "Indicate failed of front camera.";
CM_ SG_ 917 RecamFaild "Indicate failed of rear camera.";
CM_ SG_ 917 LecamFaild "Indicate failed of left camera.";
CM_ SG_ 917 RicamFaild "Indicate failed of right camera.";
CM_ SG_ 917 AvmCtrlrFaild "Indicate failed of controller operating.控制器内部故障可扩展";
CM_ SG_ 917 AvmSts "Indicate the current work status of AVM.";
CM_ SG_ 901 CMRR_RR1_Checksum "Checksum = (byte1+byte2+…+byte 7）and 0xFF";
CM_ SG_ 901 CMRR_RR1_RollingCounter "Message counter for each message transmittedThe transmitter shall update the value of the Message Counter signal every time a frame is transmitted (even if no other data in the frame has changed value). The counter value shall be updated in the sequence 0, 1, 2, 3......15, 0, 1, 2, 3......15, etc. Upon startup,the initial value of the Message Counter signal shall be 0.";
CM_ SG_ 901 CMRR_RR1_W_LHBSD "左后雷达BSD报警";
CM_ SG_ 901 CMRR_RR1_W_LHLCA "左后雷达LCA报警";
CM_ SG_ 901 CMRR_RR1_W_LHDOW "左后雷达DOW报警";
CM_ SG_ 901 CMRR_RR1_W_LHRCTA "左后雷达RCTA报警";
CM_ SG_ 901 CMRR_RR1_W_RHRCTB "右雷达RCTB制动";
CM_ SG_ 901 CMRR_RR1_St_Failure "后角雷达系统故障状态";
CM_ SG_ 901 CMRR_RR1_W_RHRCTBDecel "右后雷达RCTB制动减速度";
CM_ SG_ 901 CMRR_RCTBTarA "RCTB减速度";
CM_ SG_ 901 CMRR_RCTBTarAVld "RCTB减速度有效位";
CM_ SG_ 901 CMRR_RCTBTarAReq "RCTB减速度请求";
CM_ SG_ 902 CMRR_RR2_Checksum "Checksum = (byte1+byte2+…+byte 7）and 0xFF";
CM_ SG_ 902 CMRR_RR2_RollingCounter "Message counter for each message transmittedThe transmitter shall update the value of the Message Counter signal every time a frame is transmitted (even if no other data in the frame has changed value). The counter value shall be updated in the sequence 0, 1, 2, 3......15, 0, 1, 2, 3......15, etc. Upon startup,the initial value of the Message Counter signal shall be 0.";
CM_ SG_ 902 CMRR_RR2_St_RCTA "RCTA倒车预警 后方交通穿行提示 rear cross traffic alert";
CM_ SG_ 902 CMRR_RR2_St_RCTB "RCTB后方交通横穿制动rear cross traffic brake";
CM_ SG_ 902 CMRR_RR2_St_RCW "RCW后向碰撞预警 rear collision warning";
CM_ SG_ 902 CMRR_RR2_SwFb_RCW "RCW开关状态反馈信号";
CM_ SG_ 902 CMRR_RR2_W_RHBSD "右后雷达BSD报警";
CM_ SG_ 902 CMRR_RR2_W_RHLCA "右后雷达LCA报警";
CM_ SG_ 902 CMRR_RR2_W_RHDOW "右后雷达DOW报警";
CM_ SG_ 902 CMRR_RR2_W_RHRCTA "右后雷达RCTA报警";
CM_ SG_ 902 CMRR_RR2_W_RCW "后雷达RCW报警";
CM_ SG_ 902 CMRR_RR2_St_DOW "DOW开门预警 车门开启预警door open warning";
CM_ SG_ 902 CMRR_RR2_St_BSD_LCA "BSD_LCA盲区监测 blind spot detection；BSD";
CM_ SG_ 902 CMRR_RR2_St_Blindness "后角雷达系统遮挡状态";
CM_ SG_ 902 CMRR_RR2_St_Calibration "雷达标定状态";
CM_ SG_ 902 CMRR_RR2_SwFb_RCTA "RCTA开关状态反馈信号";
CM_ SG_ 902 CMRR_RR2_SwFb_RCTB "RCTB开关状态反馈信号";
CM_ SG_ 902 CMRR_RR2_SwFb_BSD_LCA "BSD_LCA开关状态反馈信号";
CM_ SG_ 902 CMRR_RR2_SwFb_DOW "DOW开关状态反馈信号";
CM_ SG_ 640 EMS5_RollingCounter "Message counter for each message transmittedThe transmitter shall update the value of the Message Counter signal every time a frame is transmitted (even if no other data in theframe has changed value). The counter value shall be updated in the sequence 0, 1, 2, 3......15, 0, 1, 2, 3......15, etc. Upon startup,theinitial value of the Message Counter signal shall be 0.N=E";
CM_ SG_ 640 EMS5_F_BrakePedal "The valid indication of EMS5_St_BrakePedalThis signal is a quality signal connected to EMS5_St_BrakePedal";
CM_ SG_ 640 EMS5_St_BrakePedal "indicates that Brake Pedal is pressed";
CM_ SG_ 640 EMS5_St_LimpHome "Engine Management in limp home, if any parts is in limphome";
CM_ SG_ 640 EMS5_Checksum "Checksum = (byte0+byte1+…+byte 6）and 0xFF";
CM_ SG_ 792 WCBS_ESP1_St_AutoHoldAvailable "Auto hold功能可用状态.关车门可用，该信号置1；不关车门置0";
CM_ SG_ 792 WCBS_ESP1_St_AutoHold "Auto hold功能激活状态. (For EPB）";
CM_ SG_ 792 WCBS_ESP1_St_AutoHoldTelltale "Auto hold功能标志位. (For EPB)";
CM_ SG_ 792 WCBS_ESP1_Cmd_EPBPark "请求EPB驻车命令. (For EPB)";
CM_ SG_ 792 WCBS_ESP1_St_TCSActive "TCS controlling status.For WCBS:TCSActive";
CM_ SG_ 792 WCBS_ESP1_St_BrakeLightControl "Indicate the request to light up brake light during HDC/CDP/ACC/AEB function active.WCBS_Brake_Lights_Request";
CM_ SG_ 792 WCBS_ESP1_St_ABSActive "ABS controlling status.For WCBS:ABSActive";
CM_ SG_ 792 WCBS_ESP1_St_EBDActive "EBD controlling status.";
CM_ SG_ 792 WCBS_ESP1_St_ESPFailureTelltale "Signal indicates failure monitoring of ESP functionFor WCBS:TCS失效and ESC失效是指TCS和VDC任一个失效";
CM_ SG_ 792 WCBS_ESP1_St_ESPTCSOffTelltale "Signal indicates to light up 'TCS/ESP off' lamp.-manual switch off of ESP function (on/off switch).For WCBS:ESC_ESCOffSwitch ";
CM_ SG_ 792 WCBS_ESP1_St_DecelerationActive "Indicate whether or not deceleration function requested by EPB is active.";
CM_ SG_ 792 WCBS_ESP1_St_ABSTelltale "Signal indicates to light up ABS lampFor WCBS:ABS失效";
CM_ SG_ 792 WCBS_ESP1_St_EBDTelltale "Signal indicates to light up EBD lampFor WCBS:EBD失效";
CM_ SG_ 792 WCBS_ESP1_St_ESPActive "ESP controlling status.For WCBS:VDCActive";
CM_ SG_ 792 WCBS_ESP1_St_ESPTCSActiveTelltale "Signal indicates to light up 'TCS/ESP active' lamp. Is used to indicate to the driver that the system is currently active.";
CM_ SG_ 792 WCBS_ESP1_St_HDCTelltale "Signal indicates to light up HDC lamp";
CM_ SG_ 792 WCBS_ESP1_N_OdometerRoll "Odometer rolling count 1 pulse/bit. The value shall be set to zero at every ignition off and if the counter reach max value it starts from zero again.（ E=N）";
CM_ SG_ 792 WCBS_ESP1_St_WCBSFault "Indicate that WCBS Fault status";
CM_ SG_ 792 WCBS_ESP1_St_BrakeFluidW "Brake Fluid Warning";
CM_ SG_ 792 WCBS_ESP1_RollingCounter "Message counter for the message transmitted.The transmitter shall update the value of signal RollingCounter each time the message is transmitted, even if no data updated in the message.The value of the rolling counter increases according to the sequence such as '0,1,2...15,0,1,2...15', and the initial value will be set to zero once transmission is started.";
CM_ SG_ 792 WCBS_ESP1_Checksum "Checksum = (byte0+byte1+…+byte 6）and 0xFF";
CM_ SG_ 288 WCBS_ESP2_RollingCounter "Message counter for the message transmitted.The transmitter shall update the value of signal RollingCounter each time the message is transmitted, even if no data updated in the message.The value of the rolling counter increases according to the sequence such as '0,1,2...15,0,1,2...15', and the initial value will be set to zero once transmission is started.";
CM_ SG_ 288 WCBS_ESP2_St_EngineIntervention "Engine torque reduction flag";
CM_ SG_ 288 WCBS_ESP2_St_BrakeIntervention "VDC BrakeIntervention function /TCS BrakeIntervention function active or not active";
CM_ SG_ 288 WCBS_ESP2_St_EngineDragTor "Engine drag torque control flag";
CM_ SG_ 288 WCBS_ESP2_Checksum "Checksum = (byte0+byte1+…+byte 6）and 0xFF";
CM_ SG_ 1600 WCBS_ESP3_F_FLWheelSpeed " This signal indicates the valid value of ESP3_N_FLWheelSpeed";
CM_ SG_ 1600 WCBS_ESP3_N_FLWheelSpeed "Front Left Wheel Speed (E=N*0.0625)";
CM_ SG_ 1600 WCBS_ESP3_F_FRWheelSpeed " This signal indicates the valid value of ESP3_N_FRWheelSpeed";
CM_ SG_ 1600 WCBS_ESP3_N_FRWheelSpeed "Front Right Wheel Speed(E=N*0.0625)";
CM_ SG_ 1600 WCBS_ESP3_RollingCounter "(E=N)";
CM_ SG_ 1600 WCBS_ESP3_Checksum "CRC8，算法另附文件";
CM_ SG_ 1616 WCBS_ESP4_N_BrakePedalStroke "制动踏板行程信号";
CM_ SG_ 1616 WCBS_ESP4_F_BrakePedalStroke "制动踏板行程信号标志位";
CM_ SG_ 1616 WCBS_ESP4_Checksum "CRC8，算法另附文件";
CM_ SG_ 1616 WCBS_ESP4_RollingCounter "(E=N)";
CM_ SG_ 1616 WCBS_ESP4_F_RLWheelSpeed "This signal indicates the valid value of ESP4_N_RLWheelSpeed";
CM_ SG_ 1616 WCBS_ESP4_N_RLWheelSpeed "Rear Left Wheel Speed(E=N*0.0625)";
CM_ SG_ 1616 WCBS_ESP4_F_RRWheelSpeed "This signal indicates the valid value of ESP4_N_RRWheelSpeed";
CM_ SG_ 1616 WCBS_ESP4_N_RRWheelSpeed "Rear Right Wheel Speed(E=N*0.0625)";
CM_ SG_ 785 WCBS_ESP5_St_VehicleStandstill "indicating whether the vehicle is standstill or not;must not be set until standstill is surely reached.";
CM_ SG_ 785 WCBS_ESP5_St_APAVLC "VLC Status. This signal is a must for TCU to enter or hold ‘Driving Assistant System’ state machine. The signal is sent from WCBS to TCM. TCM should map this signal into its own logic as APS_SystemMode:0x0: off0x1: standby0x2: active";
CM_ SG_ 785 WCBS_ESP5_St_APACDDActive "CDD function active or not. This signal is a must condition for a position change request.The signal is sent from WCBS to TCM. TCM should map this signal into  its own logic as APS_BrakingStatus.";
CM_ SG_ 785 WCBS_ESP5_St_GearInhit "default value is always set o";
CM_ SG_ 785 WCBS_ESP5_RollingCounter "Message counter for each message transmittedThe transmitter shall update the value of the Message Counter signal every time a frame is transmitted (even if no other data in theframe has changed value). The counter value shall be updated in the sequence 0, 1, 2, 3......15, 0, 1, 2, 3......15, etc. Upon startup,theinitial value of the Message Counter signal shall be 0.";
CM_ SG_ 785 WCBS_ESP5_F_VehicleSpeed "to indicate whether VehicleSpeed signal is invalid.";
CM_ SG_ 785 WCBS_ESP5_St_APACDDAv "APA CDD Available";
CM_ SG_ 785 WCBS_ESP5_St_NoBrakeForce "no brake pressure applied; generally it regards wheel cylinder pressure.";
CM_ SG_ 785 WCBS_ESP5_St_ACCCDDActive "indicating ACC CDD is working or not.";
CM_ SG_ 785 WCBS_ESP5_St_ACCCDDAv "indicating ACC CDD is available or not.";
CM_ SG_ 785 WCBS_ESP5_St_ABAactive "ABA is active";
CM_ SG_ 785 WCBS_ESP5_St_ABAavailable "the ABA function is available";
CM_ SG_ 785 WCBS_ESP5_St_PrefillActive "Prefill (ABP) is active";
CM_ SG_ 785 WCBS_ESP5_St_PrefillAvailable "Prefill (ABP) is available";
CM_ SG_ 785 WCBS_ESP5_St_AEBdecActive "ESP is excuting AEB  braking function.";
CM_ SG_ 785 WCBS_ESP5_St_AEBdecAv "AEB is available.";
CM_ SG_ 785 WCBS_ESP5_St_DecSupportAc "ESP is excuting EBA braking request.DecelerationSupportActive";
CM_ SG_ 785 WCBS_ESP5_St_DecSupportAv "EBA is available.DecelerationSupportAvailable";
CM_ SG_ 785 WCBS_ESP5_AWBactive "AWB is active";
CM_ SG_ 785 WCBS_ESP5_AWBavailable "AWB is available";
CM_ SG_ 785 WCBS_ESP5_QDCFail "MRR error detected by ESP, like timeout or alivecounter error.";
CM_ SG_ 785 WCBS_ESP5_BrakeOverheat "indicating brake temperature too high or not.";
CM_ SG_ 785 WCBS_ESP5_N_VehicleSpeed "Vehicle Speed from WCBS";
CM_ SG_ 785 WCBS_ESP5_St_APALCFailure "Indicate the failure of the APA longitudinal controller";
CM_ SG_ 785 WCBS_ESP5_St_APAVLCAv "APA VLC Available";
CM_ SG_ 785 WCBS_ESP5_St_TCSOffTelltale "Signal indicates to light up 'TCS Off' lamp.";
CM_ SG_ 785 WCBS_ESP5_Checksum "Checksum = (byte0+byte1+…+byte 6）and 0xFF";
CM_ SG_ 1008 WCBS_ESP6_F_LongitudeAcc "纵向加速度有效位";
CM_ SG_ 1008 WCBS_ESP6_F_LateralAcc "横向加速度有效位";
CM_ SG_ 1008 WCBS_ESP6_F_YawVelocity "横摆角速度有效位";
CM_ SG_ 1008 WCBS_ESP6_F_BrakePressure "The signal is the valid of  WCBS_ESP6_N_BrakePressure.include When  physical value of CAN  signal 'Brake Pressure'  exceeds 255 bar, this signal is “0x1”";
CM_ SG_ 1008 WCBS_ESP6_RollingCounter "Message counter for the message transmitted.The transmitter shall update the value of signal RollingCounter each time the message is transmitted, even if no data updated in the message.The value of the rolling counter increases according to the sequence such as '0,1,2...15,0,1,2...15', and the initial value will be set to zero once transmission is started.";
CM_ SG_ 1008 WCBS_ESP6_N_LongitudeAcc "纵向加速度(E=N*0.02-25)";
CM_ SG_ 1008 WCBS_ESP6_FCTB_avaliable "FCTB is avaliable";
CM_ SG_ 1008 WCBS_ESP6_RCTB_avaliable "RCTB is avaliable";
CM_ SG_ 1008 WCBS_ESP6_N_LateralAcc "横向加速度(E=N*0.2-25)";
CM_ SG_ 1008 WCBS_ESP6_N_YawVelocity "横摆角速度(E=N*0.001-2.5)";
CM_ SG_ 1008 WCBS_ESP6_Checksum "Checksum = (byte0+byte1+…+byte 5+byte 7）and 0xFF";
CM_ SG_ 1008 WCBS_ESP6_N_BrakePressure "When CAN value of signal 'BRAKE PRESSURE'  is 'oxFF', then physical value  of this signal will reach 255 bar. When physical value of this signal exceeds 255 bar, ESP will also transmit this signal with the CAN value 'oxFF'.(E=N*1)";
CM_ SG_ 579 WCBS_ESP10_N_FRPulse "Sum of edge of Front Right Wheel speed sensor ";
CM_ SG_ 579 WCBS_ESP10_N_FLPulse "Sum of edge of Front Left Wheel speed sensor ";
CM_ SG_ 579 WCBS_ESP10_N_RRPulse "Sum of edge of Rear Right Wheel speed sensor ";
CM_ SG_ 579 WCBS_ESP10_N_RLPulse "Sum of edge of Rear Left Wheel speed sensor ";
CM_ SG_ 579 WCBS_ESP10_F_FRPulse "To indicate whether Front Right Wheel speed sensor signal is valid";
CM_ SG_ 579 WCBS_ESP10_F_FLPulse "To indicate whether Front Left Wheel speed sensor signal is valid";
CM_ SG_ 579 WCBS_ESP10_F_RRPulse "To indicate whether Rear Right Wheel speed sensor signal is valid";
CM_ SG_ 579 WCBS_ESP10_F_RLPulse "To indicate whether Rear Left Wheel speed sensor signal is valid";
CM_ SG_ 579 WCBS_ESP10_St_HBA "Hydraulic Braking Assist，液压制动辅助状态";
CM_ SG_ 579 WCBS_ESP10_St_HHC "(For EPB)HHC上坡辅助";
CM_ SG_ 579 WCBS_ESP10_RollingCounter "Message counter for the message transmitted.The transmitter shall update the value of signal RollingCounter each time the message is transmitted, even if no data updated in the message.The value of the rolling counter increases according to the sequence such as '0,1,2...15,0,1,2...15', and the initial value will be set to zero once transmission is started.";
CM_ SG_ 579 WCBS_ESP10_Checksum "Checksum = (byte0+byte1+…+byte 6）and 0xFF";
CM_ SG_ 578 WCBS_ESP13_St_VDCFail "VDCFailStsVDC故障状态";
CM_ SG_ 578 WCBS_ESP13_St_BrakePedal "制动踏板状态信号";
CM_ SG_ 578 WCBS_ESP13_St_TCSFail "TCSFailStsTCS故障，只指TCS失效";
CM_ SG_ 578 WCBS_ESP13_St_ACCVLCActive "VLC_ActiveACC VLC激活";
CM_ SG_ 578 WCBS_ESP13_St_VLCAvailable "VLC_AvailableACC VLC可用";
CM_ SG_ 578 WCBS_ESP13_St_VLCFail "VLCFailACC VLC故障";
CM_ SG_ 578 WCBS_ESP13_N_VLCITA "VLC_InternalTargetAccelerationVLC内部目标加速度";
CM_ SG_ 578 WCBS_ESP13_St_LHFWDD "LHFWheelDriverDirection左前轮速方向";
CM_ SG_ 578 WCBS_ESP13_St_RHFWDD "RHFWheelDriveDirection右前轮速方向";
CM_ SG_ 578 WCBS_ESP13_St_DCFail "DCFail不能执行ACC的减速功能时通知摄像头";
CM_ SG_ 578 WCBS_ESP13_St_LHRWDD "LHRWheelDriverDirection左后轮速方向";
CM_ SG_ 578 WCBS_ESP13_St_RHRWDD "RHRWheelDriveDirection右后轮速方向";
CM_ SG_ 578 WCBS_ESP13_St_CCOActive "低速蠕行功能开启提示";
CM_ SG_ 578 WCBS_ESP13_RollingCounter "Message counter for each message transmittedThe transmitter shall update the value of the Message Counter signal every time a frame is transmitted (even if no other data in theframe has changed value). The counter value shall be updated in the sequence 0, 1, 2, 3......15, 0, 1, 2, 3......15, etc. Upon startup,theinitial value of the Message Counter signal shall be 0.";
CM_ SG_ 578 WCBS_ESP13_CheckSum "Checksum = (byte0+byte1+…+byte 6）and 0xFF";
CM_ SG_ 784 EPB1_RollingCounter "Message counter for the message transmitted.The transmitter shall update the value of signal RollingCounter each time the message is transmitted, even if no data updated in the message.The value of the rolling counter increases according to the sequence such as '0,1,2...15,0,1,2...15', and the initial value will be set to zero once transmission is started.";
CM_ SG_ 784 EPB1_St_WarningLamp "The status of EPB warning lamp status.";
CM_ SG_ 784 EPB1_St_ActuatorStL "The status of left Moc. 1.EPB状态值为5时，为执行机构故障，EPB1_St_EARFail为0x1:error in EPB (no external apply allowed)；2.当EPB1_St_DynamicApply：为0x1: ECD request active时，该信号发0x2为0x2 RWUactive,该信号发0x7Adjust为0x3 Degrade Apply，该信号发0x6Hold";
CM_ SG_ 784 EPB1_St_ActuatorStR "The status of right Moc. 1.EPB状态值为5时，为执行机构故障，EPB1_St_EARFail为0x1；2.当EPB1_St_DynamicApply：为0x1: ECD request active时，该信号发0x2为0x2 RWUactive,该信号发0x7Adjust为0x3 Degrade Apply，该信号发0x6Hold";
CM_ SG_ 784 EPB1_St_EPBSwitch "The status of EPB switch.";
CM_ SG_ 784 EPB1_Cmd_CruiseControlCancel "The command to cancel cruise control.";
CM_ SG_ 784 EPB1_St_DynamicApply "The status of dynamic apply.1.EPB执行动态制动的工作模式，可用于TMM  Open Request，CC Cancel  Request的请求冗余判断；2.0代表动态制动没有被激活；1代表动态制动联动；2代表后轮防抱死制动；3代表降级制动； ECD即动态制动联动，ESP执行的四轮动态制动；而RWU为EPB执行的后轮防抱死动态制动；无四驱控制模块";
CM_ SG_ 784 EPB1_St_EARFail "Actuator error Status，when EPB1_St_ActuatorSt_L或EPB1_St_ActuatorSt_R is 0x5，该信号会置0x1";
CM_ SG_ 784 EPB1_St_ParkBrake "Park Brake Status1.EPB1_St_ParkBrake =0x0: both brakes released 对应EPB1_St_ActuatorSt_L&   EPB1_St_ActuatorSt_R = 0x2: Brake Off  ；  2.EPB1_St_ParkBrake =0x1: both brakes applied对应EPB1_St_ActuatorSt_L&   EPB1_St_ActuatorSt_R = 0x1: Brake On；3.EPB1_St_ParkBrake =0x3: unknown对应EPB1_St_ActuatorSt_L或   EPB1_St_ActuatorSt_R =Broken(0x5)4. EPB1_St_ParkBrake =0x2: both brakes in operation (applying/releasing) ,对应EPB1_St_ActuatorSt_L&   EPB1_St_ActuatorSt_R状态为除以上情况外，均为此状态";
CM_ SG_ 784 EPB1_checksum "Checksum = (byte0 + byte 1 + …+ byte 6) XOR (0xFF)";
CM_ SG_ 1297 ATS1_RollingCounter "Message counter for the message transmitted.The transmitter shall update the value of signal RollingCounter each time the message is transmitted, even if no data updated in the message.The value of the rolling counter increases according to the sequence such as '0,1,2...15,0,1,2...15', and the initial value will be set to zero once transmission is started.";
CM_ SG_ 1297 ATS_Cmd_RqPerChassis "切换到岩石模式3s, 通知avm拉起透明底盘（Perspective_Chassis）画面";
CM_ SG_ 1297 PdcuDrvModCfmd "PdcuDriveModeConfirmed驾驶模式确认";
CM_ SG_ 1297 ATS1_Checksum "Checksum = (byte0+byte1+…+byte 6）and 0xFF";
CM_ SG_ 384 EPS_SAS_Checksum "Checksum of frame valuestemp_result = Byte1 XOR Byte2 XOR Byte3 XOR Byte4EPS_SAS_Checksum = higher nibble(temp_result) XORlower nibble(temp_result) XOR EPS_SAS_RollingCounter";
CM_ SG_ 384 EPS_SAS_RollingCounter "Information for the ECU to know if messages are lost between the reception of two messages.(E=N)";
CM_ SG_ 384 EPS_SAS_St_Calibrated "The SAS has been Calibrated or not";
CM_ SG_ 384 EPS_SAS_St_SensorInfo "SAS Sensor information is valid or not";
CM_ SG_ 384 EPS_SAS_N_RotationSpeed "The value of rotationspeed";
CM_ SG_ 384 EPS_SAS_N_SteeringAngle "The value of steeringangle";
CM_ SG_ 384 EPS_St_DrvStrInterDeteToADAS "反馈ADAS驾驶员方向盘干预检测状态";
CM_ SG_ 384 EPS_F_DrvStrInterDeteToADAS "反馈ADAS驾驶员方向盘干预检测状态有效性";
CM_ SG_ 384 EPS_SysAvlSts_APA "EPS 系统可用 状 态";
CM_ SG_ 384 EPS_APA_FuncMode "EPS实际执行的APA功能模式";
CM_ SG_ 384 EPS_AbortFb "EPS 控制中断原因";
CM_ SG_ 384 EPS_EPSAvl "EPS  ADAS功能可不可用";
CM_ SG_ 384 EPS_OverrangeFeedback "EPS检测ADAS请求超限状态";
CM_ SG_ 384 EPS_SteerWorkStatus "EPS工作状态";
CM_ SG_ 848 SDM1_St_AirbagDeployed "Airbag Deployment Status安全气囊碰撞状态";
CM_ SG_ 848 SDM1_RollingCounter "Message counter for each message transmittedThe transmitter shall update the value of the Message Counter signal every time a frame is transmitted (even if no other data in theframe has changed value). The counter value shall be updated in the sequence 0, 1, 2, 3......15, 0, 1, 2, 3......15, etc. Upon startup,theinitial value of the Message Counter signal shall be 0.";
CM_ SG_ 848 SDM1_Checksum "Checksum = (byte0+byte1+…+byte 6）and 0xFF";
CM_ SG_ 323 EPS1_St_FailSts "The status of the EPS （EPS的故障状态）";
CM_ SG_ 323 EPS1_St_SteerMod "EPS steering mode ";
CM_ SG_ 323 EPS1_St_TrqSnsrSts "EPS torque sensor status驾驶员手力矩的标志位, 表征当前TAS传感器的状态是否正常0x0: Normal（为正确值）0x1: Abnormal（为错误值，当EPS无法准确检测驾驶员手力矩时发送此值）";
CM_ SG_ 323 EPS1_St_DrvStrInterDete "驾驶员方向盘干预检测状态";
CM_ SG_ 323 EPS1_N_SteeringTorque "Value of driver input torque(Clockwise rotation is '-' and anti-Clockwise rotation is '+')";
CM_ SG_ 323 EPS1_F_DrvStrInterDete "驾驶员方向盘干预检测状态有效性";
CM_ SG_ 323 EPS1_St_Requestfeedback "state of Handshake between EPS and APA";
CM_ SG_ 323 EPS1_St_EPSControl "EPS Control StatusEPS握手信号（与L2.5交互）";
CM_ SG_ 323 EPS1_N_ReqTorqueFeedack "（预留）Request Torque Feedack and TorqueDirEPS执行的ADAS系统请求扭矩及扭矩方向";
CM_ SG_ 323 EPS1_F_ReqTorqueFeedack "（预留）RequestTorqueFeedackValidEPS执行的ADAS系统请求扭矩有效性";
CM_ SG_ 323 EPS1_St_DSTEPSControl "EPS Control StatusEPS与DST握手信号(Reserved)dynamic steering torque system control 动态扭矩转向控制,也叫动态方向稳定辅助";
CM_ SG_ 323 EPS1_F_DSTReqTorFeedackValid "DSTRequestTorqueFeedackValidEPS执行的DST系统请求扭矩有效性(Reserved)";
CM_ SG_ 323 EPS1_N_DSTReqTorFeedack "Request Torque Feedack and TorqueDirEPS执行的DST系统请求扭矩及扭矩方向(Reserved)";
CM_ SG_ 323 EPS1_RollingCounter "Message counter for the message transmitted.The transmitter shall update the value of signal RollingCounter each time the message is transmitted, even if no data updated in the message.The value of the rolling counter increases according to the sequence such as '0,1,2...15,0,1,2...15', and the initial value will be set to zero once transmission is started.";
CM_ SG_ 323 EPS1_Checksum "Checksum = (byte0+byte1+…+byte 6）and 0xFF";
CM_ SG_ 323 EPS1_DrvInpTrqVld "EPS feedback the Value of driver input torque valid or not, 表征当前驾驶员手力信号的有效性";
CM_ SG_ 816 CSS1_F_AVMSw "The Valid of AVM Switch";
CM_ SG_ 816 CSS1_Sw_AVM "The switch of AVM";
CM_ SG_ 1314 EHC1_Set_FPAS "to set Front PAS  open or close";
CM_ SG_ 1314 EHC1_Set_LanguageSetting "to  set  Language";
CM_ SG_ 1314 EHC1_Set_ThemeMode "Theme Mode set  inform IPC and APA to set skin";
CM_ SG_ 1315 EHC3_Set_FCWOption "FCW Option Sts前碰撞预警距离灵敏度设定";
CM_ SG_ 1315 EHC3_Set_LKASen "LKA Sensitivity车道保持辅助灵敏度";
CM_ SG_ 1315 EHC3_Set_AEB "自动紧急制动状态机";
CM_ SG_ 1315 EHC3_Set_TSR "TSR交通标志牌识别状态";
CM_ SG_ 1315 EHC3_Set_TJA_ICA_ACC "TJA ICA、ACC巡航状态";
CM_ SG_ 1315 EHC3_Set_LDWSen "LDW Sensitivity车道偏离灵敏度";
CM_ SG_ 1319 EHC6_N_Year "year";
CM_ SG_ 1319 EHC6_N_Month "Month";
CM_ SG_ 1319 EHC6_N_Day "Day";
CM_ SG_ 1319 EHC6_N_Hour "Hour";
CM_ SG_ 1319 EHC6_N_Minute "Minute";
CM_ SG_ 1319 EHC6_N_Second "Second";
CM_ SG_ 1319 EHC6_St_Navigation "Navigation status";
CM_ SG_ 1319 EHC6_Set_LanguageSetting "to  set  Language";
CM_ SG_ 1319 EHC6_TiMod "Time mode";
CM_ SG_ 1319 EHC6_DateWeek "Week of date";
CM_ SG_ 1766 EHC11_St_TrailerFcnActive "拖车功能激活由用户在主机大屏上自主开启";
CM_ SG_ 1766 IccSentiModReq "ICC请求APA和DVR进入/退出哨兵激活状态";
CM_ SG_ 1766 CDC_Cmd_CampGuardee "露营卫士请求信号";
CM_ SG_ 1766 IccSentiModSts "哨兵模式状态Sentinel mode status";
CM_ SG_ 1568 IPC1_F_OdometerParameter "The valid indication of odo meter，odo meter reset and odo meter offset in EEROM";
CM_ SG_ 1568 IPC1_St_QDashACCFail "Error in the ACC message detected by the HMI, like timeout or alivecounter error.The error should distinguish reversible and irreversible errors.";
CM_ SG_ 1568 IPC1_St_DISFail "Error in the display or display control unit.";
CM_ SG_ 1568 IPC1_N_OdoMeter "The value of odo meter";
CM_ SG_ 1568 ICC_PrivacyAgreementSwt "设置整车隐私协议开关";
CM_ SG_ 1392 CAPE1_F_PowerMode "Vehicle power mode validityThis signal indicates if power mode signal is valid or not";
CM_ SG_ 1392 CAPE1_St_PowerMode "Vehicle power modeThis signal indicates the inner power mode of PDM";
CM_ SG_ 1392 CAPE1_St_PepsRemPwrMod "PEPS remote power mode statusinclude remote control，remote start，Bluetooth control， bluetooth start，RPA control";
CM_ SG_ 1392 CAPE1_RollingCounter "The counter value shall be updated in the sequence 0, 1, 2, 3......255, 0, 1, 2, 3......255, etc. Upon startup,theinitial value of the Message Counter signal shall be 0.（E=N）";
CM_ SG_ 1392 CAPE1_CheckSum "Checksum = (byte0+byte1+…+byte 6）and 0xFF";
CM_ SG_ 1184 BCM1_Cmd_PositionLamp "The Command of Position Lamp,BCM  judge all stations that need light the positon lamp on and send this command in CAN bus. Light the position lamp on in the IPC";
CM_ SG_ 1184 BCM1_Sw_TurnLeftLamp "左转向灯开关状态";
CM_ SG_ 1184 BCM1_Sw_TurnRightLamp "右转向灯开关状态";
CM_ SG_ 1184 BCM1_St_HazzardFlash "危险警报闪烁使能状态";
CM_ SG_ 1184 BCM1_St_HighBeam "The status of high lamp,reform the IPC there is fault or not about all high lampReserved";
CM_ SG_ 1184 BCM1_Cmd_LeftTurnLamp "The Command of Left turn Lamp,BCM  judge when the Lamp is fault that need light the lamp on as the correct HZ and send this command in CAN bus. Light the lamp on in the IPC";
CM_ SG_ 1184 BCM1_St_LeftTurnLamp "The status of left turn lamp,reform the IPC there is fault or not about the lamp";
CM_ SG_ 1184 BCM1_Cmd_RightTurnLamp "The Command of Right turn Lamp,BCM  judge when the Lamp is fault that need light the lamp on as the correct HZ and send this command in CAN bus. Light the lamp on in the IPC";
CM_ SG_ 1184 BCM1_St_RightTurnLamp "The status of right turn lamp,reform the IPC there is fault or not about the lamp";
CM_ SG_ 1184 BCM1_St_PositionLamp "The status of position lamp,reform the IPC there is fault or not about all position lamp";
CM_ SG_ 1184 BCM1_St_AntiThelfIndication "Anti-thief indication status设防状态信号";
CM_ SG_ 1184 BCM1_St_LFDoorLock "The status of the driver door lock switch";
CM_ SG_ 1184 BCM1_St_PasDoorLock "The status of the Passenge door lock switch";
CM_ SG_ 1184 BCM1_St_DriverDoor "The status of Driver door switch  ";
CM_ SG_ 1184 BCM1_St_PassengerDoor "The status of Passenger door switch";
CM_ SG_ 1184 BCM1_St_LRDoor "The status of the rear left door switch";
CM_ SG_ 1184 BCM1_St_RRDoor "The status of the rear right door switch";
CM_ SG_ 1184 BCM1_St_TrunkDoor "The status of trunk Door switch";
CM_ SG_ 1184 BCM1_St_Hood "The status of hood";
CM_ SG_ 1184 BCM1_Sw_Brake "The status of Brake switch";
CM_ SG_ 1184 BCM1_Sw_ReverseGear "The status of reverse gear switch";
CM_ SG_ 1184 BCM1_St_LowBeam "The status of low beam,reform the IPC there is fault or not about all low beam";
CM_ SG_ 1184 BCM1_Cmd_BrakeLamp "制动灯输出状态";
CM_ SG_ 1184 BCM1_Cmd_HazardInd "The status of hazard indicator";
CM_ SG_ 1184 BCM1_Cmd_HighBeam "The Command of High Lamp,BCM  judge all stations that need light the high lamp on and send this command in CAN bus. Light the High lamp on in the IPC";
CM_ SG_ 1184 BCM1_Cmd_LowBeam "The Command of Low beam,BCM  judge all stations that need light the low beam on and send this command in CAN bus. Light the low beam on in the IPC";
CM_ SG_ 1184 BCM1_St_BrakeFluidLowWarning "The warning status of brake fluid low (Reserved)";
CM_ SG_ 1184 BCM1_St_DRL "The status of daytime running lamp";
CM_ SG_ 1184 BCM1_Cmd_FrontFoglamp "The Command of FrontFoglamp,BCM  judge all stations that need light the FrontFoglamp on and send this command in CAN bus. Light the FrontFoglamp on in the IPC";
CM_ SG_ 1184 BCM1_St_FrontFoglamp "The status of FrontFoglamp,reform the IPC there is fault or not about all FrontFoglamp";
CM_ SG_ 1184 BCM1_Cmd_RearFoglamp "The Command of RearFoglamp,BCM  judge all stations that need light the RearFoglamp on and send this command in CAN bus. Light the RearFoglamp on in the IPC";
CM_ SG_ 1184 BCM1_St_RearFoglamp "The status of RearFoglamp,reform the IPC there is fault or not about all RearFoglamp";
CM_ SG_ 1203 BCM2_St_FrontWiper "The status of front wiper";
CM_ SG_ 1203 BCM2_St_LRDoorLock "左后锁状态";
CM_ SG_ 1203 BCM2_St_RRDoorLock "右后锁状态";
CM_ SG_ 866 BCM4_St_DRSeatbelt "Driver Seatbelt Buckle Switch Status";
CM_ SG_ 866 BCM4_St_PASeatbelt "副驾安全带报警信号";
CM_ SG_ 866 BCM4_St_RLSeatbelt "左后安全带报警信号（二排）";
CM_ SG_ 866 BCM4_St_RRSeatbelt "右后安全带报警信号（二排）";
CM_ SG_ 866 BCM4_St_RMSeatbelt "后排中央安全带报警信号（二排）";
CM_ SG_ 866 BCM4_Sw_PositionLamp "The state of positionLamp SW";
CM_ SG_ 866 BCM4_Sw_LowLamp "The state of lowLamp SW";
CM_ SG_ 866 BCM4_Sw_HighLamp "The state of highLamp SW";
CM_ SG_ 866 BCM4_Sw_AutoLamp "The state of autoLamp SW";
CM_ SG_ 866 BCM4_Sw_FlashLamp "The state of flashLamp SW,超车灯开关";
CM_ SG_ 866 BCM4_St_HBA "The state of HBA SW";
CM_ SG_ 866 BCM4_Sw_RearFogLamp "RearFogLamp switch";
CM_ SG_ 1383 BCM9_St_LightSoundInhibition "Light Sound inhibit and restrain during OTAOTA升级抑制屏幕、背光、声音等刷写模式抑制功能启动指令fromBDC。(OTA升级抑制屏幕、背光、声音、动作等，避免用户可感知的异常显示或声音，同时降低能耗。本项目使用0和1两个值使用)注：B60V的coding值与B60VS，B41不同";
CM_ SG_ 1380 DLF1_St_LmirrorFold "Left rear view mirror  fold status";
CM_ SG_ 1382 DRF1_St_RmirrorFold "Right rear view mirror  flod status";
CM_ SG_ 1328 AC1_F_OutsideTemp "Outside Environment temperature Valid signal ";
CM_ SG_ 1328 AC1_N_OutsideTemp "Environment temperature";
CM_ SG_ 324 Pdcu0x144Chks1 "CRC checksum. DataID and the following 7 bytes are included in CRC checksum calculation. Refer to E2E Spec.（Profile：1A，DataID=0x0001）";
CM_ SG_ 324 Pdcu0x144Cntr1 "Rolling counter. Refer to E2E Spec.";
CM_ SG_ 324 PdcuRdySt "车辆Ready状态";
CM_ SG_ 324 PdcuDrvCycDetc "Vehicle Driving Cycle Detection";
CM_ SG_ 324 PdcuWrmupCycDetec "Vehicle Warm-up Cycle Detection";
CM_ SG_ 324 PdcuEspVehSpd "车速";
CM_ SG_ 324 PdcuEnrgMod "PdcuEnergyMode能源模式";
CM_ SG_ 324 PdcuTqPatonRat "扭矩分配比";
CM_ SG_ 324 PdcuSelGearVld "PDCU发出的档位信号有效位";
CM_ SG_ 324 PdcuSelGear "Current Gear position当前档位";
CM_ SG_ 324 PdcuTqFltFlg "扭矩故障标志位";
CM_ SG_ 324 PdcuActvDchaEnaFlg "主动放电使能标志位";
CM_ SG_ 324 PdcuVehAllwRefrshFlg "整车允许刷写标志位";
CM_ SG_ 324 PdcuStrtActv "indicated ePT start processingePT系统启动过程，其余节点在启动过程中,该信号值为1时，屏蔽低电压故障";
CM_ SG_ 324 PdcuAccrPedl1Volt "油门踏板传感器1电压";
CM_ SG_ 324 PdcuAccrPedl1VoltVld "油门踏板传感器1电压有效位";
CM_ SG_ 267 PdcuAccPedalPosVld "物理油门踏板有效位";
CM_ SG_ 267 PdcuAccPedalPosDigVld "虚拟油门踏板信号有效位";
CM_ SG_ 267 PdcuAccPedalPos "物理油门踏板信号";
CM_ SG_ 267 PdcuAccPedalPosDig "虚拟油门踏板信号";
CM_ SG_ 267 PdcuEbrEnFlg "PDCU外部制动功能使能标志位";
CM_ SG_ 267 PdcuEbrReqFlg "PDCU需求外部制动激活标志位";
CM_ SG_ 267 PdcuEbrTagTrq "PDCU需求扭矩补偿目标值";
CM_ SG_ 267 PdcuEbrStandstillFlg "PDCU需求静态驻车标志位";
CM_ SG_ 267 PdcuAbsltAccrPedlPosn "用于OBD的绝对油门踏板位置（数据流冻结帧PID49）注：hcanfd的接收节点由pdcu从hcanfd发出";
CM_ SG_ 267 PdcuAccDriverOverride "驾驶员超越标志";
CM_ SG_ 267 PdcuEcAvailable "动力扭矩响应ACC—VLC或APA—VLC扭矩请求状态 ";
CM_ SG_ 267 PdcuApaShiftAvailable " APA自动换挡（PRND）功能可用标志";
CM_ SG_ 267 PdcuApaLeverIntervention " APA驾驶员换挡杆干预标志";
CM_ SG_ 290 Pdcu0x122Chks1 "CRC checksum. DataID and the following 7 bytes are included in CRC checksum calculation. Refer to E2E Spec.（Profile：1A，DataID=0x002B）";
CM_ SG_ 290 Pdcu0x122Cntr1 "Rolling counter. Refer to E2E Spec.";
CM_ SG_ 290 PdcuFrntAxleTrqReq "前轴需求扭矩";
CM_ SG_ 290 PdcuFrntAxleTrqReqVld "前轴需求扭矩有效位";
CM_ SG_ 290 PdcuFrntAxleTrqAct "前轴实际扭矩";
CM_ SG_ 290 PdcuFrntAxleTrqActVld "前轴实际扭矩有效位";
CM_ SG_ 290 PdcuFrntAxleTrqMaxLim "前轴最大可用扭矩";
CM_ SG_ 290 PdcuFrntAxleTrqMaxLimVld "前轴最大可用扭矩有效位";

BA_DEF_ BO_  "NmMessage" ENUM "No","Yes";
BA_DEF_ BO_  "DiagState" ENUM  "No","Yes";
BA_DEF_ BO_  "DiagResponse" ENUM  "No","Yes";
BA_DEF_ BO_  "GenMsgSendType" ENUM  "cyclic","NoMsgSendType","IfActive","Event","CA","CE";
BA_DEF_ BO_  "GenMsgCycleTime" INT 0 0;
BA_DEF_ SG_  "GenSigSendType" ENUM  "cyclic","OnChange","OnWrite","IfActive","OnChangeWithRepetition","OnWriteWithRepetition","IfActiveWithRepetition","CA","CE","Event";
BA_DEF_ SG_  "GenSigStartValue" INT 0 0;
BA_DEF_ BO_  "GenMsgCycleTimeFast" INT 0 0;
BA_DEF_ BO_  "GenMsgNrOfRepetition" INT 0 0;
BA_DEF_  "DBName" STRING ;
BA_DEF_ BO_  "CANFD_BRS" ENUM  "0","1";
BA_DEF_ BO_  "VFrameFormat" ENUM  "StandardCAN","ExtendedCAN","reserved","reserved","reserved","reserved","reserved","reserved","reserved","reserved","reserved","reserved","reserved","reserved","StandardCAN_FD","ExtendedCAN_FD";
BA_DEF_  "BusBaudateData" INT 0 10000;
BA_DEF_  "BusBaudateOther" INT 0 10000;
BA_DEF_ BO_  "GenMsgILSupport" ENUM  "No","Yes";
BA_DEF_  "NmBaseAddress" HEX 1024 1087;
BA_DEF_  "BusType" STRING ;
BA_DEF_ SG_ "sigDespEng" STRING;
BA_DEF_ SG_ "sigSecLevel" STRING;
BA_DEF_ SG_ "sigConfig" STRING;
BA_DEF_ SG_ "sigExplanation" STRING;

BA_DEF_DEF_  "NmMessage" "No";
BA_DEF_DEF_  "DiagState" "No";
BA_DEF_DEF_  "DiagResponse" "No";
BA_DEF_DEF_  "GenMsgSendType" "cyclic";
BA_DEF_DEF_  "GenMsgCycleTime" 0;
BA_DEF_DEF_  "GenSigSendType" "cyclic";
BA_DEF_DEF_  "GenSigStartValue" 0;
BA_DEF_DEF_  "GenMsgCycleTimeFast" 0;
BA_DEF_DEF_  "GenMsgNrOfRepetition" 0;
BA_DEF_DEF_  "DBName" "";
BA_DEF_DEF_  "CANFD_BRS" "1";
BA_DEF_DEF_  "VFrameFormat" "StandardCAN";
BA_DEF_DEF_  "BusBaudateData" 2;
BA_DEF_DEF_  "BusBaudateOther" 500;
BA_DEF_DEF_  "GenMsgILSupport" "Yes";
BA_DEF_DEF_  "NmBaseAddress" 1024;
BA_DEF_DEF_  "BusType" "CAN FD";
BA_DEF_DEF_ "sigDespEng" "" ;
BA_DEF_DEF_ "sigSecLevel" "QM" ;
BA_DEF_DEF_ "sigConfig" "" ;
BA_DEF_DEF_ "sigExplanation" "" ;
BA_ "DBName" "BAIC_B81VS_ADASBUS_Matrix_CANFD_V1.4_20260915";
BA_ "GenMsgCycleTime" BO_ 640 10;
BA_ "VFrameFormat" BO_ 640 14;
BA_ "sigSecLevel"  SG_ 640 EMS5_RollingCounter "";
BA_ "sigExplanation"  SG_ 640 EMS5_RollingCounter "tcm,fdca";
BA_ "sigSecLevel"  SG_ 640 EMS5_F_BrakePedal "";
BA_ "sigExplanation"  SG_ 640 EMS5_F_BrakePedal "tcm,wcbsesp,sdm,fdca,dvr,apa,bdcbcm,tbox";
BA_ "sigSecLevel"  SG_ 640 EMS5_St_BrakePedal "";
BA_ "sigExplanation"  SG_ 640 EMS5_St_BrakePedal "tcm,wcbsesp,sdm,fdca,dvr,apa,bdcbcm,tbox";
BA_ "sigSecLevel"  SG_ 640 EMS5_St_LimpHome "";
BA_ "sigExplanation"  SG_ 640 EMS5_St_LimpHome "fdca,apa,tbox";
BA_ "sigSecLevel"  SG_ 640 EMS5_Checksum "";
BA_ "sigExplanation"  SG_ 640 EMS5_Checksum "tcm,fdca";
BA_ "GenMsgCycleTime" BO_ 792 20;
BA_ "VFrameFormat" BO_ 792 14;
BA_ "sigDespEng"  SG_ 792 WCBS_ESP1_St_AutoHoldAvailable "AH条件";
BA_ "sigSecLevel"  SG_ 792 WCBS_ESP1_St_AutoHoldAvailable "";
BA_ "sigExplanation"  SG_ 792 WCBS_ESP1_St_AutoHoldAvailable "wcbsepb,fdca,ipc,apa，tbox";
BA_ "sigDespEng"  SG_ 792 WCBS_ESP1_St_AutoHold "AH状态";
BA_ "sigSecLevel"  SG_ 792 WCBS_ESP1_St_AutoHold "";
BA_ "sigExplanation"  SG_ 792 WCBS_ESP1_St_AutoHold "ems,tcm,wcbsepb,fdca,ipc,apa,tbox，bdcbcm";
BA_ "sigDespEng"  SG_ 792 WCBS_ESP1_St_AutoHoldTelltale "AH故障";
BA_ "sigSecLevel"  SG_ 792 WCBS_ESP1_St_AutoHoldTelltale "";
BA_ "sigExplanation"  SG_ 792 WCBS_ESP1_St_AutoHoldTelltale "wcbsepb,fdca,ipc,tbox，bdcbcm";
BA_ "sigSecLevel"  SG_ 792 WCBS_ESP1_Cmd_EPBPark "";
BA_ "sigExplanation"  SG_ 792 WCBS_ESP1_Cmd_EPBPark "wcbsepb,apa,tbox";
BA_ "sigSecLevel"  SG_ 792 WCBS_ESP1_St_TCSActive "";
BA_ "sigExplanation"  SG_ 792 WCBS_ESP1_St_TCSActive "tcm,wcbsepb,sdm,fdca,apa,tbox,wcbsats";
BA_ "GenSigStartValue" SG_ 792 WCBS_ESP1_St_BrakeLightControl 1;
BA_ "sigSecLevel"  SG_ 792 WCBS_ESP1_St_BrakeLightControl "";
BA_ "sigExplanation"  SG_ 792 WCBS_ESP1_St_BrakeLightControl "tcm,apa,bdcbcm";
BA_ "sigSecLevel"  SG_ 792 WCBS_ESP1_St_ABSActive "";
BA_ "sigExplanation"  SG_ 792 WCBS_ESP1_St_ABSActive "tcm,sdm,fdca,apa,tbox,wcbsats";
BA_ "sigSecLevel"  SG_ 792 WCBS_ESP1_St_EBDActive "";
BA_ "sigExplanation"  SG_ 792 WCBS_ESP1_St_EBDActive "apa，tbox";
BA_ "sigSecLevel"  SG_ 792 WCBS_ESP1_St_ESPFailureTelltale "";
BA_ "sigExplanation"  SG_ 792 WCBS_ESP1_St_ESPFailureTelltale "tcm,wcbsepb,sdm,ipc,ehc,apa,tbox";
BA_ "sigSecLevel"  SG_ 792 WCBS_ESP1_St_ESPTCSOffTelltale "";
BA_ "sigExplanation"  SG_ 792 WCBS_ESP1_St_ESPTCSOffTelltale "tcm,sdm,ipc,ehc,apa,tbox";
BA_ "sigSecLevel"  SG_ 792 WCBS_ESP1_St_DecelerationActive "";
BA_ "sigExplanation"  SG_ 792 WCBS_ESP1_St_DecelerationActive "wcbsepb,fdca,tbox";
BA_ "sigSecLevel"  SG_ 792 WCBS_ESP1_St_ABSTelltale "";
BA_ "sigExplanation"  SG_ 792 WCBS_ESP1_St_ABSTelltale "tcm, sdm,fdca,ipc,tbox";
BA_ "sigSecLevel"  SG_ 792 WCBS_ESP1_St_EBDTelltale "";
BA_ "sigExplanation"  SG_ 792 WCBS_ESP1_St_EBDTelltale "fdca,ipc,tbox";
BA_ "sigSecLevel"  SG_ 792 WCBS_ESP1_St_ESPActive "";
BA_ "sigExplanation"  SG_ 792 WCBS_ESP1_St_ESPActive "tcm,sdm,fdca,apa,tbox,wcbsats，tbox";
BA_ "sigSecLevel"  SG_ 792 WCBS_ESP1_St_ESPTCSActiveTelltale "";
BA_ "sigExplanation"  SG_ 792 WCBS_ESP1_St_ESPTCSActiveTelltale "wcbsats,ipc,apa,tbox";
BA_ "sigSecLevel"  SG_ 792 WCBS_ESP1_St_HDCTelltale "";
BA_ "sigExplanation"  SG_ 792 WCBS_ESP1_St_HDCTelltale "ems,tcm,wcbsepb,fdca,ipc,tbox";
BA_ "sigSecLevel"  SG_ 792 WCBS_ESP1_N_OdometerRoll "";
BA_ "sigExplanation"  SG_ 792 WCBS_ESP1_N_OdometerRoll "ipc,apa,tbox";
BA_ "sigSecLevel"  SG_ 792 WCBS_ESP1_St_WCBSFault "";
BA_ "sigExplanation"  SG_ 792 WCBS_ESP1_St_WCBSFault "sdm,ipc,apa，tbox";
BA_ "sigSecLevel"  SG_ 792 WCBS_ESP1_St_BrakeFluidW "";
BA_ "sigExplanation"  SG_ 792 WCBS_ESP1_St_BrakeFluidW "ipc,apa,tbox";
BA_ "sigSecLevel"  SG_ 792 WCBS_ESP1_RollingCounter "";
BA_ "sigExplanation"  SG_ 792 WCBS_ESP1_RollingCounter "fdca,apa，tbox";
BA_ "sigSecLevel"  SG_ 792 WCBS_ESP1_Checksum "";
BA_ "sigExplanation"  SG_ 792 WCBS_ESP1_Checksum "fdca,apa，tbox";
BA_ "GenMsgCycleTime" BO_ 288 20;
BA_ "VFrameFormat" BO_ 288 14;
BA_ "sigDespEng"  SG_ 288 WCBS_ESP2_RollingCounter "EP必须发";
BA_ "sigSecLevel"  SG_ 288 WCBS_ESP2_RollingCounter "";
BA_ "sigExplanation"  SG_ 288 WCBS_ESP2_RollingCounter "ems,fdca";
BA_ "sigDespEng"  SG_ 288 WCBS_ESP2_St_EngineIntervention "PTC状态位，保留";
BA_ "sigSecLevel"  SG_ 288 WCBS_ESP2_St_EngineIntervention "";
BA_ "sigExplanation"  SG_ 288 WCBS_ESP2_St_EngineIntervention "ems,fdca";
BA_ "sigDespEng"  SG_ 288 WCBS_ESP2_St_BrakeIntervention "BTC状态位，保留";
BA_ "sigSecLevel"  SG_ 288 WCBS_ESP2_St_BrakeIntervention "";
BA_ "sigExplanation"  SG_ 288 WCBS_ESP2_St_BrakeIntervention "tcm，fdca";
BA_ "sigDespEng"  SG_ 288 WCBS_ESP2_St_EngineDragTor "DTC状态位，保留";
BA_ "sigSecLevel"  SG_ 288 WCBS_ESP2_St_EngineDragTor "";
BA_ "sigExplanation"  SG_ 288 WCBS_ESP2_St_EngineDragTor "ems,fdca";
BA_ "sigDespEng"  SG_ 288 WCBS_ESP2_Checksum "EP必须发";
BA_ "sigSecLevel"  SG_ 288 WCBS_ESP2_Checksum "";
BA_ "sigExplanation"  SG_ 288 WCBS_ESP2_Checksum "ems,fdca";
BA_ "GenMsgCycleTime" BO_ 1600 20;
BA_ "VFrameFormat" BO_ 1600 14;
BA_ "sigSecLevel"  SG_ 1600 WCBS_ESP3_F_FLWheelSpeed "";
BA_ "sigExplanation"  SG_ 1600 WCBS_ESP3_F_FLWheelSpeed "ems,tcm,tccu,fdca,eps,eds,apa,escl,bdcpeps,tbox,wddc";
BA_ "sigSecLevel"  SG_ 1600 WCBS_ESP3_N_FLWheelSpeed "";
BA_ "sigExplanation"  SG_ 1600 WCBS_ESP3_N_FLWheelSpeed "ems,tcm,tccu,fdca,eps,eds,apa,escl,bdcpeps,tbox，wddc";
BA_ "sigSecLevel"  SG_ 1600 WCBS_ESP3_F_FRWheelSpeed "";
BA_ "sigExplanation"  SG_ 1600 WCBS_ESP3_F_FRWheelSpeed "ems,tcm,tccu,fdca,eps,eds,apa,escl,bdcpeps,tbox,wddc";
BA_ "sigSecLevel"  SG_ 1600 WCBS_ESP3_N_FRWheelSpeed "";
BA_ "sigExplanation"  SG_ 1600 WCBS_ESP3_N_FRWheelSpeed "ems,tcm,tccu,fdca,eps,eds,apa,escl,bdcpeps,tbox,wddc";
BA_ "sigSecLevel"  SG_ 1600 WCBS_ESP3_RollingCounter "";
BA_ "sigExplanation"  SG_ 1600 WCBS_ESP3_RollingCounter "ems,tcm,tccu,fdca,eps,eds,apa,escl,bdcpeps,wddc";
BA_ "sigSecLevel"  SG_ 1600 WCBS_ESP3_Checksum "";
BA_ "sigExplanation"  SG_ 1600 WCBS_ESP3_Checksum "ems,tcm,tccu,fdca,eps,eds,apa,escl,bdcpeps,wddc";
BA_ "GenMsgCycleTime" BO_ 1616 20;
BA_ "VFrameFormat" BO_ 1616 14;
BA_ "sigSecLevel"  SG_ 1616 WCBS_ESP4_N_BrakePedalStroke "";
BA_ "sigExplanation"  SG_ 1616 WCBS_ESP4_N_BrakePedalStroke "ems,FDCA";
BA_ "sigSecLevel"  SG_ 1616 WCBS_ESP4_F_BrakePedalStroke "";
BA_ "sigExplanation"  SG_ 1616 WCBS_ESP4_F_BrakePedalStroke "ems,FDCA";
BA_ "sigSecLevel"  SG_ 1616 WCBS_ESP4_Checksum "";
BA_ "sigExplanation"  SG_ 1616 WCBS_ESP4_Checksum "ems,tcm,tccu,fdca,eps,eds,apa,escl,bdcpeps,wddc";
BA_ "sigSecLevel"  SG_ 1616 WCBS_ESP4_RollingCounter "";
BA_ "sigExplanation"  SG_ 1616 WCBS_ESP4_RollingCounter "ems,tcm,tccu,fdca,eps,eds,apa,escl,bdcpeps,wddc";
BA_ "sigSecLevel"  SG_ 1616 WCBS_ESP4_F_RLWheelSpeed "";
BA_ "sigExplanation"  SG_ 1616 WCBS_ESP4_F_RLWheelSpeed "ems,tcm,tccu,fdca,eps,eds,apa,escl,bdcpeps,tbox";
BA_ "sigSecLevel"  SG_ 1616 WCBS_ESP4_N_RLWheelSpeed "";
BA_ "sigExplanation"  SG_ 1616 WCBS_ESP4_N_RLWheelSpeed "ems,tcm,tccu,fdca,eps,eds,apa,escl,bdcpeps,tbox,wddc";
BA_ "sigSecLevel"  SG_ 1616 WCBS_ESP4_F_RRWheelSpeed "";
BA_ "sigExplanation"  SG_ 1616 WCBS_ESP4_F_RRWheelSpeed "ems,tcm,tccu,fdca,eps,eds,apa,escl,bdcpeps,tbox,wddc";
BA_ "sigSecLevel"  SG_ 1616 WCBS_ESP4_N_RRWheelSpeed "";
BA_ "sigExplanation"  SG_ 1616 WCBS_ESP4_N_RRWheelSpeed "ems,tcm,tccu,fdca,eps,eds,apa,escl,bdcpeps,tbox,wddc";
BA_ "GenMsgCycleTime" BO_ 785 20;
BA_ "VFrameFormat" BO_ 785 14;
BA_ "GenSigStartValue" SG_ 785 WCBS_ESP5_St_VehicleStandstill 1;
BA_ "sigSecLevel"  SG_ 785 WCBS_ESP5_St_VehicleStandstill "";
BA_ "sigExplanation"  SG_ 785 WCBS_ESP5_St_VehicleStandstill "fdca,apa,bdcpeps,bdcbcm,tbox";
BA_ "sigSecLevel"  SG_ 785 WCBS_ESP5_St_APAVLC "";
BA_ "sigExplanation"  SG_ 785 WCBS_ESP5_St_APAVLC "ems,tcm,apa";
BA_ "sigSecLevel"  SG_ 785 WCBS_ESP5_St_APACDDActive "";
BA_ "sigExplanation"  SG_ 785 WCBS_ESP5_St_APACDDActive "ems,tcm";
BA_ "sigSecLevel"  SG_ 785 WCBS_ESP5_St_GearInhit "";
BA_ "sigExplanation"  SG_ 785 WCBS_ESP5_St_GearInhit "tcm,fdca,apa";
BA_ "sigSecLevel"  SG_ 785 WCBS_ESP5_RollingCounter "";
BA_ "sigExplanation"  SG_ 785 WCBS_ESP5_RollingCounter "ems,tcm,fdca,eps,eds,amp,pas,apa";
BA_ "sigSecLevel"  SG_ 785 WCBS_ESP5_F_VehicleSpeed "";
BA_ "sigExplanation"  SG_ 785 WCBS_ESP5_F_VehicleSpeed "ems,tcm,tccu,fdca,eps,eds,orim,amp,cmwr,pas,ipc,ehc,apa,dsm,ac,bdcbcm,tbox,swh";
BA_ "sigSecLevel"  SG_ 785 WCBS_ESP5_St_APACDDAv "";
BA_ "sigExplanation"  SG_ 785 WCBS_ESP5_St_APACDDAv "ems,apa";
BA_ "GenSigStartValue" SG_ 785 WCBS_ESP5_St_NoBrakeForce 1;
BA_ "sigSecLevel"  SG_ 785 WCBS_ESP5_St_NoBrakeForce "";
BA_ "sigExplanation"  SG_ 785 WCBS_ESP5_St_NoBrakeForce "fdca";
BA_ "sigSecLevel"  SG_ 785 WCBS_ESP5_St_ACCCDDActive "";
BA_ "sigExplanation"  SG_ 785 WCBS_ESP5_St_ACCCDDActive "fdca,ems,tcm,tbox";
BA_ "sigSecLevel"  SG_ 785 WCBS_ESP5_St_ACCCDDAv "";
BA_ "sigExplanation"  SG_ 785 WCBS_ESP5_St_ACCCDDAv "fdca,ems";
BA_ "sigSecLevel"  SG_ 785 WCBS_ESP5_St_ABAactive "";
BA_ "sigExplanation"  SG_ 785 WCBS_ESP5_St_ABAactive "fdca";
BA_ "sigSecLevel"  SG_ 785 WCBS_ESP5_St_ABAavailable "";
BA_ "sigExplanation"  SG_ 785 WCBS_ESP5_St_ABAavailable "fdca";
BA_ "sigSecLevel"  SG_ 785 WCBS_ESP5_St_PrefillActive "";
BA_ "sigExplanation"  SG_ 785 WCBS_ESP5_St_PrefillActive "fdca";
BA_ "sigSecLevel"  SG_ 785 WCBS_ESP5_St_PrefillAvailable "";
BA_ "sigExplanation"  SG_ 785 WCBS_ESP5_St_PrefillAvailable "fdca";
BA_ "sigSecLevel"  SG_ 785 WCBS_ESP5_St_AEBdecActive "";
BA_ "sigExplanation"  SG_ 785 WCBS_ESP5_St_AEBdecActive "fdca,ems,tcm,tbox";
BA_ "sigSecLevel"  SG_ 785 WCBS_ESP5_St_AEBdecAv "";
BA_ "sigExplanation"  SG_ 785 WCBS_ESP5_St_AEBdecAv "fdca,ems,tbox";
BA_ "sigSecLevel"  SG_ 785 WCBS_ESP5_St_DecSupportAc "";
BA_ "sigExplanation"  SG_ 785 WCBS_ESP5_St_DecSupportAc "fdca";
BA_ "sigSecLevel"  SG_ 785 WCBS_ESP5_St_DecSupportAv "";
BA_ "sigExplanation"  SG_ 785 WCBS_ESP5_St_DecSupportAv "fdca";
BA_ "sigSecLevel"  SG_ 785 WCBS_ESP5_AWBactive "";
BA_ "sigExplanation"  SG_ 785 WCBS_ESP5_AWBactive "fdca";
BA_ "sigSecLevel"  SG_ 785 WCBS_ESP5_AWBavailable "";
BA_ "sigExplanation"  SG_ 785 WCBS_ESP5_AWBavailable "fdca";
BA_ "sigSecLevel"  SG_ 785 WCBS_ESP5_QDCFail "";
BA_ "sigExplanation"  SG_ 785 WCBS_ESP5_QDCFail "fdca";
BA_ "sigSecLevel"  SG_ 785 WCBS_ESP5_BrakeOverheat "";
BA_ "sigExplanation"  SG_ 785 WCBS_ESP5_BrakeOverheat "fdca,tbox";
BA_ "sigSecLevel"  SG_ 785 WCBS_ESP5_N_VehicleSpeed "";
BA_ "sigExplanation"  SG_ 785 WCBS_ESP5_N_VehicleSpeed "ems,tcm,tccu,fdca,eps,eds,orim,amp,wddc,cmwr,pas,ipc,ehc,apa,dsm,bdcbcm,ac,tbox,swh";
BA_ "sigSecLevel"  SG_ 785 WCBS_ESP5_St_APALCFailure "";
BA_ "sigExplanation"  SG_ 785 WCBS_ESP5_St_APALCFailure "apa";
BA_ "sigSecLevel"  SG_ 785 WCBS_ESP5_St_APAVLCAv "";
BA_ "sigExplanation"  SG_ 785 WCBS_ESP5_St_APAVLCAv "apa.ems";
BA_ "sigSecLevel"  SG_ 785 WCBS_ESP5_St_TCSOffTelltale "";
BA_ "sigExplanation"  SG_ 785 WCBS_ESP5_St_TCSOffTelltale "sdm,fdca,ipc,ehc";
BA_ "sigSecLevel"  SG_ 785 WCBS_ESP5_Checksum "";
BA_ "sigExplanation"  SG_ 785 WCBS_ESP5_Checksum "ems,tcm,fdca,eps,eds,amp,pas,apa";
BA_ "GenMsgCycleTime" BO_ 1008 20;
BA_ "VFrameFormat" BO_ 1008 14;
BA_ "sigSecLevel"  SG_ 1008 WCBS_ESP6_F_LongitudeAcc "";
BA_ "sigExplanation"  SG_ 1008 WCBS_ESP6_F_LongitudeAcc "ems,tcm,fdca,cmwr,apa";
BA_ "sigSecLevel"  SG_ 1008 WCBS_ESP6_F_LateralAcc "";
BA_ "sigExplanation"  SG_ 1008 WCBS_ESP6_F_LateralAcc "ems,tcm,fdca,cmwr,apa";
BA_ "sigSecLevel"  SG_ 1008 WCBS_ESP6_F_YawVelocity "";
BA_ "sigExplanation"  SG_ 1008 WCBS_ESP6_F_YawVelocity "ems,sdm,fdca,cmwr,apa";
BA_ "sigSecLevel"  SG_ 1008 WCBS_ESP6_F_BrakePressure "";
BA_ "sigExplanation"  SG_ 1008 WCBS_ESP6_F_BrakePressure "ems,tcm,fdca";
BA_ "sigSecLevel"  SG_ 1008 WCBS_ESP6_RollingCounter "";
BA_ "sigExplanation"  SG_ 1008 WCBS_ESP6_RollingCounter "fdca,apa";
BA_ "sigSecLevel"  SG_ 1008 WCBS_ESP6_N_LongitudeAcc "";
BA_ "sigExplanation"  SG_ 1008 WCBS_ESP6_N_LongitudeAcc "ems,tcm,fdca,cmwr,apa,eps";
BA_ "sigSecLevel"  SG_ 1008 WCBS_ESP6_FCTB_avaliable "";
BA_ "sigExplanation"  SG_ 1008 WCBS_ESP6_FCTB_avaliable "CMRR";
BA_ "sigSecLevel"  SG_ 1008 WCBS_ESP6_RCTB_avaliable "";
BA_ "sigExplanation"  SG_ 1008 WCBS_ESP6_RCTB_avaliable "CMRR";
BA_ "sigSecLevel"  SG_ 1008 WCBS_ESP6_N_LateralAcc "";
BA_ "sigExplanation"  SG_ 1008 WCBS_ESP6_N_LateralAcc "ems,tcm,fdca,cmwr,apa，eps";
BA_ "sigSecLevel"  SG_ 1008 WCBS_ESP6_N_YawVelocity "";
BA_ "sigExplanation"  SG_ 1008 WCBS_ESP6_N_YawVelocity "ems,sdm,fdca,eps,cmwr,apa,tbox";
BA_ "sigSecLevel"  SG_ 1008 WCBS_ESP6_Checksum "";
BA_ "sigExplanation"  SG_ 1008 WCBS_ESP6_Checksum "fdca,apa";
BA_ "sigSecLevel"  SG_ 1008 WCBS_ESP6_N_BrakePressure "";
BA_ "sigExplanation"  SG_ 1008 WCBS_ESP6_N_BrakePressure "ems,tcm,fdca,tbox";
BA_ "GenMsgCycleTime" BO_ 579 20;
BA_ "VFrameFormat" BO_ 579 14;
BA_ "sigSecLevel"  SG_ 579 WCBS_ESP10_N_FRPulse "";
BA_ "sigExplanation"  SG_ 579 WCBS_ESP10_N_FRPulse "fdca,apa,bdctpms";
BA_ "sigSecLevel"  SG_ 579 WCBS_ESP10_N_FLPulse "";
BA_ "sigExplanation"  SG_ 579 WCBS_ESP10_N_FLPulse "fdca,apa,bdctpms";
BA_ "sigSecLevel"  SG_ 579 WCBS_ESP10_N_RRPulse "";
BA_ "sigExplanation"  SG_ 579 WCBS_ESP10_N_RRPulse "fdca,apa,bdctpms";
BA_ "sigSecLevel"  SG_ 579 WCBS_ESP10_N_RLPulse "";
BA_ "sigExplanation"  SG_ 579 WCBS_ESP10_N_RLPulse "fdca,apa,bdctpms";
BA_ "sigSecLevel"  SG_ 579 WCBS_ESP10_F_FRPulse "";
BA_ "sigExplanation"  SG_ 579 WCBS_ESP10_F_FRPulse "fdca,apa,bdctpms";
BA_ "sigSecLevel"  SG_ 579 WCBS_ESP10_F_FLPulse "";
BA_ "sigExplanation"  SG_ 579 WCBS_ESP10_F_FLPulse "fdca,apa,bdctpms";
BA_ "sigSecLevel"  SG_ 579 WCBS_ESP10_F_RRPulse "";
BA_ "sigExplanation"  SG_ 579 WCBS_ESP10_F_RRPulse "fdca,apa,bdctpms";
BA_ "sigSecLevel"  SG_ 579 WCBS_ESP10_F_RLPulse "";
BA_ "sigExplanation"  SG_ 579 WCBS_ESP10_F_RLPulse "fdca,apa,bdctpms";
BA_ "sigSecLevel"  SG_ 579 WCBS_ESP10_St_HBA "";
BA_ "sigExplanation"  SG_ 579 WCBS_ESP10_St_HBA "bdctpms,tbox";
BA_ "sigSecLevel"  SG_ 579 WCBS_ESP10_St_HHC "";
BA_ "sigExplanation"  SG_ 579 WCBS_ESP10_St_HHC "bdctpms,tcm,tbox";
BA_ "sigSecLevel"  SG_ 579 WCBS_ESP10_RollingCounter "";
BA_ "sigExplanation"  SG_ 579 WCBS_ESP10_RollingCounter "tcm,fdca,apa,bdctpms";
BA_ "sigSecLevel"  SG_ 579 WCBS_ESP10_Checksum "";
BA_ "sigExplanation"  SG_ 579 WCBS_ESP10_Checksum "tcm,fdca,apa,bdctpms";
BA_ "GenMsgCycleTime" BO_ 578 20;
BA_ "VFrameFormat" BO_ 578 14;
BA_ "sigSecLevel"  SG_ 578 WCBS_ESP13_St_VDCFail "";
BA_ "sigExplanation"  SG_ 578 WCBS_ESP13_St_VDCFail "fdca";
BA_ "sigSecLevel"  SG_ 578 WCBS_ESP13_St_BrakePedal "";
BA_ "sigExplanation"  SG_ 578 WCBS_ESP13_St_BrakePedal "ems,fdca，apa";
BA_ "sigSecLevel"  SG_ 578 WCBS_ESP13_St_TCSFail "";
BA_ "sigExplanation"  SG_ 578 WCBS_ESP13_St_TCSFail "sdm,fdca";
BA_ "sigSecLevel"  SG_ 578 WCBS_ESP13_St_ACCVLCActive "";
BA_ "sigExplanation"  SG_ 578 WCBS_ESP13_St_ACCVLCActive "ems,tcm,fdca,tbox";
BA_ "sigSecLevel"  SG_ 578 WCBS_ESP13_St_VLCAvailable "";
BA_ "sigExplanation"  SG_ 578 WCBS_ESP13_St_VLCAvailable "fdca,tbox";
BA_ "sigSecLevel"  SG_ 578 WCBS_ESP13_St_VLCFail "";
BA_ "sigExplanation"  SG_ 578 WCBS_ESP13_St_VLCFail "fdca";
BA_ "sigSecLevel"  SG_ 578 WCBS_ESP13_N_VLCITA "";
BA_ "sigExplanation"  SG_ 578 WCBS_ESP13_N_VLCITA "fdca";
BA_ "sigSecLevel"  SG_ 578 WCBS_ESP13_St_LHFWDD "";
BA_ "sigExplanation"  SG_ 578 WCBS_ESP13_St_LHFWDD "fdca,cmwr,apa";
BA_ "sigSecLevel"  SG_ 578 WCBS_ESP13_St_RHFWDD "";
BA_ "sigExplanation"  SG_ 578 WCBS_ESP13_St_RHFWDD "fdca,cmwr,apa";
BA_ "sigSecLevel"  SG_ 578 WCBS_ESP13_St_DCFail "";
BA_ "sigExplanation"  SG_ 578 WCBS_ESP13_St_DCFail "fdca";
BA_ "sigSecLevel"  SG_ 578 WCBS_ESP13_St_LHRWDD "";
BA_ "sigExplanation"  SG_ 578 WCBS_ESP13_St_LHRWDD "fdca,cmwr,pas,apa";
BA_ "sigSecLevel"  SG_ 578 WCBS_ESP13_St_RHRWDD "";
BA_ "sigExplanation"  SG_ 578 WCBS_ESP13_St_RHRWDD "fdca,cmwr,pas,apa";
BA_ "sigSecLevel"  SG_ 578 WCBS_ESP13_St_CCOActive "";
BA_ "sigExplanation"  SG_ 578 WCBS_ESP13_St_CCOActive "ems,tcm,css,fdca,hud,ipc,apa";
BA_ "sigSecLevel"  SG_ 578 WCBS_ESP13_RollingCounter "";
BA_ "sigExplanation"  SG_ 578 WCBS_ESP13_RollingCounter "fdca,pas,apa";
BA_ "sigSecLevel"  SG_ 578 WCBS_ESP13_CheckSum "";
BA_ "sigExplanation"  SG_ 578 WCBS_ESP13_CheckSum "fdca,pas,apa";
BA_ "GenMsgCycleTime" BO_ 784 20;
BA_ "VFrameFormat" BO_ 784 14;
BA_ "sigSecLevel"  SG_ 784 EPB1_RollingCounter "";
BA_ "sigExplanation"  SG_ 784 EPB1_RollingCounter "ems,tcm,pas,apa";
BA_ "sigSecLevel"  SG_ 784 EPB1_St_WarningLamp "";
BA_ "sigExplanation"  SG_ 784 EPB1_St_WarningLamp "sdm,fdca,ipc,tbox";
BA_ "sigSecLevel"  SG_ 784 EPB1_St_ActuatorStL "";
BA_ "sigExplanation"  SG_ 784 EPB1_St_ActuatorStL "fdca,bdcpeps,bdcbcm,tbox";
BA_ "sigSecLevel"  SG_ 784 EPB1_St_ActuatorStR "";
BA_ "sigExplanation"  SG_ 784 EPB1_St_ActuatorStR "fdca,bdcpeps,bdcbcm,tbox";
BA_ "sigSecLevel"  SG_ 784 EPB1_St_EPBSwitch "";
BA_ "sigExplanation"  SG_ 784 EPB1_St_EPBSwitch "apa,tbox";
BA_ "sigSecLevel"  SG_ 784 EPB1_Cmd_CruiseControlCancel "";
BA_ "sigExplanation"  SG_ 784 EPB1_Cmd_CruiseControlCancel "ems,fdca";
BA_ "sigSecLevel"  SG_ 784 EPB1_St_DynamicApply "";
BA_ "sigExplanation"  SG_ 784 EPB1_St_DynamicApply "tcm,wcbsesp,tbox";
BA_ "sigSecLevel"  SG_ 784 EPB1_St_EARFail "";
BA_ "sigExplanation"  SG_ 784 EPB1_St_EARFail "apa";
BA_ "sigSecLevel"  SG_ 784 EPB1_St_ParkBrake "";
BA_ "sigExplanation"  SG_ 784 EPB1_St_ParkBrake "ems,tcm,fdca,pas,apa,bdcbcm,tbox";
BA_ "sigSecLevel"  SG_ 784 EPB1_checksum "";
BA_ "sigExplanation"  SG_ 784 EPB1_checksum "ems,tcm,pas,apa";
BA_ "GenMsgCycleTime" BO_ 1297 20;
BA_ "VFrameFormat" BO_ 1297 14;
BA_ "sigSecLevel"  SG_ 1297 ATS1_RollingCounter "";
BA_ "sigExplanation"  SG_ 1297 ATS1_RollingCounter "ems,tcm,wcbsesp,tccu,fdca,avm,tbox，apa";
BA_ "sigSecLevel"  SG_ 1297 ATS_Cmd_RqPerChassis "";
BA_ "sigExplanation"  SG_ 1297 ATS_Cmd_RqPerChassis "apa，avm";
BA_ "sigDespEng"  SG_ 1297 PdcuDrvModCfmd "ATS1_St_ConfirmedMode";
BA_ "sigSecLevel"  SG_ 1297 PdcuDrvModCfmd "";
BA_ "sigExplanation"  SG_ 1297 PdcuDrvModCfmd "ems,tcm,wcbsesp,tccu,fdca,avm,tbox，css,eps,hud,wddc,ipc,ehc,apa,ssbs,ac,bdcbcm,alc";
BA_ "sigSecLevel"  SG_ 1297 ATS1_Checksum "";
BA_ "sigExplanation"  SG_ 1297 ATS1_Checksum "ems,tcm,wcbsesp,tccu,fdca,avm,tbox，apa";
BA_ "GenMsgCycleTime" BO_ 384 10;
BA_ "VFrameFormat" BO_ 384 14;
BA_ "sigDespEng"  SG_ 384 EPS_SAS_Checksum "EP必须发";
BA_ "sigSecLevel"  SG_ 384 EPS_SAS_Checksum "";
BA_ "sigExplanation"  SG_ 384 EPS_SAS_Checksum "ems,tcm,wcbsesp,fdca,eps,apa";
BA_ "sigDespEng"  SG_ 384 EPS_SAS_RollingCounter "EP必须发";
BA_ "sigSecLevel"  SG_ 384 EPS_SAS_RollingCounter "";
BA_ "sigExplanation"  SG_ 384 EPS_SAS_RollingCounter "ems,tcm,wcbsesp,fdca,eps,apa";
BA_ "sigDespEng"  SG_ 384 EPS_SAS_St_Calibrated "EP必须发";
BA_ "sigSecLevel"  SG_ 384 EPS_SAS_St_Calibrated "";
BA_ "sigExplanation"  SG_ 384 EPS_SAS_St_Calibrated "wcbsesp,fdca,apa";
BA_ "sigDespEng"  SG_ 384 EPS_SAS_St_SensorInfo "EP必须发";
BA_ "sigSecLevel"  SG_ 384 EPS_SAS_St_SensorInfo "";
BA_ "sigExplanation"  SG_ 384 EPS_SAS_St_SensorInfo "ems,tcm,wcbsesp,fdca,eps,wddc,cmwr,ipc,ehc,apa,tbox,bdcbcm";
BA_ "sigDespEng"  SG_ 384 EPS_SAS_N_RotationSpeed "EP必须发";
BA_ "sigSecLevel"  SG_ 384 EPS_SAS_N_RotationSpeed "";
BA_ "sigExplanation"  SG_ 384 EPS_SAS_N_RotationSpeed "wcbsesp,fdca,apa,tbox";
BA_ "GenSigStartValue" SG_ 384 EPS_SAS_N_SteeringAngle 7800;
BA_ "sigDespEng"  SG_ 384 EPS_SAS_N_SteeringAngle "EP必须发";
BA_ "sigSecLevel"  SG_ 384 EPS_SAS_N_SteeringAngle "";
BA_ "sigConfig"  SG_ 384 EPS_SAS_N_SteeringAngle "tsp";
BA_ "sigExplanation"  SG_ 384 EPS_SAS_N_SteeringAngle "ems,tcm,wcbsesp,sdm,fdca,eps,wddc,cmwr,ipc,ehc,apa,tbox,bdcbcm";
BA_ "sigSecLevel"  SG_ 384 EPS_St_DrvStrInterDeteToADAS "";
BA_ "sigExplanation"  SG_ 384 EPS_St_DrvStrInterDeteToADAS "FDCA";
BA_ "sigSecLevel"  SG_ 384 EPS_F_DrvStrInterDeteToADAS "";
BA_ "sigExplanation"  SG_ 384 EPS_F_DrvStrInterDeteToADAS "FDCA";
BA_ "sigDespEng"  SG_ 384 EPS_SysAvlSts_APA "显示EPS是否支持APA功能激活";
BA_ "sigSecLevel"  SG_ 384 EPS_SysAvlSts_APA "";
BA_ "sigConfig"  SG_ 384 EPS_SysAvlSts_APA "B81";
BA_ "sigDespEng"  SG_ 384 EPS_APA_FuncMode "当EPS执行APA功能时，会反馈此信号";
BA_ "sigSecLevel"  SG_ 384 EPS_APA_FuncMode "";
BA_ "sigConfig"  SG_ 384 EPS_APA_FuncMode "B81";
BA_ "sigDespEng"  SG_ 384 EPS_AbortFb "当EPS退出APA功能时，会反馈此信号";
BA_ "sigSecLevel"  SG_ 384 EPS_AbortFb "";
BA_ "sigConfig"  SG_ 384 EPS_AbortFb "B81";
BA_ "sigDespEng"  SG_ 384 EPS_EPSAvl "是否支持ADAS功能的状态信号";
BA_ "sigSecLevel"  SG_ 384 EPS_EPSAvl "";
BA_ "sigConfig"  SG_ 384 EPS_EPSAvl "B81";
BA_ "sigDespEng"  SG_ 384 EPS_OverrangeFeedback "EPS检测ADAS请求超限状态，会反馈响应的超限原因";
BA_ "sigSecLevel"  SG_ 384 EPS_OverrangeFeedback "";
BA_ "sigConfig"  SG_ 384 EPS_OverrangeFeedback "B81";
BA_ "sigDespEng"  SG_ 384 EPS_SteerWorkStatus "EPS工作状态，是在执行人驾还是角度请求还是扭矩请求";
BA_ "sigSecLevel"  SG_ 384 EPS_SteerWorkStatus "";
BA_ "sigConfig"  SG_ 384 EPS_SteerWorkStatus "B81";
BA_ "GenMsgCycleTime" BO_ 848 100;
BA_ "GenMsgCycleTimeFast" BO_ 848 20;
BA_ "GenMsgNrOfRepetition" BO_ 848 10;
BA_ "VFrameFormat" BO_ 848 14;
BA_ "GenSigSendType" SG_ 848 SDM1_St_AirbagDeployed 4;
BA_ "sigSecLevel"  SG_ 848 SDM1_St_AirbagDeployed "";
BA_ "sigExplanation"  SG_ 848 SDM1_St_AirbagDeployed "ems,fdca,dvr,apa,bdcbcm,bsg,bms,tbox";
BA_ "sigSecLevel"  SG_ 848 SDM1_RollingCounter "";
BA_ "sigExplanation"  SG_ 848 SDM1_RollingCounter "ems,tcm,fdca,dvr,apa,bdcbcm,bsg,bms";
BA_ "sigSecLevel"  SG_ 848 SDM1_Checksum "";
BA_ "sigExplanation"  SG_ 848 SDM1_Checksum "ems,tcm,fdca,dvr,apa,bdcbcm,bsg,bms";
BA_ "GenMsgCycleTime" BO_ 323 10;
BA_ "VFrameFormat" BO_ 323 14;
BA_ "sigDespEng"  SG_ 323 EPS1_St_FailSts "EP必须发";
BA_ "sigSecLevel"  SG_ 323 EPS1_St_FailSts "";
BA_ "sigExplanation"  SG_ 323 EPS1_St_FailSts "ipc,tbox";
BA_ "GenSigStartValue" SG_ 323 EPS1_St_SteerMod 1;
BA_ "sigDespEng"  SG_ 323 EPS1_St_SteerMod "EP必须发";
BA_ "sigSecLevel"  SG_ 323 EPS1_St_SteerMod "";
BA_ "sigExplanation"  SG_ 323 EPS1_St_SteerMod "fdca,ipc,ehc,tbox";
BA_ "sigDespEng"  SG_ 323 EPS1_St_TrqSnsrSts "EP必须发";
BA_ "sigSecLevel"  SG_ 323 EPS1_St_TrqSnsrSts "";
BA_ "sigExplanation"  SG_ 323 EPS1_St_TrqSnsrSts "fdca,tbox";
BA_ "sigDespEng"  SG_ 323 EPS1_St_DrvStrInterDete "EP必须发";
BA_ "sigSecLevel"  SG_ 323 EPS1_St_DrvStrInterDete "";
BA_ "sigExplanation"  SG_ 323 EPS1_St_DrvStrInterDete "apa,tbox";
BA_ "GenSigStartValue" SG_ 323 EPS1_N_SteeringTorque 2047;
BA_ "sigSecLevel"  SG_ 323 EPS1_N_SteeringTorque "";
BA_ "sigExplanation"  SG_ 323 EPS1_N_SteeringTorque "ems,tbox,apa,FDCA";
BA_ "sigSecLevel"  SG_ 323 EPS1_F_DrvStrInterDete "";
BA_ "sigExplanation"  SG_ 323 EPS1_F_DrvStrInterDete "apa,tbox";
BA_ "sigDespEng"  SG_ 323 EPS1_St_Requestfeedback "EP必须发";
BA_ "sigSecLevel"  SG_ 323 EPS1_St_Requestfeedback "";
BA_ "sigExplanation"  SG_ 323 EPS1_St_Requestfeedback "apa,tbox";
BA_ "sigDespEng"  SG_ 323 EPS1_St_EPSControl "EP必须发";
BA_ "sigSecLevel"  SG_ 323 EPS1_St_EPSControl "";
BA_ "sigExplanation"  SG_ 323 EPS1_St_EPSControl "fdca,tbox";
BA_ "GenSigStartValue" SG_ 323 EPS1_N_ReqTorqueFeedack 1023;
BA_ "sigDespEng"  SG_ 323 EPS1_N_ReqTorqueFeedack "预留";
BA_ "sigSecLevel"  SG_ 323 EPS1_N_ReqTorqueFeedack "";
BA_ "sigExplanation"  SG_ 323 EPS1_N_ReqTorqueFeedack "fdca,tbox";
BA_ "sigDespEng"  SG_ 323 EPS1_F_ReqTorqueFeedack "预留";
BA_ "sigSecLevel"  SG_ 323 EPS1_F_ReqTorqueFeedack "";
BA_ "sigExplanation"  SG_ 323 EPS1_F_ReqTorqueFeedack "fdca,tbox";
BA_ "sigDespEng"  SG_ 323 EPS1_St_DSTEPSControl "EP必须发";
BA_ "sigSecLevel"  SG_ 323 EPS1_St_DSTEPSControl "";
BA_ "sigExplanation"  SG_ 323 EPS1_St_DSTEPSControl "wcbsesp,FDCA";
BA_ "sigDespEng"  SG_ 323 EPS1_F_DSTReqTorFeedackValid "EP必须发";
BA_ "sigSecLevel"  SG_ 323 EPS1_F_DSTReqTorFeedackValid "";
BA_ "sigExplanation"  SG_ 323 EPS1_F_DSTReqTorFeedackValid "wcbsesp,FDCA";
BA_ "GenSigStartValue" SG_ 323 EPS1_N_DSTReqTorFeedack 1023;
BA_ "sigDespEng"  SG_ 323 EPS1_N_DSTReqTorFeedack "EP必须发";
BA_ "sigSecLevel"  SG_ 323 EPS1_N_DSTReqTorFeedack "";
BA_ "sigExplanation"  SG_ 323 EPS1_N_DSTReqTorFeedack "wcbsesp,FDCA";
BA_ "sigDespEng"  SG_ 323 EPS1_RollingCounter "EP必须发";
BA_ "sigSecLevel"  SG_ 323 EPS1_RollingCounter "";
BA_ "sigExplanation"  SG_ 323 EPS1_RollingCounter "fdca,apa,tbox";
BA_ "sigDespEng"  SG_ 323 EPS1_Checksum "EP必须发";
BA_ "sigSecLevel"  SG_ 323 EPS1_Checksum "";
BA_ "sigExplanation"  SG_ 323 EPS1_Checksum "fdca,apa,tbox";
BA_ "sigSecLevel"  SG_ 323 EPS1_DrvInpTrqVld "";
BA_ "sigExplanation"  SG_ 323 EPS1_DrvInpTrqVld "apa，fdca";
BA_ "GenMsgCycleTime" BO_ 582 20;
BA_ "VFrameFormat" BO_ 582 14;
BA_ "sigSecLevel"  SG_ 582 FDCA4_N_ComAccUpperValue "";
BA_ "sigExplanation"  SG_ 582 FDCA4_N_ComAccUpperValue "wcbsesp";
BA_ "sigSecLevel"  SG_ 582 FDCA4_Cmd_BrakePreferred "";
BA_ "sigExplanation"  SG_ 582 FDCA4_Cmd_BrakePreferred "wcbsesp";
BA_ "sigSecLevel"  SG_ 582 FDCA4_N_ComAccLowerValue "";
BA_ "sigExplanation"  SG_ 582 FDCA4_N_ComAccLowerValue "wcbsesp";
BA_ "sigSecLevel"  SG_ 582 FDCA4_St_ReqDriveroff "";
BA_ "sigExplanation"  SG_ 582 FDCA4_St_ReqDriveroff "wcbsesp";
BA_ "sigSecLevel"  SG_ 582 FDCA4_N_LimitAccUpperValue "";
BA_ "sigExplanation"  SG_ 582 FDCA4_N_LimitAccUpperValue "wcbsesp";
BA_ "sigSecLevel"  SG_ 582 FDCA4_N_LimitAccLowerValue "";
BA_ "sigExplanation"  SG_ 582 FDCA4_N_LimitAccLowerValue "wcbsesp";
BA_ "sigSecLevel"  SG_ 582 FDCA4_St_ReqHBA "";
BA_ "sigExplanation"  SG_ 582 FDCA4_St_ReqHBA "wcbsesp";
BA_ "sigSecLevel"  SG_ 582 FDCA4_St_ReqPrefill "";
BA_ "sigExplanation"  SG_ 582 FDCA4_St_ReqPrefill "wcbsesp";
BA_ "sigSecLevel"  SG_ 582 FDCA4_Cmd_DecToStop "";
BA_ "sigExplanation"  SG_ 582 FDCA4_Cmd_DecToStop "wcbsesp";
BA_ "sigSecLevel"  SG_ 582 FDCA4_N_HBALevel "";
BA_ "sigExplanation"  SG_ 582 FDCA4_N_HBALevel "wcbsesp";
BA_ "GenSigStartValue" SG_ 582 FDCA4_ShutdownMod 3;
BA_ "sigDespEng"  SG_ 582 FDCA4_ShutdownMod "新增，同41";
BA_ "sigSecLevel"  SG_ 582 FDCA4_ShutdownMod "";
BA_ "sigExplanation"  SG_ 582 FDCA4_ShutdownMod "wcbsesp";
BA_ "sigDespEng"  SG_ 582 ADAS_FDCA4_St_AEBMode "新增，同41";
BA_ "sigSecLevel"  SG_ 582 ADAS_FDCA4_St_AEBMode "";
BA_ "sigExplanation"  SG_ 582 ADAS_FDCA4_St_AEBMode "wcbsesp,cdc,sdm,hud,apa";
BA_ "sigDespEng"  SG_ 582 FDCA4_St_ACCMode "L2.5";
BA_ "sigSecLevel"  SG_ 582 FDCA4_St_ACCMode "";
BA_ "sigExplanation"  SG_ 582 FDCA4_St_ACCMode "wcbsesp,sdm,pccu，pdcu";
BA_ "sigSecLevel"  SG_ 582 FDCA4_RollingCounter "";
BA_ "sigExplanation"  SG_ 582 FDCA4_RollingCounter "wcbsesp, apa";
BA_ "sigSecLevel"  SG_ 582 FDCA4_CheckSum "";
BA_ "sigExplanation"  SG_ 582 FDCA4_CheckSum "wcbsesp,apa";
BA_ "GenMsgCycleTime" BO_ 838 20;
BA_ "VFrameFormat" BO_ 838 14;
BA_ "sigSecLevel"  SG_ 838 FDCA3_N_AEBTardec "";
BA_ "sigExplanation"  SG_ 838 FDCA3_N_AEBTardec "wcbsesp";
BA_ "sigSecLevel"  SG_ 838 FDCA3_St_ACCMinimumBraking "";
BA_ "sigExplanation"  SG_ 838 FDCA3_St_ACCMinimumBraking "wcbsesp";
BA_ "sigSecLevel"  SG_ 838 FDCA3_St_AWBLevel "";
BA_ "sigExplanation"  SG_ 838 FDCA3_St_AWBLevel "wcbsesp";
BA_ "sigSecLevel"  SG_ 838 FDCA3_St_ReqAWB "";
BA_ "sigExplanation"  SG_ 838 FDCA3_St_ReqAWB "wcbsesp";
BA_ "sigSecLevel"  SG_ 838 FDCA3_St_ReqAEBDecCtrl "";
BA_ "sigExplanation"  SG_ 838 FDCA3_St_ReqAEBDecCtrl "wcbsesp";
BA_ "sigSecLevel"  SG_ 838 FDCA3_N_ACCTarAcc "";
BA_ "sigExplanation"  SG_ 838 FDCA3_N_ACCTarAcc "wcbsesp";
BA_ "sigDespEng"  SG_ 838 FDCA3_St_ACCMode "删除";
BA_ "sigSecLevel"  SG_ 838 FDCA3_St_ACCMode "";
BA_ "sigExplanation"  SG_ 838 FDCA3_St_ACCMode "wcbsesp,PDCU";
BA_ "sigDespEng"  SG_ 838 FDCA3_F_TorqueReq "L2.5";
BA_ "sigSecLevel"  SG_ 838 FDCA3_F_TorqueReq "";
BA_ "sigExplanation"  SG_ 838 FDCA3_F_TorqueReq "eps";
BA_ "sigDespEng"  SG_ 838 FDCA3_N_TorqueReq "L2.5";
BA_ "sigSecLevel"  SG_ 838 FDCA3_N_TorqueReq "";
BA_ "sigExplanation"  SG_ 838 FDCA3_N_TorqueReq "eps";
BA_ "sigSecLevel"  SG_ 838 FDCA3_RollingCounter "";
BA_ "sigExplanation"  SG_ 838 FDCA3_RollingCounter "wcbsesp,eps";
BA_ "sigSecLevel"  SG_ 838 FDCA3_Checksum "";
BA_ "sigExplanation"  SG_ 838 FDCA3_Checksum "wcbsesp,eps";
BA_ "GenMsgCycleTime" BO_ 816 100;
BA_ "VFrameFormat" BO_ 816 14;
BA_ "sigSecLevel"  SG_ 816 CSS1_F_AVMSw "";
BA_ "sigExplanation"  SG_ 816 CSS1_F_AVMSw "apa";
BA_ "sigDespEng"  SG_ 816 CSS1_Sw_AVM "AVM开关";
BA_ "sigSecLevel"  SG_ 816 CSS1_Sw_AVM "";
BA_ "sigExplanation"  SG_ 816 CSS1_Sw_AVM "apa";
BA_ "GenMsgSendType" BO_ 1314 1;
BA_ "GenMsgCycleTimeFast" BO_ 1314 20;
BA_ "GenMsgNrOfRepetition" BO_ 1314 3;
BA_ "VFrameFormat" BO_ 1314 14;
BA_ "GenSigSendType" SG_ 1314 EHC1_Set_FPAS 1;
BA_ "sigSecLevel"  SG_ 1314 EHC1_Set_FPAS "";
BA_ "sigExplanation"  SG_ 1314 EHC1_Set_FPAS "pas,apa";
BA_ "GenSigSendType" SG_ 1314 EHC1_Set_LanguageSetting 1;
BA_ "sigDespEng"  SG_ 1314 EHC1_Set_LanguageSetting "L2.5";
BA_ "sigSecLevel"  SG_ 1314 EHC1_Set_LanguageSetting "";
BA_ "sigExplanation"  SG_ 1314 EHC1_Set_LanguageSetting "hud,ipc,apa";
BA_ "GenSigSendType" SG_ 1314 EHC1_Set_ThemeMode 1;
BA_ "sigDespEng"  SG_ 1314 EHC1_Set_ThemeMode "L2.5";
BA_ "sigSecLevel"  SG_ 1314 EHC1_Set_ThemeMode "";
BA_ "sigExplanation"  SG_ 1314 EHC1_Set_ThemeMode "ipc,apa，ssbs";
BA_ "GenMsgSendType" BO_ 1315 1;
BA_ "VFrameFormat" BO_ 1315 14;
BA_ "GenSigSendType" SG_ 1315 EHC3_Set_FCWOption 1;
BA_ "sigDespEng"  SG_ 1315 EHC3_Set_FCWOption "L2.5";
BA_ "sigSecLevel"  SG_ 1315 EHC3_Set_FCWOption "";
BA_ "sigExplanation"  SG_ 1315 EHC3_Set_FCWOption "fdca";
BA_ "GenSigSendType" SG_ 1315 EHC3_Set_LKASen 1;
BA_ "sigDespEng"  SG_ 1315 EHC3_Set_LKASen "L2.5";
BA_ "sigSecLevel"  SG_ 1315 EHC3_Set_LKASen "";
BA_ "sigExplanation"  SG_ 1315 EHC3_Set_LKASen "fdca";
BA_ "GenSigSendType" SG_ 1315 EHC3_Set_AEB 1;
BA_ "GenSigStartValue" SG_ 1315 EHC3_Set_AEB 2;
BA_ "sigDespEng"  SG_ 1315 EHC3_Set_AEB "L2.5";
BA_ "sigSecLevel"  SG_ 1315 EHC3_Set_AEB "";
BA_ "sigExplanation"  SG_ 1315 EHC3_Set_AEB "fdca";
BA_ "GenSigSendType" SG_ 1315 EHC3_Set_TSR 1;
BA_ "sigDespEng"  SG_ 1315 EHC3_Set_TSR "L2.5，修订coding值与B41一致，该信号较B60V有变动";
BA_ "sigSecLevel"  SG_ 1315 EHC3_Set_TSR "";
BA_ "sigExplanation"  SG_ 1315 EHC3_Set_TSR "fdca";
BA_ "GenSigSendType" SG_ 1315 EHC3_Set_TJA_ICA_ACC 1;
BA_ "sigDespEng"  SG_ 1315 EHC3_Set_TJA_ICA_ACC "L2.5";
BA_ "sigSecLevel"  SG_ 1315 EHC3_Set_TJA_ICA_ACC "";
BA_ "sigExplanation"  SG_ 1315 EHC3_Set_TJA_ICA_ACC "fdca";
BA_ "GenSigSendType" SG_ 1315 EHC3_Set_LDWSen 1;
BA_ "sigDespEng"  SG_ 1315 EHC3_Set_LDWSen "L2.5";
BA_ "sigSecLevel"  SG_ 1315 EHC3_Set_LDWSen "";
BA_ "sigExplanation"  SG_ 1315 EHC3_Set_LDWSen "fdca";
BA_ "GenMsgCycleTime" BO_ 1319 1000;
BA_ "VFrameFormat" BO_ 1319 14;
BA_ "sigDespEng"  SG_ 1319 EHC6_N_Year "L2.5";
BA_ "sigSecLevel"  SG_ 1319 EHC6_N_Year "";
BA_ "sigExplanation"  SG_ 1319 EHC6_N_Year "tcm,sdm,egsm,fdca,eps,dvr,ipc,apa,ssbs,bsg,PWC,IDS，cmrr";
BA_ "sigDespEng"  SG_ 1319 EHC6_N_Month "L2.5";
BA_ "sigSecLevel"  SG_ 1319 EHC6_N_Month "";
BA_ "sigExplanation"  SG_ 1319 EHC6_N_Month "tcm,sdm,egsm,fdca,eps,dvr,ipc,apa,ssbs,bsg,PWC,IDS，cmrr";
BA_ "sigDespEng"  SG_ 1319 EHC6_N_Day "L2.5";
BA_ "sigSecLevel"  SG_ 1319 EHC6_N_Day "";
BA_ "sigExplanation"  SG_ 1319 EHC6_N_Day "tcm,sdm,egsm,fdca,eps,dvr,ipc,apa,ssbs,bsg,PWC,IDS，cmrr";
BA_ "sigDespEng"  SG_ 1319 EHC6_N_Hour "L2.5";
BA_ "sigSecLevel"  SG_ 1319 EHC6_N_Hour "";
BA_ "sigExplanation"  SG_ 1319 EHC6_N_Hour "tcm,sdm,egsm,fdca,eps,dvr,ipc,apa,ssbs,bsg,PWC,IDS，cmrr";
BA_ "sigDespEng"  SG_ 1319 EHC6_N_Minute "L2.5";
BA_ "sigSecLevel"  SG_ 1319 EHC6_N_Minute "";
BA_ "sigExplanation"  SG_ 1319 EHC6_N_Minute "tcm,sdm,egsm,fdca,eps,dvr,ipc,apa,ssbs,bsg,PWC,IDS，cmrr";
BA_ "sigDespEng"  SG_ 1319 EHC6_N_Second "L2.5";
BA_ "sigSecLevel"  SG_ 1319 EHC6_N_Second "";
BA_ "sigExplanation"  SG_ 1319 EHC6_N_Second "tcm,sdm,egsm,fdca,eps,dvr,ipc,apa,ssbs,bsg,PWC,IDS，cmrr";
BA_ "sigDespEng"  SG_ 1319 EHC6_St_Navigation "L2.5";
BA_ "sigSecLevel"  SG_ 1319 EHC6_St_Navigation "";
BA_ "sigExplanation"  SG_ 1319 EHC6_St_Navigation "ipc，ssbs,FDCA,APA";
BA_ "sigSecLevel"  SG_ 1319 EHC6_Set_LanguageSetting "";
BA_ "sigExplanation"  SG_ 1319 EHC6_Set_LanguageSetting "hud,ipc,apa";
BA_ "sigDespEng"  SG_ 1319 EHC6_TiMod "41新增";
BA_ "sigSecLevel"  SG_ 1319 EHC6_TiMod "";
BA_ "sigExplanation"  SG_ 1319 EHC6_TiMod "fdca";
BA_ "sigDespEng"  SG_ 1319 EHC6_DateWeek "41新增";
BA_ "sigSecLevel"  SG_ 1319 EHC6_DateWeek "";
BA_ "sigExplanation"  SG_ 1319 EHC6_DateWeek "fdca";
BA_ "GenMsgCycleTime" BO_ 1766 50;
BA_ "VFrameFormat" BO_ 1766 14;
BA_ "sigSecLevel"  SG_ 1766 EHC11_St_TrailerFcnActive "";
BA_ "sigExplanation"  SG_ 1766 EHC11_St_TrailerFcnActive "APA, FDCA, CMRR, ADAS,TIM";
BA_ "sigSecLevel"  SG_ 1766 IccSentiModReq "";
BA_ "sigConfig"  SG_ 1766 IccSentiModReq "哨兵";
BA_ "sigSecLevel"  SG_ 1766 CDC_Cmd_CampGuardee "";
BA_ "sigConfig"  SG_ 1766 CDC_Cmd_CampGuardee "露营卫士";
BA_ "sigExplanation"  SG_ 1766 CDC_Cmd_CampGuardee "APA,DVR";
BA_ "sigSecLevel"  SG_ 1766 IccSentiModSts "";
BA_ "sigConfig"  SG_ 1766 IccSentiModSts "哨兵";
BA_ "GenMsgCycleTime" BO_ 1568 100;
BA_ "VFrameFormat" BO_ 1568 14;
BA_ "sigDespEng"  SG_ 1568 IPC1_F_OdometerParameter "L2.5";
BA_ "sigSecLevel"  SG_ 1568 IPC1_F_OdometerParameter "";
BA_ "sigExplanation"  SG_ 1568 IPC1_F_OdometerParameter "ems,tcm,wcbsepb,egsm,eds,ehc,apa,bdcbcm,bsg,bms,tbox";
BA_ "sigDespEng"  SG_ 1568 IPC1_St_QDashACCFail "ACC信息显示错误";
BA_ "sigSecLevel"  SG_ 1568 IPC1_St_QDashACCFail "";
BA_ "sigExplanation"  SG_ 1568 IPC1_St_QDashACCFail "fdca";
BA_ "sigDespEng"  SG_ 1568 IPC1_St_DISFail "显示屏显示错误";
BA_ "sigSecLevel"  SG_ 1568 IPC1_St_DISFail "";
BA_ "sigExplanation"  SG_ 1568 IPC1_St_DISFail "fdca";
BA_ "sigDespEng"  SG_ 1568 IPC1_N_OdoMeter "L2.5,里程";
BA_ "sigSecLevel"  SG_ 1568 IPC1_N_OdoMeter "";
BA_ "sigExplanation"  SG_ 1568 IPC1_N_OdoMeter "ems,tcm,wcbsepb,egsm,eds,ehc,apa,bdcbcm,bsg,bms,tbox,fdca,eps";
BA_ "sigDespEng"  SG_ 1568 ICC_PrivacyAgreementSwt "设置整车隐私协议开关";
BA_ "sigSecLevel"  SG_ 1568 ICC_PrivacyAgreementSwt "";
BA_ "sigConfig"  SG_ 1568 ICC_PrivacyAgreementSwt "B81VS";
BA_ "sigExplanation"  SG_ 1568 ICC_PrivacyAgreementSwt "adc，TBOX";
BA_ "GenMsgCycleTime" BO_ 656 20;
BA_ "VFrameFormat" BO_ 656 14;
BA_ "GenSigStartValue" SG_ 656 APA1_N_TargetSteeringAng 7800;
BA_ "sigSecLevel"  SG_ 656 APA1_N_TargetSteeringAng "";
BA_ "sigConfig"  SG_ 656 APA1_N_TargetSteeringAng "tsp";
BA_ "sigExplanation"  SG_ 656 APA1_N_TargetSteeringAng "eps";
BA_ "sigSecLevel"  SG_ 656 APA1_F_TargetSteeringAng "";
BA_ "sigExplanation"  SG_ 656 APA1_F_TargetSteeringAng "eps";
BA_ "sigSecLevel"  SG_ 656 APA1_St_ControlRequest "";
BA_ "sigExplanation"  SG_ 656 APA1_St_ControlRequest "eps";
BA_ "sigSecLevel"  SG_ 656 APA1_St_TarGearReq "";
BA_ "sigConfig"  SG_ 656 APA1_St_TarGearReq "tsp";
BA_ "sigExplanation"  SG_ 656 APA1_St_TarGearReq "wcbsesp";
BA_ "sigSecLevel"  SG_ 656 APA1_St_BrakeMode "";
BA_ "sigConfig"  SG_ 656 APA1_St_BrakeMode "tsp";
BA_ "sigExplanation"  SG_ 656 APA1_St_BrakeMode "wcbsesp";
BA_ "sigSecLevel"  SG_ 656 APA1_St_BrakeFunctionMode "";
BA_ "sigConfig"  SG_ 656 APA1_St_BrakeFunctionMode "tsp";
BA_ "sigExplanation"  SG_ 656 APA1_St_BrakeFunctionMode "wcbsesp";
BA_ "sigSecLevel"  SG_ 656 APA1_N_ESCStopDi "";
BA_ "sigConfig"  SG_ 656 APA1_N_ESCStopDi "tsp";
BA_ "sigExplanation"  SG_ 656 APA1_N_ESCStopDi "wcbsesp，ehc";
BA_ "sigSecLevel"  SG_ 656 APA1_N_ESCSpeedLi "";
BA_ "sigConfig"  SG_ 656 APA1_N_ESCSpeedLi "tsp";
BA_ "sigExplanation"  SG_ 656 APA1_N_ESCSpeedLi "wcbsesp";
BA_ "sigSecLevel"  SG_ 656 APA1_St_FBrakeMode "";
BA_ "sigConfig"  SG_ 656 APA1_St_FBrakeMode "tsp";
BA_ "sigExplanation"  SG_ 656 APA1_St_FBrakeMode "wcbsesp";
BA_ "sigSecLevel"  SG_ 656 APA1_RollingCounter "";
BA_ "sigExplanation"  SG_ 656 APA1_RollingCounter "wcbsesp,eps";
BA_ "sigSecLevel"  SG_ 656 APA1_Checksum "";
BA_ "sigExplanation"  SG_ 656 APA1_Checksum "wcbsesp,eps";
BA_ "GenMsgCycleTime" BO_ 657 20;
BA_ "VFrameFormat" BO_ 657 14;
BA_ "sigDespEng"  SG_ 657 APA2_St_AutoParkingIn "预留";
BA_ "sigSecLevel"  SG_ 657 APA2_St_AutoParkingIn "";
BA_ "sigExplanation"  SG_ 657 APA2_St_AutoParkingIn "ehc";
BA_ "sigDespEng"  SG_ 657 APA2_St_AutoParkingOut "预留";
BA_ "sigSecLevel"  SG_ 657 APA2_St_AutoParkingOut "";
BA_ "sigExplanation"  SG_ 657 APA2_St_AutoParkingOut "ehc";
BA_ "sigDespEng"  SG_ 657 APA2_St_UserSlot "预留";
BA_ "sigSecLevel"  SG_ 657 APA2_St_UserSlot "";
BA_ "sigExplanation"  SG_ 657 APA2_St_UserSlot "ehc";
BA_ "sigDespEng"  SG_ 657 APA2_St_Set "预留";
BA_ "sigSecLevel"  SG_ 657 APA2_St_Set "";
BA_ "sigExplanation"  SG_ 657 APA2_St_Set "ehc";
BA_ "sigDespEng"  SG_ 657 APA2_St_ParkOutDirSet "预留";
BA_ "sigSecLevel"  SG_ 657 APA2_St_ParkOutDirSet "";
BA_ "sigExplanation"  SG_ 657 APA2_St_ParkOutDirSet "tbox,ehc";
BA_ "sigDespEng"  SG_ 657 APA2_RPA_RpaSts "维持，需要发出";
BA_ "sigSecLevel"  SG_ 657 APA2_RPA_RpaSts "";
BA_ "sigExplanation"  SG_ 657 APA2_RPA_RpaSts "bdcpeps,tbox,ehc";
BA_ "sigDespEng"  SG_ 657 APA2_St_Preference "预留";
BA_ "sigSecLevel"  SG_ 657 APA2_St_Preference "";
BA_ "sigExplanation"  SG_ 657 APA2_St_Preference "ehc";
BA_ "sigDespEng"  SG_ 657 APA2_St_ParkingInMode "维持，需要发出";
BA_ "sigSecLevel"  SG_ 657 APA2_St_ParkingInMode "";
BA_ "sigExplanation"  SG_ 657 APA2_St_ParkingInMode "ehc,wcbsesp,bdcbcm";
BA_ "sigDespEng"  SG_ 657 APA2_St_ParkingInPreCon "预留";
BA_ "sigSecLevel"  SG_ 657 APA2_St_ParkingInPreCon "";
BA_ "sigExplanation"  SG_ 657 APA2_St_ParkingInPreCon "ehc";
BA_ "sigDespEng"  SG_ 657 APA2_St_APAStatus "维持，需要发出";
BA_ "sigSecLevel"  SG_ 657 APA2_St_APAStatus "";
BA_ "sigExplanation"  SG_ 657 APA2_St_APAStatus "ehc,bdcbcm,tbox,FDCA";
BA_ "sigDespEng"  SG_ 657 APA2_St_ParkingOutDirection "预留";
BA_ "sigSecLevel"  SG_ 657 APA2_St_ParkingOutDirection "";
BA_ "sigExplanation"  SG_ 657 APA2_St_ParkingOutDirection "ehc";
BA_ "sigDespEng"  SG_ 657 APA2_St_SelectedParkOutDire "预留";
BA_ "sigSecLevel"  SG_ 657 APA2_St_SelectedParkOutDire "";
BA_ "sigExplanation"  SG_ 657 APA2_St_SelectedParkOutDire "ehc";
BA_ "sigDespEng"  SG_ 657 APA2_St_DirHalfLeAvl "预留";
BA_ "sigSecLevel"  SG_ 657 APA2_St_DirHalfLeAvl "";
BA_ "sigExplanation"  SG_ 657 APA2_St_DirHalfLeAvl "tbox,ehc";
BA_ "sigDespEng"  SG_ 657 APA2_St_DirHalfRiAvl "预留";
BA_ "sigSecLevel"  SG_ 657 APA2_St_DirHalfRiAvl "";
BA_ "sigExplanation"  SG_ 657 APA2_St_DirHalfRiAvl "tbox,ehc";
BA_ "sigDespEng"  SG_ 657 APA2_St_DirHozlFwAvl "预留";
BA_ "sigSecLevel"  SG_ 657 APA2_St_DirHozlFwAvl "";
BA_ "sigExplanation"  SG_ 657 APA2_St_DirHozlFwAvl "tbox,ehc";
BA_ "sigDespEng"  SG_ 657 APA2_St_DirHozlBwAvl "预留";
BA_ "sigSecLevel"  SG_ 657 APA2_St_DirHozlBwAvl "";
BA_ "sigExplanation"  SG_ 657 APA2_St_DirHozlBwAvl "tbox,ehc";
BA_ "sigDespEng"  SG_ 657 APA2_St_DirVertHdLeAvl "预留";
BA_ "sigSecLevel"  SG_ 657 APA2_St_DirVertHdLeAvl "";
BA_ "sigExplanation"  SG_ 657 APA2_St_DirVertHdLeAvl "tbox,ehc";
BA_ "sigDespEng"  SG_ 657 APA2_St_DirVertHdRiAvl "预留";
BA_ "sigSecLevel"  SG_ 657 APA2_St_DirVertHdRiAvl "";
BA_ "sigExplanation"  SG_ 657 APA2_St_DirVertHdRiAvl "tbox,ehc";
BA_ "sigDespEng"  SG_ 657 APA2_St_DirVertTrLeAvl "预留";
BA_ "sigSecLevel"  SG_ 657 APA2_St_DirVertTrLeAvl "";
BA_ "sigExplanation"  SG_ 657 APA2_St_DirVertTrLeAvl "tbox,ehc";
BA_ "sigDespEng"  SG_ 657 APA2_St_DirVertTrRiAvl "预留";
BA_ "sigSecLevel"  SG_ 657 APA2_St_DirVertTrRiAvl "";
BA_ "sigExplanation"  SG_ 657 APA2_St_DirVertTrRiAvl "tbox,ehc";
BA_ "sigDespEng"  SG_ 657 APA2_St_Request "预留";
BA_ "sigSecLevel"  SG_ 657 APA2_St_Request "";
BA_ "sigExplanation"  SG_ 657 APA2_St_Request "ehc";
BA_ "sigDespEng"  SG_ 657 APA2_RollingCounter "维持，需要发出";
BA_ "sigSecLevel"  SG_ 657 APA2_RollingCounter "";
BA_ "sigExplanation"  SG_ 657 APA2_RollingCounter "wcbsesp,ehc,tbox";
BA_ "sigDespEng"  SG_ 657 APA2_Checksum "维持，需要发出";
BA_ "sigSecLevel"  SG_ 657 APA2_Checksum "";
BA_ "sigExplanation"  SG_ 657 APA2_Checksum "wcbsesp,ehc,tbox";
BA_ "GenMsgCycleTime" BO_ 1427 500;
BA_ "VFrameFormat" BO_ 1427 14;
BA_ "sigSecLevel"  SG_ 1427 APA3_St_Update "";
BA_ "sigExplanation"  SG_ 1427 APA3_St_Update "ehc";
BA_ "sigSecLevel"  SG_ 1427 APA3_St_UpdateType "";
BA_ "sigExplanation"  SG_ 1427 APA3_St_UpdateType "ehc";
BA_ "sigSecLevel"  SG_ 1427 APA3_N_SoftVersion "";
BA_ "sigExplanation"  SG_ 1427 APA3_N_SoftVersion "ehc";
BA_ "sigSecLevel"  SG_ 1427 APA3_N_PacketSoftVersion "";
BA_ "sigExplanation"  SG_ 1427 APA3_N_PacketSoftVersion "ehc";
BA_ "GenMsgCycleTime" BO_ 917 50;
BA_ "VFrameFormat" BO_ 917 14;
BA_ "sigDespEng"  SG_ 917 AVM2_St_WormModeView "维持";
BA_ "sigSecLevel"  SG_ 917 AVM2_St_WormModeView "";
BA_ "sigExplanation"  SG_ 917 AVM2_St_WormModeView "cdc";
BA_ "sigDespEng"  SG_ 917 AVM2_St_RockModeView "维持";
BA_ "sigSecLevel"  SG_ 917 AVM2_St_RockModeView "";
BA_ "sigExplanation"  SG_ 917 AVM2_St_RockModeView "cdc";
BA_ "sigDespEng"  SG_ 917 AVM2_St_CurrViewType "维持";
BA_ "sigSecLevel"  SG_ 917 AVM2_St_CurrViewType "";
BA_ "sigExplanation"  SG_ 917 AVM2_St_CurrViewType "cdc";
BA_ "sigDespEng"  SG_ 917 AVM2_St_Mode "41没用";
BA_ "sigSecLevel"  SG_ 917 AVM2_St_Mode "";
BA_ "sigExplanation"  SG_ 917 AVM2_St_Mode "ehc";
BA_ "sigDespEng"  SG_ 917 AVM2_St_PerspectiveChassis "维持";
BA_ "sigSecLevel"  SG_ 917 AVM2_St_PerspectiveChassis "";
BA_ "sigExplanation"  SG_ 917 AVM2_St_PerspectiveChassis "cdc";
BA_ "sigDespEng"  SG_ 917 AVM2_St_QuitAvmEnable "41没用";
BA_ "sigSecLevel"  SG_ 917 AVM2_St_QuitAvmEnable "";
BA_ "sigExplanation"  SG_ 917 AVM2_St_QuitAvmEnable "ehc";
BA_ "sigDespEng"  SG_ 917 AVM2_St_ModeSwitchEnable "41没用";
BA_ "sigSecLevel"  SG_ 917 AVM2_St_ModeSwitchEnable "";
BA_ "sigExplanation"  SG_ 917 AVM2_St_ModeSwitchEnable "ehc";
BA_ "sigDespEng"  SG_ 917 AVM2_St_PerspectiveEnable "维持";
BA_ "sigSecLevel"  SG_ 917 AVM2_St_PerspectiveEnable "";
BA_ "sigExplanation"  SG_ 917 AVM2_St_PerspectiveEnable "cdc";
BA_ "sigDespEng"  SG_ 917 AVM2_St_MoreViewEnable "41没用";
BA_ "sigSecLevel"  SG_ 917 AVM2_St_MoreViewEnable "";
BA_ "sigExplanation"  SG_ 917 AVM2_St_MoreViewEnable "ehc";
BA_ "sigDespEng"  SG_ 917 AVM2_St_SettingEnable "维持";
BA_ "sigSecLevel"  SG_ 917 AVM2_St_SettingEnable "";
BA_ "sigExplanation"  SG_ 917 AVM2_St_SettingEnable "cdc";
BA_ "sigDespEng"  SG_ 917 AVM2_St_WormEnable "维持";
BA_ "sigSecLevel"  SG_ 917 AVM2_St_WormEnable "";
BA_ "sigExplanation"  SG_ 917 AVM2_St_WormEnable "cdc";
BA_ "sigDespEng"  SG_ 917 AVM2_St_RockEnable "维持";
BA_ "sigSecLevel"  SG_ 917 AVM2_St_RockEnable "";
BA_ "sigExplanation"  SG_ 917 AVM2_St_RockEnable "cdc";
BA_ "sigDespEng"  SG_ 917 AVM2_St_Reseved "41没用";
BA_ "sigSecLevel"  SG_ 917 AVM2_St_Reseved "";
BA_ "sigExplanation"  SG_ 917 AVM2_St_Reseved "none";
BA_ "sigDespEng"  SG_ 917 AVM2_Set_TireTrajectory "41没用";
BA_ "sigSecLevel"  SG_ 917 AVM2_Set_TireTrajectory "";
BA_ "sigExplanation"  SG_ 917 AVM2_Set_TireTrajectory "ehc";
BA_ "sigDespEng"  SG_ 917 AVM2_Set_CarTrajectory "41没用";
BA_ "sigSecLevel"  SG_ 917 AVM2_Set_CarTrajectory "";
BA_ "sigExplanation"  SG_ 917 AVM2_Set_CarTrajectory "ehc";
BA_ "sigDespEng"  SG_ 917 AVM2_Set_2DRadar "41没用";
BA_ "sigSecLevel"  SG_ 917 AVM2_Set_2DRadar "";
BA_ "sigExplanation"  SG_ 917 AVM2_Set_2DRadar "ehc";
BA_ "sigDespEng"  SG_ 917 AVM2_Set_3DRadar "41没用";
BA_ "sigSecLevel"  SG_ 917 AVM2_Set_3DRadar "";
BA_ "sigExplanation"  SG_ 917 AVM2_Set_3DRadar "ehc";
BA_ "sigDespEng"  SG_ 917 AVM2_Set_TurnTriggerView "41没用";
BA_ "sigSecLevel"  SG_ 917 AVM2_Set_TurnTriggerView "";
BA_ "sigExplanation"  SG_ 917 AVM2_Set_TurnTriggerView "ehc";
BA_ "sigDespEng"  SG_ 917 AVM2_Set_RadarTriggerView "41没用";
BA_ "sigSecLevel"  SG_ 917 AVM2_Set_RadarTriggerView "";
BA_ "sigExplanation"  SG_ 917 AVM2_Set_RadarTriggerView "ehc";
BA_ "sigDespEng"  SG_ 917 AVM2_Error_Controller "41没用";
BA_ "sigSecLevel"  SG_ 917 AVM2_Error_Controller "";
BA_ "sigExplanation"  SG_ 917 AVM2_Error_Controller "ehc";
BA_ "sigDespEng"  SG_ 917 AVM2_Error_ViewOutput "41没用";
BA_ "sigSecLevel"  SG_ 917 AVM2_Error_ViewOutput "";
BA_ "sigExplanation"  SG_ 917 AVM2_Error_ViewOutput "ehc";
BA_ "sigDespEng"  SG_ 917 AvmVehLctSts "原位置信号：AVM2_St_Transparency";
BA_ "sigSecLevel"  SG_ 917 AvmVehLctSts "";
BA_ "sigExplanation"  SG_ 917 AvmVehLctSts "cdc";
BA_ "sigDespEng"  SG_ 917 AVM2_Set_CarColor "维持";
BA_ "sigSecLevel"  SG_ 917 AVM2_Set_CarColor "";
BA_ "sigExplanation"  SG_ 917 AVM2_Set_CarColor "cdc";
BA_ "sigDespEng"  SG_ 917 AVM2_St_MoreViews "41没用";
BA_ "sigSecLevel"  SG_ 917 AVM2_St_MoreViews "";
BA_ "sigExplanation"  SG_ 917 AVM2_St_MoreViews "ehc";
BA_ "sigDespEng"  SG_ 917 AVM2_St_CSSLight "维持";
BA_ "sigSecLevel"  SG_ 917 AVM2_St_CSSLight "";
BA_ "sigExplanation"  SG_ 917 AVM2_St_CSSLight "css";
BA_ "sigDespEng"  SG_ 917 AVM2_St_RestoreSetting "41没用";
BA_ "sigSecLevel"  SG_ 917 AVM2_St_RestoreSetting "";
BA_ "sigExplanation"  SG_ 917 AVM2_St_RestoreSetting "ehc";
BA_ "sigDespEng"  SG_ 917 AVM2_St_PromptMessage "41没用";
BA_ "sigSecLevel"  SG_ 917 AVM2_St_PromptMessage "";
BA_ "sigExplanation"  SG_ 917 AVM2_St_PromptMessage "ehc";
BA_ "sigDespEng"  SG_ 917 AVM2_St_PromptTimeOut "41没用";
BA_ "sigSecLevel"  SG_ 917 AVM2_St_PromptTimeOut "";
BA_ "sigExplanation"  SG_ 917 AVM2_St_PromptTimeOut "ehc";
BA_ "sigDespEng"  SG_ 917 FrntcamFaild "41新增";
BA_ "sigSecLevel"  SG_ 917 FrntcamFaild "";
BA_ "sigExplanation"  SG_ 917 FrntcamFaild "cdc";
BA_ "sigDespEng"  SG_ 917 RecamFaild "41新增";
BA_ "sigSecLevel"  SG_ 917 RecamFaild "";
BA_ "sigExplanation"  SG_ 917 RecamFaild "cdc";
BA_ "sigDespEng"  SG_ 917 LecamFaild "41新增";
BA_ "sigSecLevel"  SG_ 917 LecamFaild "";
BA_ "sigExplanation"  SG_ 917 LecamFaild "cdc";
BA_ "sigDespEng"  SG_ 917 RicamFaild "41新增";
BA_ "sigSecLevel"  SG_ 917 RicamFaild "";
BA_ "sigExplanation"  SG_ 917 RicamFaild "cdc";
BA_ "sigDespEng"  SG_ 917 AvmCtrlrFaild "41新增";
BA_ "sigSecLevel"  SG_ 917 AvmCtrlrFaild "";
BA_ "sigExplanation"  SG_ 917 AvmCtrlrFaild "cdc";
BA_ "sigDespEng"  SG_ 917 AvmSts "41新增";
BA_ "sigSecLevel"  SG_ 917 AvmSts "";
BA_ "sigExplanation"  SG_ 917 AvmSts "cdc";
BA_ "GenMsgCycleTime" BO_ 1392 50;
BA_ "VFrameFormat" BO_ 1392 14;
BA_ "sigSecLevel"  SG_ 1392 CAPE1_F_PowerMode "";
BA_ "sigExplanation"  SG_ 1392 CAPE1_F_PowerMode "ems,tcm,wcbsesp,wcbsepb,egsm,tccu,css,fdca,alc,orim,amp,wddc,swfb,cmwr,pas,dvr,ehc,apa,avm,svm,ssbs,escl,dsm,fhs,ac,rhs,bdcpeps,bdcbcm,bdctpms,bsg,tbox,swh";
BA_ "sigSecLevel"  SG_ 1392 CAPE1_St_PowerMode "";
BA_ "sigExplanation"  SG_ 1392 CAPE1_St_PowerMode "ems,tcm,wcbsesp,wcbsepb,egsm,tccu,css,fdca,alc,orim,amp,wddc,swfb,cmwr,pas,dvr,ehc,apa,avm,svm,ssbs,escl,dsm,fhs,ac,rhs,bdcbcm,bdctpms,bsg,tbox，swh";
BA_ "GenSigSendType" SG_ 1392 CAPE1_St_PepsRemPwrMod 1;
BA_ "sigSecLevel"  SG_ 1392 CAPE1_St_PepsRemPwrMod "";
BA_ "sigExplanation"  SG_ 1392 CAPE1_St_PepsRemPwrMod "APA";
BA_ "sigSecLevel"  SG_ 1392 CAPE1_RollingCounter "";
BA_ "sigExplanation"  SG_ 1392 CAPE1_RollingCounter "ems,tcm,egsm,amp";
BA_ "sigSecLevel"  SG_ 1392 CAPE1_CheckSum "";
BA_ "sigExplanation"  SG_ 1392 CAPE1_CheckSum "ems,tcm,egsm,amp";
BA_ "GenMsgCycleTime" BO_ 1184 50;
BA_ "VFrameFormat" BO_ 1184 14;
BA_ "sigSecLevel"  SG_ 1184 BCM1_Cmd_PositionLamp "";
BA_ "sigExplanation"  SG_ 1184 BCM1_Cmd_PositionLamp "egsm,css,alc,swfb,dvr,ipc,ehc,apa,ssbs,dculf,dcurf,fhs,rhs,tbox";
BA_ "sigSecLevel"  SG_ 1184 BCM1_Sw_TurnLeftLamp "";
BA_ "sigExplanation"  SG_ 1184 BCM1_Sw_TurnLeftLamp "fdca，sdm";
BA_ "sigSecLevel"  SG_ 1184 BCM1_Sw_TurnRightLamp "";
BA_ "sigExplanation"  SG_ 1184 BCM1_Sw_TurnRightLamp "fdca，sdm";
BA_ "sigSecLevel"  SG_ 1184 BCM1_St_HazzardFlash "";
BA_ "sigExplanation"  SG_ 1184 BCM1_St_HazzardFlash "fdca，sdm,tbox";
BA_ "sigSecLevel"  SG_ 1184 BCM1_St_HighBeam "";
BA_ "sigExplanation"  SG_ 1184 BCM1_St_HighBeam "fdca,ipc,apa,tbox，hud";
BA_ "sigDespEng"  SG_ 1184 BCM1_Cmd_LeftTurnLamp "闪烁";
BA_ "sigSecLevel"  SG_ 1184 BCM1_Cmd_LeftTurnLamp "";
BA_ "sigExplanation"  SG_ 1184 BCM1_Cmd_LeftTurnLamp "fdca,cmwr,dvr,ipc,ehc,apa,dculf,tbox";
BA_ "sigDespEng"  SG_ 1184 BCM1_St_LeftTurnLamp "闪烁";
BA_ "sigSecLevel"  SG_ 1184 BCM1_St_LeftTurnLamp "";
BA_ "sigExplanation"  SG_ 1184 BCM1_St_LeftTurnLamp "fdca,ipc,apa,tbox";
BA_ "sigDespEng"  SG_ 1184 BCM1_Cmd_RightTurnLamp "闪烁";
BA_ "sigSecLevel"  SG_ 1184 BCM1_Cmd_RightTurnLamp "";
BA_ "sigExplanation"  SG_ 1184 BCM1_Cmd_RightTurnLamp "fdca,cmwr,dvr,ipc,apa,dcurf,tbox";
BA_ "sigDespEng"  SG_ 1184 BCM1_St_RightTurnLamp "闪烁";
BA_ "sigSecLevel"  SG_ 1184 BCM1_St_RightTurnLamp "";
BA_ "sigExplanation"  SG_ 1184 BCM1_St_RightTurnLamp "fdca,ipc,ehc,apa,tbox";
BA_ "sigSecLevel"  SG_ 1184 BCM1_St_PositionLamp "";
BA_ "sigExplanation"  SG_ 1184 BCM1_St_PositionLamp "ipc,apa,ssbs,tbox";
BA_ "sigSecLevel"  SG_ 1184 BCM1_St_AntiThelfIndication "";
BA_ "sigExplanation"  SG_ 1184 BCM1_St_AntiThelfIndication "ssbs,dsm,bdcpeps,tbox，cmwr,ehc,FDCA";
BA_ "sigSecLevel"  SG_ 1184 BCM1_St_LFDoorLock "";
BA_ "sigExplanation"  SG_ 1184 BCM1_St_LFDoorLock "cmwr,ssbs,ac,bdcpeps,tbox";
BA_ "sigSecLevel"  SG_ 1184 BCM1_St_PasDoorLock "";
BA_ "sigExplanation"  SG_ 1184 BCM1_St_PasDoorLock "cmwr,ac,bdcpeps,tbox";
BA_ "sigSecLevel"  SG_ 1184 BCM1_St_DriverDoor "";
BA_ "sigExplanation"  SG_ 1184 BCM1_St_DriverDoor "ems,tcm,wcbsesp,fdca,alc,amp,wddc,cmwr,wcm,ipc,apa,svm,escl,dsm,ac,bdcpeps,tbox";
BA_ "sigSecLevel"  SG_ 1184 BCM1_St_PassengerDoor "";
BA_ "sigExplanation"  SG_ 1184 BCM1_St_PassengerDoor "fdca,alc,amp,wddc,cmwr,ipc,apa,dsm,ac,bdcpeps,tbox,wcbsesp";
BA_ "sigSecLevel"  SG_ 1184 BCM1_St_LRDoor "";
BA_ "sigExplanation"  SG_ 1184 BCM1_St_LRDoor "fdca,alc,amp,wddc,cmwr,ipc,apa,ac,bdcpeps,tbox,wcbsesp";
BA_ "sigSecLevel"  SG_ 1184 BCM1_St_RRDoor "";
BA_ "sigExplanation"  SG_ 1184 BCM1_St_RRDoor "fdca,alc,amp,wddc,cmwr,ipc,apa,ac,bdcpeps,tbox,wcbsesp";
BA_ "sigSecLevel"  SG_ 1184 BCM1_St_TrunkDoor "";
BA_ "sigExplanation"  SG_ 1184 BCM1_St_TrunkDoor "amp,ipc,apa,bdcpeps,tbox,wcbsesp,FDCA";
BA_ "sigSecLevel"  SG_ 1184 BCM1_St_Hood "";
BA_ "sigExplanation"  SG_ 1184 BCM1_St_Hood "ems,fdca,ipc,apa,bdcpeps,tbox,wcbsesp";
BA_ "sigSecLevel"  SG_ 1184 BCM1_Sw_Brake "";
BA_ "sigExplanation"  SG_ 1184 BCM1_Sw_Brake "apa,tbox";
BA_ "sigSecLevel"  SG_ 1184 BCM1_Sw_ReverseGear "";
BA_ "sigExplanation"  SG_ 1184 BCM1_Sw_ReverseGear "ems,wcbsesp,ehc,tbox,apa,tbox";
BA_ "sigSecLevel"  SG_ 1184 BCM1_St_LowBeam "";
BA_ "sigExplanation"  SG_ 1184 BCM1_St_LowBeam "fdca,ipc,apa,tbox，hud";
BA_ "sigSecLevel"  SG_ 1184 BCM1_Cmd_BrakeLamp "";
BA_ "sigExplanation"  SG_ 1184 BCM1_Cmd_BrakeLamp "apa,tbox";
BA_ "sigDespEng"  SG_ 1184 BCM1_Cmd_HazardInd "闪烁";
BA_ "sigSecLevel"  SG_ 1184 BCM1_Cmd_HazardInd "";
BA_ "sigExplanation"  SG_ 1184 BCM1_Cmd_HazardInd "fdca,apa,bdcpeps,tbox";
BA_ "sigSecLevel"  SG_ 1184 BCM1_Cmd_HighBeam "";
BA_ "sigExplanation"  SG_ 1184 BCM1_Cmd_HighBeam "ems,fdca,dvr,ipc,ehc,apa,tbox,hud";
BA_ "sigSecLevel"  SG_ 1184 BCM1_Cmd_LowBeam "";
BA_ "sigExplanation"  SG_ 1184 BCM1_Cmd_LowBeam "ems,fdca,dvr,ipc,ehc,apa,tbox，hud";
BA_ "sigSecLevel"  SG_ 1184 BCM1_St_BrakeFluidLowWarning "";
BA_ "sigExplanation"  SG_ 1184 BCM1_St_BrakeFluidLowWarning "apa,tbox";
BA_ "sigSecLevel"  SG_ 1184 BCM1_St_DRL "";
BA_ "sigExplanation"  SG_ 1184 BCM1_St_DRL "tbox, apa";
BA_ "sigSecLevel"  SG_ 1184 BCM1_Cmd_FrontFoglamp "";
BA_ "sigExplanation"  SG_ 1184 BCM1_Cmd_FrontFoglamp "ems,fdca,dvr,ipc,apa,tbox，ehc";
BA_ "sigSecLevel"  SG_ 1184 BCM1_St_FrontFoglamp "";
BA_ "sigExplanation"  SG_ 1184 BCM1_St_FrontFoglamp "fdca,ipc,apa,tbox";
BA_ "sigSecLevel"  SG_ 1184 BCM1_Cmd_RearFoglamp "";
BA_ "sigExplanation"  SG_ 1184 BCM1_Cmd_RearFoglamp "ems,fdca,dvr,ipc,ehc,apa,tbox";
BA_ "sigSecLevel"  SG_ 1184 BCM1_St_RearFoglamp "";
BA_ "sigExplanation"  SG_ 1184 BCM1_St_RearFoglamp "fdca,ipc,apa,tbox";
BA_ "GenMsgCycleTime" BO_ 1203 100;
BA_ "VFrameFormat" BO_ 1203 14;
BA_ "sigSecLevel"  SG_ 1203 BCM2_St_FrontWiper "";
BA_ "sigExplanation"  SG_ 1203 BCM2_St_FrontWiper "fdca,ehc";
BA_ "sigSecLevel"  SG_ 1203 BCM2_St_LRDoorLock "";
BA_ "sigExplanation"  SG_ 1203 BCM2_St_LRDoorLock "cmwr,ac，tbox,APA";
BA_ "sigSecLevel"  SG_ 1203 BCM2_St_RRDoorLock "";
BA_ "sigExplanation"  SG_ 1203 BCM2_St_RRDoorLock "cmwr,ac，tbox,APA";
BA_ "GenMsgCycleTime" BO_ 866 100;
BA_ "VFrameFormat" BO_ 866 14;
BA_ "sigSecLevel"  SG_ 866 BCM4_St_DRSeatbelt "";
BA_ "sigExplanation"  SG_ 866 BCM4_St_DRSeatbelt "ems,wcbsesp,sdm,fdca,dvr,ipc,apa,tbox";
BA_ "sigDespEng"  SG_ 866 BCM4_St_PASeatbelt "Warning Status for Passenger occupied with Passenger Seatbelt Buckle Switch  Unbuckled";
BA_ "sigSecLevel"  SG_ 866 BCM4_St_PASeatbelt "";
BA_ "sigExplanation"  SG_ 866 BCM4_St_PASeatbelt "ems,sdm,ipc,apa,tbox";
BA_ "sigDespEng"  SG_ 866 BCM4_St_RLSeatbelt "RearRow Left  Seatbelt Buckle Switch Status";
BA_ "sigSecLevel"  SG_ 866 BCM4_St_RLSeatbelt "";
BA_ "sigExplanation"  SG_ 866 BCM4_St_RLSeatbelt "ems,sdm,ipc,apa,tbox";
BA_ "sigDespEng"  SG_ 866 BCM4_St_RRSeatbelt "Rear Row Right  Seatbelt Buckle Switch Status";
BA_ "sigSecLevel"  SG_ 866 BCM4_St_RRSeatbelt "";
BA_ "sigExplanation"  SG_ 866 BCM4_St_RRSeatbelt "ems,sdm,ipc,apa,tbox";
BA_ "sigDespEng"  SG_ 866 BCM4_St_RMSeatbelt "Rear Middle  Seatbelt Buckle Switch Status";
BA_ "sigSecLevel"  SG_ 866 BCM4_St_RMSeatbelt "";
BA_ "sigExplanation"  SG_ 866 BCM4_St_RMSeatbelt "ems,sdm,ipc,apa,tbox";
BA_ "sigSecLevel"  SG_ 866 BCM4_Sw_PositionLamp "";
BA_ "sigExplanation"  SG_ 866 BCM4_Sw_PositionLamp "fdca";
BA_ "sigSecLevel"  SG_ 866 BCM4_Sw_LowLamp "";
BA_ "sigExplanation"  SG_ 866 BCM4_Sw_LowLamp "fdca";
BA_ "sigSecLevel"  SG_ 866 BCM4_Sw_HighLamp "";
BA_ "sigExplanation"  SG_ 866 BCM4_Sw_HighLamp "fdca";
BA_ "sigSecLevel"  SG_ 866 BCM4_Sw_AutoLamp "";
BA_ "sigExplanation"  SG_ 866 BCM4_Sw_AutoLamp "fdca";
BA_ "sigSecLevel"  SG_ 866 BCM4_Sw_FlashLamp "";
BA_ "sigExplanation"  SG_ 866 BCM4_Sw_FlashLamp "fdca";
BA_ "sigSecLevel"  SG_ 866 BCM4_St_HBA "";
BA_ "sigExplanation"  SG_ 866 BCM4_St_HBA "fdca";
BA_ "sigSecLevel"  SG_ 866 BCM4_Sw_RearFogLamp "";
BA_ "sigExplanation"  SG_ 866 BCM4_Sw_RearFogLamp "fdca";
BA_ "GenMsgCycleTime" BO_ 1383 100;
BA_ "VFrameFormat" BO_ 1383 14;
BA_ "sigSecLevel"  SG_ 1383 BCM9_St_LightSoundInhibition "";
BA_ "sigConfig"  SG_ 1383 BCM9_St_LightSoundInhibition "OTA";
BA_ "sigExplanation"  SG_ 1383 BCM9_St_LightSoundInhibition "IDS、FHS、RHS、SSBS、HUD、DVR、SVM、SWFB、CSS、AMP、WCBS、EGSM、AC、DSM、SWH、PWC/WCM、CMRR、CDC";
BA_ "GenMsgCycleTime" BO_ 1380 50;
BA_ "VFrameFormat" BO_ 1380 14;
BA_ "sigSecLevel"  SG_ 1380 DLF1_St_LmirrorFold "";
BA_ "sigExplanation"  SG_ 1380 DLF1_St_LmirrorFold "bdcbcm,apa";
BA_ "GenMsgCycleTime" BO_ 1382 100;
BA_ "VFrameFormat" BO_ 1382 14;
BA_ "sigSecLevel"  SG_ 1382 DRF1_St_RmirrorFold "";
BA_ "sigExplanation"  SG_ 1382 DRF1_St_RmirrorFold "bdcbcm，apa";
BA_ "GenMsgCycleTime" BO_ 1328 100;
BA_ "VFrameFormat" BO_ 1328 14;
BA_ "sigSecLevel"  SG_ 1328 AC1_F_OutsideTemp "";
BA_ "sigExplanation"  SG_ 1328 AC1_F_OutsideTemp "ems,tcm,wcbsesp,fdca,alc,pas,ipc,apa,ssbs,dsm,bdctpms";
BA_ "sigSecLevel"  SG_ 1328 AC1_N_OutsideTemp "";
BA_ "sigExplanation"  SG_ 1328 AC1_N_OutsideTemp "ems,tcm,wcbsesp,fdca,alc,pas,ipc,ssbs,dsm,bdctpms,bdcbcm";
BA_ "GenMsgCycleTime" BO_ 901 50;
BA_ "VFrameFormat" BO_ 901 14;
BA_ "sigSecLevel"  SG_ 901 CMRR_RR1_Checksum "";
BA_ "sigExplanation"  SG_ 901 CMRR_RR1_Checksum "wcbs";
BA_ "sigSecLevel"  SG_ 901 CMRR_RR1_RollingCounter "";
BA_ "sigExplanation"  SG_ 901 CMRR_RR1_RollingCounter "wcbs";
BA_ "sigSecLevel"  SG_ 901 CMRR_RR1_W_LHBSD "";
BA_ "sigExplanation"  SG_ 901 CMRR_RR1_W_LHBSD "cdc，fdca，ids";
BA_ "sigSecLevel"  SG_ 901 CMRR_RR1_W_LHLCA "";
BA_ "sigExplanation"  SG_ 901 CMRR_RR1_W_LHLCA "cdc，fdca，ids";
BA_ "sigSecLevel"  SG_ 901 CMRR_RR1_W_LHDOW "";
BA_ "sigExplanation"  SG_ 901 CMRR_RR1_W_LHDOW "cdc，ids";
BA_ "sigSecLevel"  SG_ 901 CMRR_RR1_W_LHRCTA "";
BA_ "sigExplanation"  SG_ 901 CMRR_RR1_W_LHRCTA "cdc，ids";
BA_ "sigSecLevel"  SG_ 901 CMRR_RR1_W_RHRCTB "";
BA_ "sigExplanation"  SG_ 901 CMRR_RR1_W_RHRCTB "cdc，ids，wcbs";
BA_ "sigSecLevel"  SG_ 901 CMRR_RR1_St_Failure "";
BA_ "sigExplanation"  SG_ 901 CMRR_RR1_St_Failure "cdc，fdca，ids，wcbs";
BA_ "sigSecLevel"  SG_ 901 CMRR_RR1_W_RHRCTBDecel "";
BA_ "sigExplanation"  SG_ 901 CMRR_RR1_W_RHRCTBDecel "wcbs";
BA_ "sigSecLevel"  SG_ 901 CMRR_RCTBTarA "";
BA_ "sigConfig"  SG_ 901 CMRR_RCTBTarA "B81";
BA_ "sigSecLevel"  SG_ 901 CMRR_RCTBTarAVld "";
BA_ "sigConfig"  SG_ 901 CMRR_RCTBTarAVld "B81";
BA_ "sigSecLevel"  SG_ 901 CMRR_RCTBTarAReq "";
BA_ "sigConfig"  SG_ 901 CMRR_RCTBTarAReq "B81";
BA_ "GenMsgCycleTime" BO_ 902 50;
BA_ "VFrameFormat" BO_ 902 14;
BA_ "sigSecLevel"  SG_ 902 CMRR_RR2_Checksum "";
BA_ "sigSecLevel"  SG_ 902 CMRR_RR2_RollingCounter "";
BA_ "sigSecLevel"  SG_ 902 CMRR_RR2_St_RCTA "";
BA_ "sigExplanation"  SG_ 902 CMRR_RR2_St_RCTA "cdc";
BA_ "sigSecLevel"  SG_ 902 CMRR_RR2_St_RCTB "";
BA_ "sigExplanation"  SG_ 902 CMRR_RR2_St_RCTB "cdc";
BA_ "sigSecLevel"  SG_ 902 CMRR_RR2_St_RCW "";
BA_ "sigExplanation"  SG_ 902 CMRR_RR2_St_RCW "cdc";
BA_ "sigSecLevel"  SG_ 902 CMRR_RR2_SwFb_RCW "";
BA_ "sigExplanation"  SG_ 902 CMRR_RR2_SwFb_RCW "cdc";
BA_ "sigSecLevel"  SG_ 902 CMRR_RR2_W_RHBSD "";
BA_ "sigExplanation"  SG_ 902 CMRR_RR2_W_RHBSD "cdc，fdca，ids";
BA_ "sigSecLevel"  SG_ 902 CMRR_RR2_W_RHLCA "";
BA_ "sigExplanation"  SG_ 902 CMRR_RR2_W_RHLCA "cdc，fdca，ids";
BA_ "sigSecLevel"  SG_ 902 CMRR_RR2_W_RHDOW "";
BA_ "sigExplanation"  SG_ 902 CMRR_RR2_W_RHDOW "cdc，ids";
BA_ "sigSecLevel"  SG_ 902 CMRR_RR2_W_RHRCTA "";
BA_ "sigExplanation"  SG_ 902 CMRR_RR2_W_RHRCTA "cdc，ids";
BA_ "sigSecLevel"  SG_ 902 CMRR_RR2_W_RCW "";
BA_ "sigExplanation"  SG_ 902 CMRR_RR2_W_RCW "cdc，ids";
BA_ "sigSecLevel"  SG_ 902 CMRR_RR2_St_DOW "";
BA_ "sigExplanation"  SG_ 902 CMRR_RR2_St_DOW "cdc";
BA_ "sigSecLevel"  SG_ 902 CMRR_RR2_St_BSD_LCA "";
BA_ "sigExplanation"  SG_ 902 CMRR_RR2_St_BSD_LCA "cdc，fdca";
BA_ "sigSecLevel"  SG_ 902 CMRR_RR2_St_Blindness "";
BA_ "sigExplanation"  SG_ 902 CMRR_RR2_St_Blindness "cdc，fdca，ids";
BA_ "sigSecLevel"  SG_ 902 CMRR_RR2_St_Calibration "";
BA_ "sigExplanation"  SG_ 902 CMRR_RR2_St_Calibration "fdca";
BA_ "sigSecLevel"  SG_ 902 CMRR_RR2_SwFb_RCTA "";
BA_ "sigExplanation"  SG_ 902 CMRR_RR2_SwFb_RCTA "cdc";
BA_ "sigSecLevel"  SG_ 902 CMRR_RR2_SwFb_RCTB "";
BA_ "sigExplanation"  SG_ 902 CMRR_RR2_SwFb_RCTB "cdc";
BA_ "sigSecLevel"  SG_ 902 CMRR_RR2_SwFb_BSD_LCA "";
BA_ "sigExplanation"  SG_ 902 CMRR_RR2_SwFb_BSD_LCA "cdc，ids";
BA_ "sigSecLevel"  SG_ 902 CMRR_RR2_SwFb_DOW "";
BA_ "sigExplanation"  SG_ 902 CMRR_RR2_SwFb_DOW "cdc";
BA_ "GenMsgCycleTime" BO_ 324 20;
BA_ "VFrameFormat" BO_ 324 14;
BA_ "sigSecLevel"  SG_ 324 Pdcu0x144Chks1 "";
BA_ "sigExplanation"  SG_ 324 Pdcu0x144Chks1 "ipc,ems,bms,mcufgcu,mcur,dcdcobc,cgw";
BA_ "sigSecLevel"  SG_ 324 Pdcu0x144Cntr1 "";
BA_ "sigExplanation"  SG_ 324 Pdcu0x144Cntr1 "ipc,ems,bms,mcufgcu,mcur,dcdcobc,cgw";
BA_ "sigSecLevel"  SG_ 324 PdcuRdySt "";
BA_ "sigExplanation"  SG_ 324 PdcuRdySt "ipc,ems,bms,mcufgcu,mcur,dcdcobc,cgw";
BA_ "sigDespEng"  SG_ 324 PdcuDrvCycDetc "OBD";
BA_ "sigSecLevel"  SG_ 324 PdcuDrvCycDetc "";
BA_ "sigExplanation"  SG_ 324 PdcuDrvCycDetc "BMS、MCUr、MCUfGCU、DCDCOBC、EMS、WCBS，CGW";
BA_ "sigDespEng"  SG_ 324 PdcuWrmupCycDetec "OBD";
BA_ "sigSecLevel"  SG_ 324 PdcuWrmupCycDetec "";
BA_ "sigExplanation"  SG_ 324 PdcuWrmupCycDetec "BMS、MCUr、MCUf&GCU、DCDC&OBC、EMS、WCBS，CGW";
BA_ "sigSecLevel"  SG_ 324 PdcuEspVehSpd "";
BA_ "sigExplanation"  SG_ 324 PdcuEspVehSpd "ems，mcufgcu,mcur,cgw";
BA_ "sigSecLevel"  SG_ 324 PdcuEnrgMod "";
BA_ "sigExplanation"  SG_ 324 PdcuEnrgMod "ems，dcdcobc（tbd），mcufgcu，mcur，cgw，cdc";
BA_ "sigSecLevel"  SG_ 324 PdcuTqPatonRat "";
BA_ "sigExplanation"  SG_ 324 PdcuTqPatonRat "mcur,mcufgcu,cgw";
BA_ "sigSecLevel"  SG_ 324 PdcuSelGearVld "";
BA_ "sigExplanation"  SG_ 324 PdcuSelGearVld "ipc,mcur,mcufgcu,cgw,fdca，apa";
BA_ "sigSecLevel"  SG_ 324 PdcuSelGear "";
BA_ "sigExplanation"  SG_ 324 PdcuSelGear "ipc,mcur,mcufgcu,cgw，fdca，apa";
BA_ "sigSecLevel"  SG_ 324 PdcuTqFltFlg "";
BA_ "sigExplanation"  SG_ 324 PdcuTqFltFlg "mcur,mcufgcu,cgw";
BA_ "sigSecLevel"  SG_ 324 PdcuActvDchaEnaFlg "";
BA_ "sigExplanation"  SG_ 324 PdcuActvDchaEnaFlg "mcur,mcufgcu,cgw";
BA_ "sigSecLevel"  SG_ 324 PdcuVehAllwRefrshFlg "";
BA_ "sigExplanation"  SG_ 324 PdcuVehAllwRefrshFlg "mcur,mcufgcu,cgw";
BA_ "sigSecLevel"  SG_ 324 PdcuStrtActv "";
BA_ "sigExplanation"  SG_ 324 PdcuStrtActv "ipc,ems";
BA_ "sigSecLevel"  SG_ 324 PdcuAccrPedl1Volt "";
BA_ "sigExplanation"  SG_ 324 PdcuAccrPedl1Volt "ems";
BA_ "GenSigStartValue" SG_ 324 PdcuAccrPedl1VoltVld 1;
BA_ "sigSecLevel"  SG_ 324 PdcuAccrPedl1VoltVld "";
BA_ "sigExplanation"  SG_ 324 PdcuAccrPedl1VoltVld "ems";
BA_ "GenMsgCycleTime" BO_ 267 10;
BA_ "VFrameFormat" BO_ 267 14;
BA_ "sigSecLevel"  SG_ 267 PdcuAccPedalPosVld "";
BA_ "sigExplanation"  SG_ 267 PdcuAccPedalPosVld "wcbs, apa，fdca";
BA_ "sigSecLevel"  SG_ 267 PdcuAccPedalPosDigVld "";
BA_ "sigExplanation"  SG_ 267 PdcuAccPedalPosDigVld "wcbs, apa，fdca";
BA_ "sigSecLevel"  SG_ 267 PdcuAccPedalPos "";
BA_ "sigExplanation"  SG_ 267 PdcuAccPedalPos "wcbs, apa，fdca";
BA_ "sigSecLevel"  SG_ 267 PdcuAccPedalPosDig "";
BA_ "sigExplanation"  SG_ 267 PdcuAccPedalPosDig "wcbs, apa，fdca";
BA_ "sigSecLevel"  SG_ 267 PdcuEbrEnFlg "";
BA_ "sigExplanation"  SG_ 267 PdcuEbrEnFlg "wcbs,fdca";
BA_ "sigSecLevel"  SG_ 267 PdcuEbrReqFlg "";
BA_ "sigExplanation"  SG_ 267 PdcuEbrReqFlg "wcbs,fdca";
BA_ "sigSecLevel"  SG_ 267 PdcuEbrTagTrq "";
BA_ "sigExplanation"  SG_ 267 PdcuEbrTagTrq "wcbs,fdca";
BA_ "sigSecLevel"  SG_ 267 PdcuEbrStandstillFlg "";
BA_ "sigExplanation"  SG_ 267 PdcuEbrStandstillFlg "wcbs,fdca";
BA_ "sigSecLevel"  SG_ 267 PdcuAbsltAccrPedlPosn "";
BA_ "sigExplanation"  SG_ 267 PdcuAbsltAccrPedlPosn "wcbs,fdca";
BA_ "sigSecLevel"  SG_ 267 PdcuAccDriverOverride "";
BA_ "sigExplanation"  SG_ 267 PdcuAccDriverOverride "wcbs,fdca";
BA_ "sigSecLevel"  SG_ 267 PdcuEcAvailable "";
BA_ "sigExplanation"  SG_ 267 PdcuEcAvailable "wcbs,fdca";
BA_ "sigSecLevel"  SG_ 267 PdcuApaShiftAvailable "";
BA_ "sigExplanation"  SG_ 267 PdcuApaShiftAvailable "wcbs,fdca";
BA_ "sigSecLevel"  SG_ 267 PdcuApaLeverIntervention "";
BA_ "sigExplanation"  SG_ 267 PdcuApaLeverIntervention "wcbs,fdca";
BA_ "GenMsgCycleTime" BO_ 290 10;
BA_ "VFrameFormat" BO_ 290 14;
BA_ "sigSecLevel"  SG_ 290 Pdcu0x122Chks1 "";
BA_ "sigConfig"  SG_ 290 Pdcu0x122Chks1 "B60VS";
BA_ "sigExplanation"  SG_ 290 Pdcu0x122Chks1 "wcbs";
BA_ "sigSecLevel"  SG_ 290 Pdcu0x122Cntr1 "";
BA_ "sigConfig"  SG_ 290 Pdcu0x122Cntr1 "B60VS";
BA_ "sigExplanation"  SG_ 290 Pdcu0x122Cntr1 "wcbs";
BA_ "sigSecLevel"  SG_ 290 PdcuFrntAxleTrqReq "";
BA_ "sigConfig"  SG_ 290 PdcuFrntAxleTrqReq "B60VS";
BA_ "sigExplanation"  SG_ 290 PdcuFrntAxleTrqReq "wcbs";
BA_ "sigSecLevel"  SG_ 290 PdcuFrntAxleTrqReqVld "";
BA_ "sigConfig"  SG_ 290 PdcuFrntAxleTrqReqVld "B60VS";
BA_ "sigExplanation"  SG_ 290 PdcuFrntAxleTrqReqVld "wcbs";
BA_ "sigSecLevel"  SG_ 290 PdcuFrntAxleTrqAct "";
BA_ "sigConfig"  SG_ 290 PdcuFrntAxleTrqAct "B60VS";
BA_ "sigExplanation"  SG_ 290 PdcuFrntAxleTrqAct "wcbs";
BA_ "sigSecLevel"  SG_ 290 PdcuFrntAxleTrqActVld "";
BA_ "sigConfig"  SG_ 290 PdcuFrntAxleTrqActVld "B60VS";
BA_ "sigExplanation"  SG_ 290 PdcuFrntAxleTrqActVld "wcbs";
BA_ "sigSecLevel"  SG_ 290 PdcuFrntAxleTrqMaxLim "";
BA_ "sigConfig"  SG_ 290 PdcuFrntAxleTrqMaxLim "B60VS";
BA_ "sigExplanation"  SG_ 290 PdcuFrntAxleTrqMaxLim "wcbs";
BA_ "sigSecLevel"  SG_ 290 PdcuFrntAxleTrqMaxLimVld "";
BA_ "sigConfig"  SG_ 290 PdcuFrntAxleTrqMaxLimVld "B60VS";
BA_ "sigExplanation"  SG_ 290 PdcuFrntAxleTrqMaxLimVld "wcbs";
VAL_ 582 FDCA4_Cmd_BrakePreferred 1 "Demand" 0 "No demand" ;
VAL_ 582 FDCA4_St_ReqDriveroff 1 "Demand" 0 "No demand" ;
VAL_ 582 FDCA4_St_ReqHBA 1 "Demand" 0 "No demand" ;
VAL_ 582 FDCA4_St_ReqPrefill 1 "Demand" 0 "No demand" ;
VAL_ 582 FDCA4_Cmd_DecToStop 1 "Demand" 0 "No demand" ;
VAL_ 582 FDCA4_N_HBALevel 3 "Level3" 2 "Level2" 1 "Level1" 0 "Level0" ;
VAL_ 582 FDCA4_ShutdownMod 3 "initial" 2 "immediate off(reserved)" 1 "fast off" 0 "soft off" ;
VAL_ 582 ADAS_FDCA4_St_AEBMode 4 "Failure mode" 3 "standby" 2 "Active mode" 1 "On mode" 0 "OFF mode" ;
VAL_ 582 FDCA4_St_ACCMode 15 "reserved" 14 "reserved" 13 "reserved" 12 "reserved" 11 "reserved" 10 "reserved" 9 "reserved" 8 "Failure mode" 7 "Stand-wait" 6 "Stand-active" 5 "Override" 4 "Brake-Only mode" 3 "Active-Control mode" 2 "Stand-By mode" 1 "Passive mode" 0 "OFF mode" ;
VAL_ 838 FDCA3_St_ACCMinimumBraking 1 "Demand" 0 "No demand" ;
VAL_ 838 FDCA3_St_AWBLevel 6 "Reserved" 5 "Reserved" 4 "Level4" 3 "Level3" 2 "Level2" 1 "Level1" 0 "No level" ;
VAL_ 838 FDCA3_St_ReqAWB 1 "Demand" 0 "No demand" ;
VAL_ 838 FDCA3_St_ReqAEBDecCtrl 1 "Demand" 0 "No demand" ;
VAL_ 838 FDCA3_St_ACCMode 7 "Failure mode" 6 "Standstill" 5 "Override" 4 "Brake only mode" 3 "Active control mode" 2 "Standby mode" 1 "Passive mode" 0 "OFF mode" ;
VAL_ 838 FDCA3_F_TorqueReq 3 "Reserved" 2 "ldsTorqueActive" 1 "ldsTorqueReady" 0 "ldsTorqueInhibited" ;
VAL_ 656 APA1_N_TargetSteeringAng 65535 "Invalid" ;
VAL_ 656 APA1_F_TargetSteeringAng 1 "Valid" 0 "Invalid" ;
VAL_ 656 APA1_St_ControlRequest 1 "Request EPS Control" 0 "No Request" ;
VAL_ 656 APA1_St_TarGearReq 5 "Invalid" 4 "Target gear D" 3 "Target gear N" 2 "Target gear R" 1 "Target gear P" 0 "No Request" ;
VAL_ 656 APA1_St_BrakeMode 5 "Abort" 4 "Suspend" 3 "ManeuverFinished" 2 "Active" 1 "Standby" 0 "Init" ;
VAL_ 656 APA1_St_BrakeFunctionMode 4 "Rserved" 3 "AutomaticPark" 2 "ParkEmergencyBrake" 1 "Comfortable" 0 "No Action" ;
VAL_ 656 APA1_St_FBrakeMode 3 "Reserved" 2 "Emergency" 1 "Comfortable" 0 "Idle (No Braking)" ;
VAL_ 657 APA2_St_AutoParkingIn 1 "Active" 0 "Inactive" ;
VAL_ 657 APA2_St_AutoParkingOut 1 "Active" 0 "Inactive" ;
VAL_ 657 APA2_St_UserSlot 1 "Active" 0 "Inactive" ;
VAL_ 657 APA2_St_Set 1 "Active" 0 "Inactive" ;
VAL_ 657 APA2_St_ParkOutDirSet 14 "Reserved" 13 "Reserved" 12 "Reserved" 11 "Reserved" 10 "Reserved" 9 "Reserved" 8 "Vertical Trunk Right" 7 "Vertical Trunk Left" 6 "Vertical Head Right" 5 "Vertical Head Left" 4 "Horizontal backward" 3 "Horizontal forward" 2 "Half Vehicle Right" 1 "Half Vehicle Left" 0 "Inactive" ;
VAL_ 657 APA2_RPA_RpaSts 15 "invalid" 14 "Reserved" 13 "Reserved" 12 "Reserved" 11 "Reserved" 10 "Reserved" 9 "RPA System Fault" 8 "RPA Out Success" 7 "RPA In Success" 6 "RPA Abort" 5 "RPA Suspend" 4 "RPA Operating" 3 "RPA Ready" 2 "RPA Parking Out Standby" 1 "RPA Parking In Standby" 0 "RPA Off" ;
VAL_ 657 APA2_St_Preference 2 "偏驾驶员侧 Driver_Side" 1 "居中 Center" 0 "none" ;
VAL_ 657 APA2_St_ParkingInMode 2 "遥控泊入 Tele_Control_Parking_In" 1 "一键泊入 One_Key_Parking_In" 0 "None" ;
VAL_ 657 APA2_St_ParkingInPreCon 1 "任一车门打开 Door_Opened" 0 "无请求 None" ;
VAL_ 657 APA2_St_APAStatus 7 "Suspended" 6 "Terminated" 5 "Failure" 4 "Completed" 3 "Guidance active" 2 "Searching" 1 "Standby" 0 "Off" ;
VAL_ 657 APA2_St_ParkingOutDirection 3 "Reserved" 2 "车尾泊入" 1 "车头泊入" 0 "None" ;
VAL_ 657 APA2_St_SelectedParkOutDire 2 "右边 Right" 1 "左边 Left" 0 "none" ;
VAL_ 657 APA2_St_DirHalfLeAvl 1 "active" 0 "inactive" ;
VAL_ 657 APA2_St_DirHalfRiAvl 1 "active" 0 "inactive" ;
VAL_ 657 APA2_St_DirHozlFwAvl 1 "active" 0 "inactive" ;
VAL_ 657 APA2_St_DirHozlBwAvl 1 "active" 0 "inactive" ;
VAL_ 657 APA2_St_DirVertHdLeAvl 1 "active" 0 "inactive" ;
VAL_ 657 APA2_St_DirVertHdRiAvl 1 "active" 0 "inactive" ;
VAL_ 657 APA2_St_DirVertTrLeAvl 1 "active" 0 "inactive" ;
VAL_ 657 APA2_St_DirVertTrRiAvl 1 "active" 0 "inactive" ;
VAL_ 657 APA2_St_Request 16 "请踩刹车提示 Please Press Brake Pedal" 15 "泊车系统功能选择提示 Select Parking Function" 14 "垂直类型车位，请选择泊入方式 Vertical_Slot_Please_Select_Parking_In_Mode" 13 "请挂P挡手刹下车后打开APP进行遥控泊车 Remote_Control_Prepare" 12 "车速过高 Over_Speed" 11 "车速过快无法找车位 Too_Fast_To_Searching_Slot" 10 "泊出完成 Parking_Out_Finished" 9 "选择泊出方向 Please_Select_Director" 8 "泊出空间不足 No_Room_To_Parking_Out" 7 "泊入完成 Parking_In_Finished" 6 "松开踏板双手离开方向盘 Please_Release_Brake" 5 "请选择车位方向并微调角度 Please_Use_User_Slot" 4 "水平类型车位，请选择泊入方式Horizontal_Slot_Please_Select_Parking_In_Mode" 3 "找到车位请停车 Please_Stop" 2 "请挂D挡搜索车位 Please_Switch_D_Gear" 1 "向前行驶搜索车位 Go_Forward_And_Search_Slot" 0 "无请求 None" ;
VAL_ 1427 APA3_St_Update 25 "升级成功" 24 "升级失败" 23 "MCU升级完成" 22 "MCU升级中" 21 "MPU升级完成" 10 "升级中(进度提示100%）" 9 "升级中（进度提示90%）" 8 "升级中（进度提示80%）" 7 "升级中（进度提示70%）" 6 "升级中（进度提示60%）" 5 "升级中（进度提示50%）" 4 "升级中（进度提示40%）" 3 "升级中（进度提示30%）" 2 "升级包校验中(进度提示20%)" 1 "升级包解压中（进度提示10%）" 0 "NONE" ;
VAL_ 1427 APA3_St_UpdateType 2 "OTA升级" 1 "TF卡升级" 0 "NONE" ;
VAL_ 917 AVM2_St_WormModeView 1 "ON" 0 "OFF" ;
VAL_ 917 AVM2_St_RockModeView 1 "ON" 0 "OFF" ;
VAL_ 917 AVM2_St_CurrViewType 15 "预留" 14 "预留" 13 "预留" 12 "预留" 11 "预留" 10 "预留" 9 "预留" 8 "预留" 7 "预留" 6 "预留" 5 "预留" 4 "预留" 3 "标定界面" 2 "岩石模式/蠕行模式开启AVM界面" 1 "普通AVM界面" 0 "NONE" ;
VAL_ 917 AVM2_St_Mode 1 "3D AVM" 0 "2D AVM" ;
VAL_ 917 AVM2_St_PerspectiveChassis 1 "ON" 0 "OFF" ;
VAL_ 917 AVM2_St_QuitAvmEnable 1 "可退出" 0 "不可退出" ;
VAL_ 917 AVM2_St_ModeSwitchEnable 1 "可切换" 0 "不可切换" ;
VAL_ 917 AVM2_St_PerspectiveEnable 1 "可开关" 0 "不可开关" ;
VAL_ 917 AVM2_St_MoreViewEnable 1 "可切换" 0 "不可切换" ;
VAL_ 917 AVM2_St_SettingEnable 1 "可进入" 0 "不可进入" ;
VAL_ 917 AVM2_St_WormEnable 1 "可切换" 0 "不可切换" ;
VAL_ 917 AVM2_St_RockEnable 1 "可切换" 0 "不可切换" ;
VAL_ 917 AVM2_St_Reseved 1 "可切换" 0 "不可切换" ;
VAL_ 917 AVM2_Set_TireTrajectory 1 "ON" 0 "OFF" ;
VAL_ 917 AVM2_Set_CarTrajectory 1 "ON" 0 "OFF" ;
VAL_ 917 AVM2_Set_2DRadar 1 "ON" 0 "OFF" ;
VAL_ 917 AVM2_Set_3DRadar 1 "ON" 0 "OFF" ;
VAL_ 917 AVM2_Set_TurnTriggerView 1 "ON" 0 "OFF" ;
VAL_ 917 AVM2_Set_RadarTriggerView 1 "ON" 0 "OFF" ;
VAL_ 917 AVM2_Error_Controller 1 "故障 Fault" 0 "正常 Normal" ;
VAL_ 917 AVM2_Error_ViewOutput 1 "故障 Fault" 0 "正常 Normal" ;
VAL_ 917 AvmVehLctSts 7 "Invalid" 6 "Reserved" 5 "Reserved" 4 "Reserved" 3 "Lucent" 2 "Translucent" 1 "Not Lucent" 0 "Inactive" ;
VAL_ 917 AVM2_Set_CarColor 6 "未来灰光亮版 EG33" 5 "丛林绿 EH09" 4 "谧夜蓝 EE28" 3 "极夜黑 EK03" 2 "迷雾蓝 EE47" 1 "苍石绿 EH35" 0 "雪域白 EC19" ;
VAL_ 917 AVM2_St_MoreViews 7 "reserved" 6 "reserved" 5 "车身两侧 Sides_View" 4 "后左右车轮 Back_Tires_View" 3 "前左右车轮 Front_Tires_View" 2 "后广角 Back_Large_View" 1 "前广角 Front_Large_View" 0 "未选择 None" ;
VAL_ 917 AVM2_St_CSSLight 1 "ON" 0 "OFF" ;
VAL_ 917 AVM2_St_RestoreSetting 1 "active（Restored）" 0 "inactive" ;
VAL_ 917 AVM2_St_PromptMessage 4 "提示内容:360系统重置失败；提示时长3s:信号置0结束" 3 "提示内容:360系统重置成功；提示时长3s:信号置0结束" 2 "提示内容:360系统重置中，请耐心等待，不要点击画面哦；提示时长3s:信号置0结束" 1 "提示内容:车速大于30km/h，为保证行车安全，将退出全景影像系统；提示时长3s:信号置0结束" 0 "无提示信息" ;
VAL_ 917 AVM2_St_PromptTimeOut 127 "弹窗超时(1~127秒)" 126 "弹窗超时(1~127秒)" 125 "弹窗超时(1~127秒)" 124 "弹窗超时(1~127秒)" 123 "弹窗超时(1~127秒)" 122 "弹窗超时(1~127秒)" 121 "弹窗超时(1~127秒)" 120 "弹窗超时(1~127秒)" 119 "弹窗超时(1~127秒)" 118 "弹窗超时(1~127秒)" 117 "弹窗超时(1~127秒)" 116 "弹窗超时(1~127秒)" 115 "弹窗超时(1~127秒)" 114 "弹窗超时(1~127秒)" 113 "弹窗超时(1~127秒)" 112 "弹窗超时(1~127秒)" 111 "弹窗超时(1~127秒)" 110 "弹窗超时(1~127秒)" 109 "弹窗超时(1~127秒)" 108 "弹窗超时(1~127秒)" 107 "弹窗超时(1~127秒)" 106 "弹窗超时(1~127秒)" 105 "弹窗超时(1~127秒)" 104 "弹窗超时(1~127秒)" 103 "弹窗超时(1~127秒)" 102 "弹窗超时(1~127秒)" 101 "弹窗超时(1~127秒)" 100 "弹窗超时(1~127秒)" 99 "弹窗超时(1~127秒)" 98 "弹窗超时(1~127秒)" 97 "弹窗超时(1~127秒)" 96 "弹窗超时(1~127秒)" 95 "弹窗超时(1~127秒)" 94 "弹窗超时(1~127秒)" 93 "弹窗超时(1~127秒)" 92 "弹窗超时(1~127秒)" 91 "弹窗超时(1~127秒)" 90 "弹窗超时(1~127秒)" 89 "弹窗超时(1~127秒)" 88 "弹窗超时(1~127秒)" 87 "弹窗超时(1~127秒)" 86 "弹窗超时(1~127秒)" 85 "弹窗超时(1~127秒)" 84 "弹窗超时(1~127秒)" 83 "弹窗超时(1~127秒)" 82 "弹窗超时(1~127秒)" 81 "弹窗超时(1~127秒)" 80 "弹窗超时(1~127秒)" 79 "弹窗超时(1~127秒)" 78 "弹窗超时(1~127秒)" 77 "弹窗超时(1~127秒)" 76 "弹窗超时(1~127秒)" 75 "弹窗超时(1~127秒)" 74 "弹窗超时(1~127秒)" 73 "弹窗超时(1~127秒)" 72 "弹窗超时(1~127秒)" 71 "弹窗超时(1~127秒)" 70 "弹窗超时(1~127秒)" 69 "弹窗超时(1~127秒)" 68 "弹窗超时(1~127秒)" 67 "弹窗超时(1~127秒)" 66 "弹窗超时(1~127秒)" 65 "弹窗超时(1~127秒)" 64 "弹窗超时(1~127秒)" 63 "弹窗超时(1~127秒)" 62 "弹窗超时(1~127秒)" 61 "弹窗超时(1~127秒)" 60 "弹窗超时(1~127秒)" 59 "弹窗超时(1~127秒)" 58 "弹窗超时(1~127秒)" 57 "弹窗超时(1~127秒)" 56 "弹窗超时(1~127秒)" 55 "弹窗超时(1~127秒)" 54 "弹窗超时(1~127秒)" 53 "弹窗超时(1~127秒)" 52 "弹窗超时(1~127秒)" 51 "弹窗超时(1~127秒)" 50 "弹窗超时(1~127秒)" 49 "弹窗超时(1~127秒)" 48 "弹窗超时(1~127秒)" 47 "弹窗超时(1~127秒)" 46 "弹窗超时(1~127秒)" 45 "弹窗超时(1~127秒)" 44 "弹窗超时(1~127秒)" 43 "弹窗超时(1~127秒)" 42 "弹窗超时(1~127秒)" 41 "弹窗超时(1~127秒)" 40 "弹窗超时(1~127秒)" 39 "弹窗超时(1~127秒)" 38 "弹窗超时(1~127秒)" 37 "弹窗超时(1~127秒)" 36 "弹窗超时(1~127秒)" 35 "弹窗超时(1~127秒)" 34 "弹窗超时(1~127秒)" 33 "弹窗超时(1~127秒)" 32 "弹窗超时(1~127秒)" 31 "弹窗超时(1~127秒)" 30 "弹窗超时(1~127秒)" 29 "弹窗超时(1~127秒)" 28 "弹窗超时(1~127秒)" 27 "弹窗超时(1~127秒)" 26 "弹窗超时(1~127秒)" 25 "弹窗超时(1~127秒)" 24 "弹窗超时(1~127秒)" 23 "弹窗超时(1~127秒)" 22 "弹窗超时(1~127秒)" 21 "弹窗超时(1~127秒)" 20 "弹窗超时(1~127秒)" 19 "弹窗超时(1~127秒)" 18 "弹窗超时(1~127秒)" 17 "弹窗超时(1~127秒)" 16 "弹窗超时(1~127秒)" 15 "弹窗超时(1~127秒)" 14 "弹窗超时(1~127秒)" 13 "弹窗超时(1~127秒)" 12 "弹窗超时(1~127秒)" 11 "弹窗超时(1~127秒)" 10 "弹窗超时(1~127秒)" 9 "弹窗超时(1~127秒)" 8 "弹窗超时(1~127秒)" 7 "弹窗超时(1~127秒)" 6 "弹窗超时(1~127秒)" 5 "弹窗超时(1~127秒)" 4 "弹窗超时(1~127秒)" 3 "弹窗超时(1~127秒)" 2 "弹窗超时(1~127秒)" 1 "弹窗超时(1~127秒)" 0 "弹窗未超时" ;
VAL_ 917 FrntcamFaild 1 "Fault" 0 "No Fault" ;
VAL_ 917 RecamFaild 1 "Fault" 0 "No Fault" ;
VAL_ 917 LecamFaild 1 "Fault" 0 "No Fault" ;
VAL_ 917 RicamFaild 1 "Fault" 0 "No Fault" ;
VAL_ 917 AvmCtrlrFaild 7 "reserved" 6 "reserved" 5 "reserved" 4 "reserved" 3 "reserved" 2 "reserved" 1 "Fault" 0 "No Fault" ;
VAL_ 917 AvmSts 7 "reserved" 6 "reserved" 5 "reserved" 4 "reserved" 3 "reserved" 2 "reserved" 1 "AVM ON" 0 "Standby state" ;
VAL_ 901 CMRR_RR1_W_LHBSD 3 "Reserved" 2 "L2" 1 "L1" 0 "No Warning" ;
VAL_ 901 CMRR_RR1_W_LHLCA 3 "Reserved" 2 "L2" 1 "L1" 0 "No Warning" ;
VAL_ 901 CMRR_RR1_W_LHDOW 3 "Reserved" 2 "L2" 1 "L1" 0 "No Warning" ;
VAL_ 901 CMRR_RR1_W_LHRCTA 3 "Reserved" 2 "Reserved" 1 "Warning" 0 "No Warning" ;
VAL_ 901 CMRR_RR1_W_RHRCTB 3 "Reserved" 2 "Reserved" 1 "Brake" 0 "No brake" ;
VAL_ 901 CMRR_RR1_St_Failure 3 "Rear Left and Right Failure" 2 "Rear Right Failure" 1 "Rear Left Failure" 0 "No Failure" ;
VAL_ 901 CMRR_RR1_W_RHRCTBDecel 255 "Valid value" 254 "Valid value" 253 "Valid value" 252 "Valid value" 251 "Valid value" 250 "Valid value" 249 "Valid value" 248 "Valid value" 247 "Valid value" 246 "Valid value" 245 "Valid value" 244 "Valid value" 243 "Valid value" 242 "Valid value" 241 "Valid value" 240 "Valid value" 239 "Valid value" 238 "Valid value" 237 "Valid value" 236 "Valid value" 235 "Valid value" 234 "Valid value" 233 "Valid value" 232 "Valid value" 231 "Valid value" 230 "Valid value" 229 "Valid value" 228 "Valid value" 227 "Valid value" 226 "Valid value" 225 "Valid value" 224 "Valid value" 223 "Valid value" 222 "Valid value" 221 "Valid value" 220 "Valid value" 219 "Valid value" 218 "Valid value" 217 "Valid value" 216 "Valid value" 215 "Valid value" 214 "Valid value" 213 "Valid value" 212 "Valid value" 211 "Valid value" 210 "Valid value" 209 "Valid value" 208 "Valid value" 207 "Valid value" 206 "Valid value" 205 "Valid value" 204 "Valid value" 203 "Valid value" 202 "Valid value" 201 "Valid value" 200 "Valid value" 199 "Valid value" 198 "Valid value" 197 "Valid value" 196 "Valid value" 195 "Valid value" 194 "Valid value" 193 "Valid value" 192 "Valid value" 191 "Valid value" 190 "Valid value" 189 "Valid value" 188 "Valid value" 187 "Valid value" 186 "Valid value" 185 "Valid value" 184 "Valid value" 183 "Valid value" 182 "Valid value" 181 "Valid value" 180 "Valid value" 179 "Valid value" 178 "Valid value" 177 "Valid value" 176 "Valid value" 175 "Valid value" 174 "Valid value" 173 "Valid value" 172 "Valid value" 171 "Valid value" 170 "Valid value" 169 "Valid value" 168 "Valid value" 167 "Valid value" 166 "Valid value" 165 "Valid value" 164 "Valid value" 163 "Valid value" 162 "Valid value" 161 "Valid value" 160 "Valid value" 159 "Valid value" 158 "Valid value" 157 "Valid value" 156 "Valid value" 155 "Valid value" 154 "Valid value" 153 "Valid value" 152 "Valid value" 151 "Valid value" 150 "Valid value" 149 "Valid value" 148 "Valid value" 147 "Valid value" 146 "Valid value" 145 "Valid value" 144 "Valid value" 143 "Valid value" 142 "Valid value" 141 "Valid value" 140 "Valid value" 139 "Valid value" 138 "Valid value" 137 "Valid value" 136 "Valid value" 135 "Valid value" 134 "Valid value" 133 "Valid value" 132 "Valid value" 131 "Valid value" 130 "Valid value" 129 "Valid value" 128 "Valid value" 127 "Valid value" 126 "Valid value" 125 "Valid value" 124 "Valid value" 123 "Valid value" 122 "Valid value" 121 "Valid value" 120 "Valid value" 119 "Valid value" 118 "Valid value" 117 "Valid value" 116 "Valid value" 115 "Valid value" 114 "Valid value" 113 "Valid value" 112 "Valid value" 111 "Valid value" 110 "Valid value" 109 "Valid value" 108 "Valid value" 107 "Valid value" 106 "Valid value" 105 "Valid value" 104 "Valid value" 103 "Valid value" 102 "Valid value" 101 "Valid value" 100 "Valid value" 99 "Valid value" 98 "Valid value" 97 "Valid value" 96 "Valid value" 95 "Valid value" 94 "Valid value" 93 "Valid value" 92 "Valid value" 91 "Valid value" 90 "Valid value" 89 "Valid value" 88 "Valid value" 87 "Valid value" 86 "Valid value" 85 "Valid value" 84 "Valid value" 83 "Valid value" 82 "Valid value" 81 "Valid value" 80 "Valid value" 79 "Valid value" 78 "Valid value" 77 "Valid value" 76 "Valid value" 75 "Valid value" 74 "Valid value" 73 "Valid value" 72 "Valid value" 71 "Valid value" 70 "Valid value" 69 "Valid value" 68 "Valid value" 67 "Valid value" 66 "Valid value" 65 "Valid value" 64 "Valid value" 63 "Valid value" 62 "Valid value" 61 "Valid value" 60 "Valid value" 59 "Valid value" 58 "Valid value" 57 "Valid value" 56 "Valid value" 55 "Valid value" 54 "Valid value" 53 "Valid value" 52 "Valid value" 51 "Valid value" 50 "Valid value" 49 "Valid value" 48 "Valid value" 47 "Valid value" 46 "Valid value" 45 "Valid value" 44 "Valid value" 43 "Valid value" 42 "Valid value" 41 "Valid value" 40 "Valid value" 39 "Valid value" 38 "Valid value" 37 "Valid value" 36 "Valid value" 35 "Valid value" 34 "Valid value" 33 "Valid value" 32 "Valid value" 31 "Valid value" 30 "Valid value" 29 "Valid value" 28 "Valid value" 27 "Valid value" 26 "Valid value" 25 "Valid value" 24 "Valid value" 23 "Valid value" 22 "Valid value" 21 "Valid value" 20 "Valid value" 19 "Valid value" 18 "Valid value" 17 "Valid value" 16 "Valid value" 15 "Valid value" 14 "Valid value" 13 "Valid value" 12 "Valid value" 11 "Valid value" 10 "Valid value" 9 "Valid value" 8 "Valid value" 7 "Valid value" 6 "Valid value" 5 "Valid value" 4 "Valid value" 3 "Valid value" 2 "Valid value" 1 "Valid value" 0 "Valid value" ;
VAL_ 901 CMRR_RCTBTarAVld 1 "Valid" 0 "Invalid" ;
VAL_ 901 CMRR_RCTBTarAReq 1 "Request" 0 "Not Request" ;
VAL_ 902 CMRR_RR2_St_RCTA 7 "reserved" 6 "reserved" 5 "reserved" 4 "Failure" 3 "Active" 2 "Standby" 1 "Off" 0 "Init" ;
VAL_ 902 CMRR_RR2_St_RCTB 7 "reserved" 6 "reserved" 5 "reserved" 4 "Failure" 3 "Active" 2 "Standby" 1 "Off" 0 "Init" ;
VAL_ 902 CMRR_RR2_St_RCW 7 "reserved" 6 "reserved" 5 "reserved" 4 "Failure" 3 "Active" 2 "Standby" 1 "Off" 0 "Init" ;
VAL_ 902 CMRR_RR2_SwFb_RCW 1 "ON" 0 "OFF" ;
VAL_ 902 CMRR_RR2_W_RHBSD 3 "Reserved" 2 "L2" 1 "L1" 0 "No Warning" ;
VAL_ 902 CMRR_RR2_W_RHLCA 3 "Reserved" 2 "L2" 1 "L1" 0 "No Warning" ;
VAL_ 902 CMRR_RR2_W_RHDOW 3 "Reserved" 2 "L2" 1 "L1" 0 "No Warning" ;
VAL_ 902 CMRR_RR2_W_RHRCTA 3 "Reserved" 2 "Reserved" 1 "Warning" 0 "No Warning" ;
VAL_ 902 CMRR_RR2_W_RCW 3 "Reserved" 2 "Reserved" 1 "Warning" 0 "No Warning" ;
VAL_ 902 CMRR_RR2_St_DOW 7 "reserved" 6 "reserved" 5 "reserved" 4 "Failure" 3 "Active" 2 "Standby" 1 "Off" 0 "Init" ;
VAL_ 902 CMRR_RR2_St_BSD_LCA 7 "reserved" 6 "reserved" 5 "reserved" 4 "Failure" 3 "Active" 2 "Standby" 1 "Off" 0 "Init" ;
VAL_ 902 CMRR_RR2_St_Blindness 3 "Rear Left and Right Blindness" 2 "Rear Right Blindness" 1 "Rear Left Blindness" 0 "No Blindness" ;
VAL_ 902 CMRR_RR2_St_Calibration 7 "reserved" 6 "reserved" 5 "reserved" 4 "reserved" 3 "Unknow" 2 "Missalignment_detected" 1 "Calibration_in_process" 0 "Calibration" ;
VAL_ 902 CMRR_RR2_SwFb_RCTA 3 "Left and Right on" 2 "Right on" 1 "Left on" 0 "off" ;
VAL_ 902 CMRR_RR2_SwFb_RCTB 3 "Left and Right on" 2 "Right on" 1 "Left on" 0 "off" ;
VAL_ 902 CMRR_RR2_SwFb_BSD_LCA 3 "Left and Right on" 2 "Right on" 1 "Left on" 0 "off" ;
VAL_ 902 CMRR_RR2_SwFb_DOW 3 "Left and Right on" 2 "Right on" 1 "Left on" 0 "off" ;
VAL_ 640 EMS5_F_BrakePedal 1 "Invalid" 0 "Valid" ;
VAL_ 640 EMS5_St_BrakePedal 1 "Pressed" 0 "No Pressed" ;
VAL_ 640 EMS5_St_LimpHome 1 "Limp home" 0 "Normal" ;
VAL_ 792 WCBS_ESP1_St_AutoHoldAvailable 1 "Available" 0 "Not available" ;
VAL_ 792 WCBS_ESP1_St_AutoHold 1 "Active" 0 "Not Active" ;
VAL_ 792 WCBS_ESP1_St_AutoHoldTelltale 1 "Fail" 0 "Not Fail" ;
VAL_ 792 WCBS_ESP1_Cmd_EPBPark 3 "Not  used" 2 "Apply park Brake" 1 "Release park Brake" 0 "No request" ;
VAL_ 792 WCBS_ESP1_St_TCSActive 1 "Active" 0 "Not Active" ;
VAL_ 792 WCBS_ESP1_St_BrakeLightControl 1 "Inactive" 0 "Active" ;
VAL_ 792 WCBS_ESP1_St_ABSActive 1 "ABS actually operating" 0 "ABS Standby" ;
VAL_ 792 WCBS_ESP1_St_EBDActive 1 "EBD actually operating" 0 "EBD Standby" ;
VAL_ 792 WCBS_ESP1_St_ESPFailureTelltale 1 "Telltale requested" 0 "No telltale requested" ;
VAL_ 792 WCBS_ESP1_St_ESPTCSOffTelltale 3 "VDC&TCS OFF；" 2 "VDC&P-TCS OFF；" 1 "VDC OFF；" 0 "No telltale requested；" ;
VAL_ 792 WCBS_ESP1_St_DecelerationActive 1 "Active" 0 "No Active" ;
VAL_ 792 WCBS_ESP1_St_ABSTelltale 1 "Telltale requested" 0 "No telltale requested" ;
VAL_ 792 WCBS_ESP1_St_EBDTelltale 1 "Telltale requested" 0 "No telltale requested" ;
VAL_ 792 WCBS_ESP1_St_ESPActive 1 "Active" 0 "Not Active" ;
VAL_ 792 WCBS_ESP1_St_ESPTCSActiveTelltale 1 "Telltale requested" 0 "No telltale requested" ;
VAL_ 792 WCBS_ESP1_St_HDCTelltale 3 "Error" 2 "Sparkling" 1 "Active" 0 "Inactive" ;
VAL_ 792 WCBS_ESP1_St_WCBSFault 3 "冗余系统故障" 2 "点亮仪表制动系统红灯" 1 "点亮仪表制动系统黄灯" 0 "无故障" ;
VAL_ 792 WCBS_ESP1_St_BrakeFluidW 1 "Active" 0 "Inactive" ;
VAL_ 288 WCBS_ESP2_St_EngineIntervention 1 "intervention" 0 "no intervention" ;
VAL_ 288 WCBS_ESP2_St_BrakeIntervention 1 "intervention" 0 "no intervention" ;
VAL_ 288 WCBS_ESP2_St_EngineDragTor 1 "Engine drag torque control active" 0 "Engine drag torque control not active" ;
VAL_ 1600 WCBS_ESP3_F_FLWheelSpeed 3 "Not used" 2 "Not used" 1 "Invalid" 0 "Value OK" ;
VAL_ 1600 WCBS_ESP3_N_FLWheelSpeed 16383 "Invalid" ;
VAL_ 1600 WCBS_ESP3_F_FRWheelSpeed 3 "Not used" 2 "Not used" 1 "Invalid" 0 "Value OK" ;
VAL_ 1600 WCBS_ESP3_N_FRWheelSpeed 16383 "Invalid" ;
VAL_ 1616 WCBS_ESP4_N_BrakePedalStroke 255 "Invalid" ;
VAL_ 1616 WCBS_ESP4_F_BrakePedalStroke 1 "Invalid" 0 "Valid" ;
VAL_ 1616 WCBS_ESP4_F_RLWheelSpeed 3 "Not used" 2 "Not used" 1 "Invalid" 0 "Value OK" ;
VAL_ 1616 WCBS_ESP4_N_RLWheelSpeed 16383 "Invalid" ;
VAL_ 1616 WCBS_ESP4_F_RRWheelSpeed 3 "Not used" 2 "Not used" 1 "Invalid" 0 "Value OK" ;
VAL_ 1616 WCBS_ESP4_N_RRWheelSpeed 16383 "Invalid" ;
VAL_ 785 WCBS_ESP5_St_VehicleStandstill 3 "reserved" 2 "Invalid (short unavailability, max 3s)" 1 "standstill" 0 "not standstill" ;
VAL_ 785 WCBS_ESP5_St_APAVLC 10 "Invalid" 9 "Reserved" 8 "Reserved" 7 "Reserved" 6 "Reserved" 5 "Reserved" 4 "automatic park" 3 "emergencybrake" 2 "comfortbrake" 1 "standby" 0 "off" ;
VAL_ 785 WCBS_ESP5_St_APACDDActive 1 "active" 0 "not active" ;
VAL_ 785 WCBS_ESP5_St_GearInhit 1 "Prevent gearshift" 0 "Use normal shift pattern" ;
VAL_ 785 WCBS_ESP5_F_VehicleSpeed 1 "Valid" 0 "Invalid" ;
VAL_ 785 WCBS_ESP5_St_APACDDAv 1 "available" 0 "not available" ;
VAL_ 785 WCBS_ESP5_St_NoBrakeForce 1 "no brk force" 0 "exist brk force" ;
VAL_ 785 WCBS_ESP5_St_ACCCDDActive 1 "activated" 0 "not activated" ;
VAL_ 785 WCBS_ESP5_St_ACCCDDAv 1 "available" 0 "not available" ;
VAL_ 785 WCBS_ESP5_St_ABAactive 1 "activated" 0 "not activated" ;
VAL_ 785 WCBS_ESP5_St_ABAavailable 1 "available" 0 "not available" ;
VAL_ 785 WCBS_ESP5_St_PrefillActive 1 "activated" 0 "not activated" ;
VAL_ 785 WCBS_ESP5_St_PrefillAvailable 1 "available" 0 "not available" ;
VAL_ 785 WCBS_ESP5_St_AEBdecActive 1 "activated" 0 "not activated" ;
VAL_ 785 WCBS_ESP5_St_AEBdecAv 1 "available" 0 "not available" ;
VAL_ 785 WCBS_ESP5_St_DecSupportAc 1 "activated" 0 "not activated" ;
VAL_ 785 WCBS_ESP5_St_DecSupportAv 1 "available" 0 "not available" ;
VAL_ 785 WCBS_ESP5_AWBactive 1 "activated" 0 "not activated" ;
VAL_ 785 WCBS_ESP5_AWBavailable 1 "available" 0 "not available" ;
VAL_ 785 WCBS_ESP5_QDCFail 1 "error" 0 "no error" ;
VAL_ 785 WCBS_ESP5_BrakeOverheat 1 "Temperature too high" 0 "Not high" ;
VAL_ 785 WCBS_ESP5_N_VehicleSpeed 8191 "Invalid" ;
VAL_ 785 WCBS_ESP5_St_APALCFailure 7 "Error" 6 "Unexpected Accelerator Pedal" 5 "Unexptected Gear Intervention" 4 "Limit Slope" 3 "Unexpected EPB Action" 2 "Unexpected Gear position" 1 "Vehicle blocked" 0 "No Error" ;
VAL_ 785 WCBS_ESP5_St_APAVLCAv 1 "available" 0 "not available" ;
VAL_ 785 WCBS_ESP5_St_TCSOffTelltale 1 "TCS off" 0 "Inactive" ;
VAL_ 1008 WCBS_ESP6_F_LongitudeAcc 1 "Invalid" 0 "Valid" ;
VAL_ 1008 WCBS_ESP6_F_LateralAcc 1 "Invalid" 0 "Valid" ;
VAL_ 1008 WCBS_ESP6_F_YawVelocity 1 "Invalid" 0 "Valid" ;
VAL_ 1008 WCBS_ESP6_F_BrakePressure 1 "Invalid" 0 "Valid" ;
VAL_ 1008 WCBS_ESP6_N_LongitudeAcc 4095 "Invalid" ;
VAL_ 1008 WCBS_ESP6_FCTB_avaliable 1 "available" 0 "not available" ;
VAL_ 1008 WCBS_ESP6_RCTB_avaliable 1 "available" 0 "not available" ;
VAL_ 1008 WCBS_ESP6_N_LateralAcc 255 "Invalid" ;
VAL_ 1008 WCBS_ESP6_N_YawVelocity 8191 "Invalid" ;
VAL_ 1008 WCBS_ESP6_N_BrakePressure 255 "Invalid" ;
VAL_ 579 WCBS_ESP10_F_FRPulse 1 "Invalid" 0 "Valid" ;
VAL_ 579 WCBS_ESP10_F_FLPulse 1 "Invalid" 0 "Valid" ;
VAL_ 579 WCBS_ESP10_F_RRPulse 1 "Invalid" 0 "Valid" ;
VAL_ 579 WCBS_ESP10_F_RLPulse 1 "Invalid" 0 "Valid" ;
VAL_ 579 WCBS_ESP10_St_HBA 1 "Active" 0 "Inactive" ;
VAL_ 579 WCBS_ESP10_St_HHC 1 "Active" 0 "Inactive" ;
VAL_ 578 WCBS_ESP13_St_VDCFail 1 "Fail present (lamp on)" 0 "Not present" ;
VAL_ 578 WCBS_ESP13_St_BrakePedal 1 "Press" 0 "Not press" ;
VAL_ 578 WCBS_ESP13_St_TCSFail 1 "Fail present (lamp on)" 0 "Not present" ;
VAL_ 578 WCBS_ESP13_St_ACCVLCActive 1 "Active" 0 "Not active" ;
VAL_ 578 WCBS_ESP13_St_VLCAvailable 1 "Available" 0 "Not available" ;
VAL_ 578 WCBS_ESP13_St_VLCFail 1 "Error" 0 "No error" ;
VAL_ 578 WCBS_ESP13_N_VLCITA 255 "Invalid" ;
VAL_ 578 WCBS_ESP13_St_LHFWDD 7 "Reserved" 6 "Reserved" 5 "Reserved" 4 "Invalid" 3 "Stop" 2 "Backward" 1 "Forward" 0 "Init" ;
VAL_ 578 WCBS_ESP13_St_RHFWDD 7 "Reserved" 6 "Reserved" 5 "Reserved" 4 "Invalid" 3 "Stop" 2 "Backward" 1 "Forward" 0 "Init" ;
VAL_ 578 WCBS_ESP13_St_DCFail 1 "Error" 0 "No error" ;
VAL_ 578 WCBS_ESP13_St_LHRWDD 7 "Reserved" 6 "Reserved" 5 "Reserved" 4 "Invalid" 3 "Stop" 2 "Backward" 1 "Forward" 0 "Init" ;
VAL_ 578 WCBS_ESP13_St_RHRWDD 7 "Reserved" 6 "Reserved" 5 "Reserved" 4 "Invalid" 3 "Stop" 2 "Backward" 1 "Forward" 0 "Init" ;
VAL_ 578 WCBS_ESP13_St_CCOActive 3 "Error" 2 "Active" 1 "Standby" 0 "Inactive" ;
VAL_ 784 EPB1_St_WarningLamp 2 "Blinking" 1 "ON" 0 "OFF" ;
VAL_ 784 EPB1_St_ActuatorStL 7 "Adjust" 6 "Hold" 5 "Broken" 4 "Maintenance brake off" 3 "Closing" 2 "Brake Off" 1 "Brake On" 0 "Opening" ;
VAL_ 784 EPB1_St_ActuatorStR 7 "Adjust" 6 "Hold" 5 "Broken" 4 "Maintenance brake off" 3 "Closing" 2 "Brake Off" 1 "Brake On" 0 "Opening" ;
VAL_ 784 EPB1_St_EPBSwitch 3 "Invalid" 2 "Apply" 1 "Release" 0 "Neutral" ;
VAL_ 784 EPB1_Cmd_CruiseControlCancel 1 "Request" 0 "No request" ;
VAL_ 784 EPB1_St_DynamicApply 3 "Degrade Apply" 2 "RWU active" 1 "ECD request active" 0 "Not Active" ;
VAL_ 784 EPB1_St_EARFail 1 "error in EPB (no external apply allowed)" 0 "no error in EPB (external apply available)" ;
VAL_ 784 EPB1_St_ParkBrake 3 "unknown" 2 "both brakes in operation (applying/releasing)" 1 "both brakes applied" 0 "both brakes released" ;
VAL_ 1297 ATS_Cmd_RqPerChassis 1 "active" 0 "not active" ;
VAL_ 1297 PdcuDrvModCfmd 15 "Fault" 14 "ATS sys not initialized" 13 "Reserved" 12 "狂暴" 11 "单踏板" 10 "Wade 涉水" 9 "Rock 岩石" 8 "Slip Mud 浅泥" 7 "Mud 深泥" 6 "Sand 沙地" 5 "Cross 穿越" 4 "Deep Snow 深雪" 3 "Snow 浅雪" 2 "Comfort 舒适" 1 "ECO 经济" 0 "Sport 运动" ;
VAL_ 384 EPS_SAS_St_Calibrated 1 "Calibrated" 0 "Not calibrated" ;
VAL_ 384 EPS_SAS_St_SensorInfo 1 "Sensor information valid" 0 "Sensor information invalid,an internal sensor fault occurred" ;
VAL_ 384 EPS_SAS_N_RotationSpeed 255 "Invalid" ;
VAL_ 384 EPS_SAS_N_SteeringAngle 65535 "Invalid" ;
VAL_ 384 EPS_St_DrvStrInterDeteToADAS 1 "Interference（干预）" 0 "Not Interference（未干预）" ;
VAL_ 384 EPS_F_DrvStrInterDeteToADAS 1 "Invalid（无效）" 0 "Valid（有效）" ;
VAL_ 384 EPS_SysAvlSts_APA 7 "Reserved" 6 "Reserved" 5 "Reserved" 4 "Irreversible failure" 3 "Ready" 2 "Active" 1 "Available for control" 0 "Temporary inhibit" ;
VAL_ 384 EPS_APA_FuncMode 7 "Reserved" 6 "Reserved" 5 "Reserved" 4 "Active_HPA" 3 "Active_MRA" 2 "Active_ RPA" 1 "Active_APA" 0 "None" ;
VAL_ 384 EPS_AbortFb 15 "Abort Reason" 14 "Abort Reason" 13 "Abort Reason" 12 "Abort Reason" 11 "Abort Reason" 10 "Abort Reason" 9 "Other Abort Reasons" 8 "Handshaking time out" 7 "Vehilce speed exceeds limits when in control" 6 "EPS internal failure" 5 "APA control singal invaild or timeout" 4 "StrWhlAng invalid" 3 "StrWhlAngSpd out of limit" 2 "StrWhlAng out of limit" 1 "Driver interference StrWhl" 0 "No abort" ;
VAL_ 384 EPS_EPSAvl 3 "Reserved" 2 "Failure 失败" 1 "Available" 0 "Not Available" ;
VAL_ 384 EPS_OverrangeFeedback 7 "reserved" 6 "reserved" 5 "reserved" 4 "reserved" 3 "Torque overrange" 2 "angle speed  overrange" 1 "angle overrange" 0 "Not overrange" ;
VAL_ 384 EPS_SteerWorkStatus 3 "Reserved" 2 "Torque control" 1 "Angle control" 0 "Power steer" ;
VAL_ 848 SDM1_St_AirbagDeployed 1 "crash" 0 "no crash" ;
VAL_ 323 EPS1_St_FailSts 3 "Reserved" 2 "Intermittent Error Detected" 1 "Permant Error Detected" 0 "No Fault" ;
VAL_ 323 EPS1_St_SteerMod 3 "Reserved" 2 "Sport  Mode" 1 "Standard Mode" 0 "Handy Mode" ;
VAL_ 323 EPS1_St_TrqSnsrSts 1 "Abnormal" 0 "Normal" ;
VAL_ 323 EPS1_St_DrvStrInterDete 1 "Interference（干预）" 0 "Not Interference（未干预）" ;
VAL_ 323 EPS1_F_DrvStrInterDete 1 "Invalid（无效）；" 0 "Valid（有效）；" ;
VAL_ 323 EPS1_St_Requestfeedback 3 "Permanently Failed(永久失效)" 2 "Active（正处于被控制状态）" 1 "Avalibale For Contorl（可控）" 0 "Temporary Inhibit（暂时不可控）" ;
VAL_ 323 EPS1_St_EPSControl 3 "control request not allowed(permanent)" 2 "control request not allowed(temporarily)" 1 "request honored" 0 "no request" ;
VAL_ 323 EPS1_F_ReqTorqueFeedack 1 "Valid" 0 "Invalid" ;
VAL_ 323 EPS1_St_DSTEPSControl 3 "control request not allowed(permanent)" 2 "control request not allowed(temporarily)" 1 "request honored" 0 "no request" ;
VAL_ 323 EPS1_F_DSTReqTorFeedackValid 1 "Valid" 0 "Invalid" ;
VAL_ 323 EPS1_DrvInpTrqVld 1 "Valid" 0 "Invalid" ;
VAL_ 816 CSS1_F_AVMSw 1 "Invalid" 0 "Valid" ;
VAL_ 816 CSS1_Sw_AVM 1 "Press" 0 "Release" ;
VAL_ 1314 EHC1_Set_FPAS 1 "ON" 0 "OFF" ;
VAL_ 1314 EHC1_Set_LanguageSetting 15 "Reserve" 14 "Reserve" 13 "Reserve" 12 "Reserve" 11 "Reserve" 10 "Reserve" 9 "Reserve" 8 "Reserve" 7 "Reserve" 6 "Reserve" 5 "Reserve" 4 "Reserve" 3 "Arabic" 2 "Spanish" 1 "English" 0 "Chinese" ;
VAL_ 1314 EHC1_Set_ThemeMode 3 "reserved" 2 "reserved" 1 "off road长途越野" 0 "cross长途穿越" ;
VAL_ 1315 EHC3_Set_FCWOption 4 "OFF" 3 "HighSensitivity" 2 "MiddleSensitivity" 1 "LowSensitivity" 0 "Not active" ;
VAL_ 1315 EHC3_Set_LKASen 4 "OFF" 3 "HighSensitivity" 2 "MiddleSensitivity" 1 "LowSensitivity" 0 "Not active" ;
VAL_ 1315 EHC3_Set_AEB 3 "Reserved" 2 "Not active" 1 "ON" 0 "Off" ;
VAL_ 1315 EHC3_Set_TSR 3 "Invalid" 2 "OFF" 1 "ON" 0 "Inactive" ;
VAL_ 1315 EHC3_Set_TJA_ICA_ACC 3 "reserved" 2 "ACC_TJA_ICA on" 1 "ACC_TJA_ICA off" 0 "Not active" ;
VAL_ 1315 EHC3_Set_LDWSen 4 "OFF" 3 "HighSensitivity" 2 "MiddleSensitivity" 1 "LowSensitivity" 0 "Not active" ;
VAL_ 1319 EHC6_St_Navigation 3 "Cruise Status" 2 "Open" 1 "Close" 0 "Invalid" ;
VAL_ 1319 EHC6_Set_LanguageSetting 15 "Reserve" 14 "Reserve" 13 "Reserve" 12 "Reserve" 11 "Reserve" 10 "Reserve" 9 "Reserve" 8 "Reserve" 7 "Reserve" 6 "Reserve" 5 "Reserve" 4 "Reserve" 3 "Arabic" 2 "Spanish" 1 "English" 0 "Chinese" ;
VAL_ 1319 EHC6_TiMod 7 "Invalid" 6 "Reserved" 5 "Reserved" 4 "24 hour" 3 "PM" 2 "AM" 1 "No display" 0 "reserved" ;
VAL_ 1319 EHC6_DateWeek 15 "Invalid" 14 "Reserved" 13 "Reserved" 12 "Reserved" 11 "Reserved" 10 "Reserved" 9 "Reserved" 8 "Reserved" 7 "Sunday" 6 "Saturday" 5 "Friday" 4 "Thursday" 3 "Wednesday" 2 "Tuesday" 1 "Monday" 0 "reserved" ;
VAL_ 1766 EHC11_St_TrailerFcnActive 3 "reserved（Mode2（拖车模式二（挂平板）））" 2 "active（Mode1（拖车模式一（挂拖车）））" 1 "inactive （Off mode（OFF））" 0 "no change （无触发）" ;
VAL_ 1766 IccSentiModReq 3 "Invalid" 2 "Not active" 1 "Active" 0 "Initialize" ;
VAL_ 1766 CDC_Cmd_CampGuardee 7 "Reserved" 6 "Reserved" 5 "Reserved" 4 "Reserved" 3 "Reserved" 2 "关闭" 1 "开启" 0 "Initial" ;
VAL_ 1766 IccSentiModSts 7 "Invalid" 6 "reserved" 5 "reserved" 4 "Pre Active（预开启）" 3 "Suspend（暂停）" 2 "Active" 1 "Not active" 0 "Initialize" ;
VAL_ 1568 IPC1_F_OdometerParameter 1 "Value unreliable" 0 "Value OK" ;
VAL_ 1568 IPC1_St_QDashACCFail 3 "not defined" 2 "irreversible error" 1 "reversible error" 0 "no error" ;
VAL_ 1568 IPC1_St_DISFail 1 "error" 0 "no error" ;
VAL_ 1568 ICC_PrivacyAgreementSwt 3 "reserve" 2 "同意" 1 "拒绝" 0 "default" ;
VAL_ 1392 CAPE1_F_PowerMode 2 "Valid" 1 "Invalid" 0 "Not available" ;
VAL_ 1392 CAPE1_St_PowerMode 5 "Crank Off(Reserve)" 4 "Crank（上Ready认证过程）" 3 "Crank Pending(Reserve)" 2 "Run（ON）" 1 "Acc（取消）" 0 "Off" ;
VAL_ 1392 CAPE1_St_PepsRemPwrMod 7 "invalid" 6 "reserved" 5 "RPA bluetooth motion control mode" 4 "bluetooth start" 3 "bluetooth control" 2 "remote start" 1 "remote control" 0 "initialing/normal mode" ;
VAL_ 1184 BCM1_Cmd_PositionLamp 1 "ON" 0 "OFF" ;
VAL_ 1184 BCM1_Sw_TurnLeftLamp 1 "ON" 0 "OFF" ;
VAL_ 1184 BCM1_Sw_TurnRightLamp 1 "ON" 0 "OFF" ;
VAL_ 1184 BCM1_St_HazzardFlash 1 "Active" 0 "Not active" ;
VAL_ 1184 BCM1_St_HighBeam 1 "Fault" 0 "Normal" ;
VAL_ 1184 BCM1_Cmd_LeftTurnLamp 1 "ON" 0 "OFF" ;
VAL_ 1184 BCM1_St_LeftTurnLamp 1 "Fault" 0 "Normal" ;
VAL_ 1184 BCM1_Cmd_RightTurnLamp 1 "ON" 0 "OFF" ;
VAL_ 1184 BCM1_St_RightTurnLamp 1 "Fault" 0 "Normal" ;
VAL_ 1184 BCM1_St_PositionLamp 1 "Fault" 0 "Normal" ;
VAL_ 1184 BCM1_St_AntiThelfIndication 5 "Trunk Disarm（尾门解防）" 4 "Alarm（报警）" 3 "Remind（提醒）" 2 "Prep.Arm（预设防）" 1 "Arm（设防）" 0 "Disarm（解防）" ;
VAL_ 1184 BCM1_St_LFDoorLock 1 "Door unlocked" 0 "Door locked" ;
VAL_ 1184 BCM1_St_PasDoorLock 1 "Door unlocked" 0 "Door locked" ;
VAL_ 1184 BCM1_St_DriverDoor 1 "Door open" 0 "Door closed" ;
VAL_ 1184 BCM1_St_PassengerDoor 1 "Door open" 0 "Door closed" ;
VAL_ 1184 BCM1_St_LRDoor 1 "Door open" 0 "Door closed" ;
VAL_ 1184 BCM1_St_RRDoor 1 "Door open" 0 "Door closed" ;
VAL_ 1184 BCM1_St_TrunkDoor 1 "Open" 0 "Closed" ;
VAL_ 1184 BCM1_St_Hood 1 "Open" 0 "Close" ;
VAL_ 1184 BCM1_Sw_Brake 1 "Active" 0 "Not active" ;
VAL_ 1184 BCM1_Sw_ReverseGear 1 "Active" 0 "Not active" ;
VAL_ 1184 BCM1_St_LowBeam 1 "Fault" 0 "Normal" ;
VAL_ 1184 BCM1_Cmd_BrakeLamp 1 "Active" 0 "Inactive" ;
VAL_ 1184 BCM1_Cmd_HazardInd 1 "ON" 0 "OFF" ;
VAL_ 1184 BCM1_Cmd_HighBeam 1 "ON" 0 "OFF" ;
VAL_ 1184 BCM1_Cmd_LowBeam 1 "ON" 0 "OFF" ;
VAL_ 1184 BCM1_St_BrakeFluidLowWarning 1 "Warning" 0 "No warning" ;
VAL_ 1184 BCM1_St_DRL 3 "Reserved" 2 "Fault" 1 "ON" 0 "OFF" ;
VAL_ 1184 BCM1_Cmd_FrontFoglamp 1 "ON" 0 "OFF" ;
VAL_ 1184 BCM1_St_FrontFoglamp 1 "Fault" 0 "Normal" ;
VAL_ 1184 BCM1_Cmd_RearFoglamp 1 "ON" 0 "OFF" ;
VAL_ 1184 BCM1_St_RearFoglamp 1 "Fault" 0 "Normal" ;
VAL_ 1203 BCM2_St_FrontWiper 7 "FAULT" 6 "Reserved" 5 "Reserved" 4 "Reserved" 3 "Trigger(RESERVED)" 2 "High Speed" 1 "Low Speed" 0 "OFF" ;
VAL_ 1203 BCM2_St_LRDoorLock 1 "Door unlock" 0 "Door locked" ;
VAL_ 1203 BCM2_St_RRDoorLock 1 "Door unlock" 0 "Door locked" ;
VAL_ 866 BCM4_St_DRSeatbelt 1 "Buckled" 0 "Not buckled；" ;
VAL_ 866 BCM4_St_PASeatbelt 1 "Warning；" 0 "Not warning" ;
VAL_ 866 BCM4_St_RLSeatbelt 1 "Warning；" 0 "Not warning" ;
VAL_ 866 BCM4_St_RRSeatbelt 1 "Warning；" 0 "Not warning" ;
VAL_ 866 BCM4_St_RMSeatbelt 1 "Warning；" 0 "Not warning" ;
VAL_ 866 BCM4_Sw_PositionLamp 1 "ON" 0 "OFF" ;
VAL_ 866 BCM4_Sw_LowLamp 1 "ON" 0 "OFF" ;
VAL_ 866 BCM4_Sw_HighLamp 1 "ON" 0 "OFF" ;
VAL_ 866 BCM4_Sw_AutoLamp 1 "ON" 0 "OFF" ;
VAL_ 866 BCM4_Sw_FlashLamp 1 "ON" 0 "OFF" ;
VAL_ 866 BCM4_St_HBA 1 "ON" 0 "OFF" ;
VAL_ 866 BCM4_Sw_RearFogLamp 1 "Active" 0 "Inactive" ;
VAL_ 1383 BCM9_St_LightSoundInhibition 3 "安全抑制" 2 "自动声光动抑制" 1 "自动声光动抑制+安全抑制" 0 "初始值" ;
VAL_ 1380 DLF1_St_LmirrorFold 3 "Reserved" 2 "Fault" 1 "Fold" 0 "Unfold；" ;
VAL_ 1382 DRF1_St_RmirrorFold 3 "Reserved" 2 "Fold" 1 "Unfold" 0 "Inactive" ;
VAL_ 1328 AC1_F_OutsideTemp 3 "Invalid" 2 "Value above upper limit" 1 "Value below lower limit" 0 "Value OK（default）" ;
VAL_ 324 PdcuRdySt 1 "Ready" 0 "NotReady" ;
VAL_ 324 PdcuDrvCycDetc 1 "detected" 0 "No detected" ;
VAL_ 324 PdcuWrmupCycDetec 1 "detected" 0 "No detected" ;
VAL_ 324 PdcuEspVehSpd 65535 "Invalid" ;
VAL_ 324 PdcuEnrgMod 7 "Reserved" 6 "Reserved" 5 "电量自定义" 4 "强制纯电" 3 "自动模式" 2 "优先用电" 1 "优先用油" 0 "Inactive" ;
VAL_ 324 PdcuSelGearVld 3 "Value unreliable" 2 "Reserved" 1 "Reserved" 0 "Value OK" ;
VAL_ 324 PdcuSelGear 7 "Invalid value" 6 "Blank" 5 "S(RESERVED)" 4 "M" 3 "D" 2 "N" 1 "R" 0 "P" ;
VAL_ 324 PdcuTqFltFlg 1 "异常" 0 "正常" ;
VAL_ 324 PdcuActvDchaEnaFlg 3 "Invalid" 2 "使能" 1 "不使能" 0 "初始值" ;
VAL_ 324 PdcuVehAllwRefrshFlg 3 "Void" 2 "禁止刷写" 1 "允许刷写" 0 "初始值" ;
VAL_ 324 PdcuStrtActv 1 "start in processing" 0 "not in start processing" ;
VAL_ 324 PdcuAccrPedl1VoltVld 1 "Vaild" 0 "Invalid" ;
VAL_ 267 PdcuAccPedalPosVld 1 "Invalid" 0 "Vaild" ;
VAL_ 267 PdcuAccPedalPosDigVld 1 "Invalid" 0 "Vaild" ;
VAL_ 267 PdcuEbrEnFlg 2 "Not Active" 1 "Active" 0 "void" ;
VAL_ 267 PdcuEbrReqFlg 2 "Not Active" 1 "Active" 0 "void" ;
VAL_ 267 PdcuEbrStandstillFlg 2 "Not Active request Standstill" 1 "Active request Standstill" 0 "void" ;
VAL_ 267 PdcuAccDriverOverride 1 "Active（指示ACC过程中驾驶员请求扭矩＞VLC）" 0 "Not Active" ;
VAL_ 267 PdcuEcAvailable 1 "Fail（指示无法正常响应外部扭矩请求）" 0 "Normal（默认正常响应ACC—VLC或APA—VLC扭矩请求）" ;
VAL_ 267 PdcuApaShiftAvailable 1 "Available" 0 "Not Available" ;
VAL_ 267 PdcuApaLeverIntervention 1 "Active" 0 "Not Active" ;
VAL_ 290 PdcuFrntAxleTrqReqVld 1 "Valid" 0 "Invalid" ;
VAL_ 290 PdcuFrntAxleTrqActVld 1 "Valid" 0 "Invalid" ;
VAL_ 290 PdcuFrntAxleTrqMaxLimVld 1 "Valid" 0 "Invalid" ;
